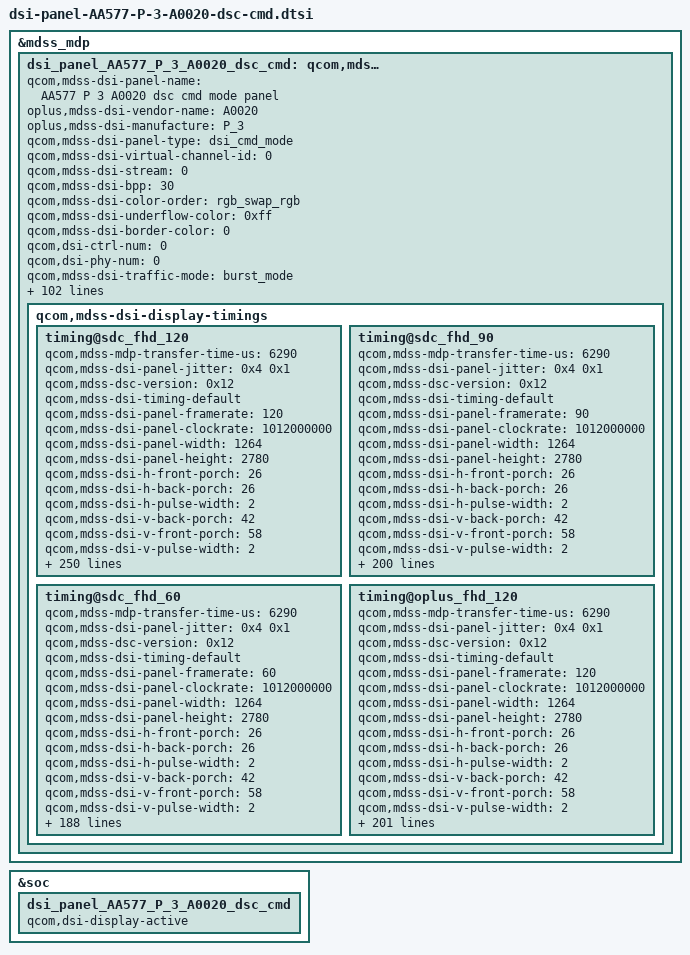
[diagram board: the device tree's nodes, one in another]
&mdss_mdp {
	dsi_panel_AA577_P_3_A0020_dsc_cmd: qcom,mdss_dsi_panel_AA577_P_3_A0020_dsc_cmd {
		qcom,mdss-dsi-panel-name = "AA577 P 3 A0020 dsc cmd mode panel";
		oplus,mdss-dsi-vendor-name = "A0020";
		oplus,mdss-dsi-manufacture = "P_3";
		qcom,mdss-dsi-panel-type = "dsi_cmd_mode";
		qcom,mdss-dsi-virtual-channel-id = <0>;
		qcom,mdss-dsi-stream = <0>;
		qcom,mdss-dsi-bpp = <30>;
		qcom,mdss-dsi-color-order = "rgb_swap_rgb";
		qcom,mdss-dsi-underflow-color = <0xff>;
		qcom,mdss-dsi-border-color = <0>;
		qcom,dsi-ctrl-num = <0>;
		qcom,dsi-phy-num = <0>;
		qcom,mdss-dsi-traffic-mode = "burst_mode";
		qcom,mdss-dsi-lane-map = "lane_map_0123";
		qcom,mdss-dsi-bllp-eof-power-mode;
		qcom,mdss-dsi-bllp-power-mode;
		qcom,mdss-dsi-lane-0-state;
		qcom,mdss-dsi-lane-1-state;
		qcom,mdss-dsi-lane-2-state;
		qcom,mdss-dsi-lane-3-state;
		qcom,mdss-dsi-dma-trigger = "trigger_sw";
		qcom,mdss-dsi-dma-schedule-line = <1>;
		qcom,mdss-dsi-dma-schedule-window = <10>;
		qcom,mdss-dsi-mdp-trigger = "none";
		qcom,mdss-dsi-reset-sequence = <1 2>, <0 5>, <1 25>;
		qcom,mdss-dsi-te-pin-select = <1>;
		qcom,mdss-dsi-te-dcs-command = <1>;
		qcom,mdss-pan-physical-width-dimension = <71>;
		qcom,mdss-pan-physical-height-dimension = <157>;
		qcom,mdss-dsi-init-delay-us = <1000>;
		qcom,mdss-dsi-te-check-enable;
		qcom,mdss-dsi-te-using-te-pin;
		//qcom,mdss-dsi-lp11-init;
		qcom,mdss-dsi-wr-mem-start = <0x2c>;
		qcom,mdss-dsi-wr-mem-continue = <0x3c>;
		qcom,mdss-dsi-panel-jitter = <0x4 0x1>;
		qcom,mdss-bl-high2bit;
		/* HDR Setting */
		qcom,mdss-dsi-panel-hdr-enabled;
		qcom,mdss-dsi-panel-hdr-color-primaries = <15635 16450 34000 16000 13250 34500 7500 3000>;
		qcom,mdss-dsi-panel-peak-brightness = <5400000>;
		qcom,mdss-dsi-panel-average-brightness = <2000000>;
		qcom,mdss-dsi-panel-blackness-level = <4000>;

		qcom,esd-check-enabled;
		oplus,esd-check-flag-enabled;
		qcom,mdss-dsi-panel-status-check-mode = "reg_read";
		qcom,mdss-dsi-panel-status-command = [
				06 01 00 01 05 00 02 0A 00
			];
		qcom,mdss-dsi-panel-status-command-state = "dsi_lp_mode";
		qcom,mdss-dsi-panel-status-value = <
				0x9C
		>;
		qcom,mdss-dsi-panel-status-read-length = <1>;
		oplus,mdss-dsi-panel-status-match-modes = <0x00000000>;
		qcom,dynamic-mode-switch-enabled;
		qcom,dynamic-mode-switch-type = "dynamic-resolution-switch-immediate";
		qcom,mdss-dsi-display-timings {
			timing@sdc_fhd_120 {
				#include "dsi-panel-AA577-P-3-A0020-common-effect.dtsi"
				#include "dsi-panel-AA577-P-3-A0020-common.dtsi"
				qcom,mdss-mdp-transfer-time-us = <6290>;
				qcom,mdss-dsi-panel-jitter = <0x4 0x1>;
				qcom,mdss-dsc-version = <0x12>;
				qcom,mdss-dsi-timing-default;
				qcom,mdss-dsi-panel-framerate = <120>;
				qcom,mdss-dsi-panel-clockrate = <1012000000>;
				qcom,mdss-dsi-panel-width = <1264>;
				qcom,mdss-dsi-panel-height = <2780>;

				qcom,mdss-dsi-h-front-porch = <26>;
				qcom,mdss-dsi-h-back-porch = <26>;
				qcom,mdss-dsi-h-pulse-width = <2>;
				qcom,mdss-dsi-v-back-porch = <42>;
				qcom,mdss-dsi-v-front-porch = <58>;
				qcom,mdss-dsi-v-pulse-width = <2>;
				qcom,mdss-dsi-h-sync-pulse = <0>;

				oplus,ofp-need-to-sync-data-in-aod-unlocking;
				oplus,ofp-aod-off-insert-black-frame = <1>;
				oplus,ofp-aod-off-black-frame-total-time = <42>;
				oplus,ofp-need-to-separate-backlight;
				oplus,ofp-backlight-on-period = <1>;

				qcom,mdss-dsi-timing-switch-command = [
						39 00 00 40 00 00 04 FF 5A A5 00
						15 00 00 40 00 00 02 60 00
						/* recover to narrow TE */
						39 00 00 40 00 00 04 FF 5A A5 02
						39 00 00 40 00 00 09 B0 00 80 00 10 00 00 00 00
						39 00 00 40 00 00 04 FF 5A A5 2D
						39 00 00 40 00 00 03 83 00 00
						15 00 00 40 00 00 02 F2 00
						39 00 00 00 00 00 04 FF 5A A5 00
				];
				qcom,mdss-dsi-on-command = [
						39 00 00 40 00 00 04 FF 5A A5 08
						15 00 00 40 00 00 02 C8 62
						39 00 00 40 00 00 04 FF 5A A5 07
						15 00 00 40 00 00 02 8A 01
						39 00 00 40 00 00 03 8B 21 E0
						39 00 00 40 00 00 64 81 00 00 00 00 00 12 00 00 AB 30 80 0A DC 04 F0 00 14 02 78 02 78 02 00 02 57 00 20 01 F8 00 08 00 0D 05 7A 04 4F 18 00 10 E0 07 10 20 00 06 0F 0F 33 0E 1C 2A 38 46 54 62 69 70 77 79 7B 7D 7E 02 02 22 00 2A 40 2A BE 3A FC 3A FA 3A F8 3B 38 3B 78 3B B6 4B B6 4B F4 4B F4 6C 34 84 74 00 00 00 00 00 00
						// CTB optimize
						39 00 00 40 00 00 04 FF 5A A5 31
						15 00 00 40 00 00 02 D0 81
						15 00 00 40 01 00 02 A0 A3
						39 00 00 40 00 00 13 84 F0 98 62 24 02 FE DC 9E 68 F0 25 21 28 02 FE DF CA 65
						39 00 00 40 01 00 13 85 F0 6F 47 1B 02 FE E5 B9 91 F0 27 22 2A 02 FE DE EB AC
						15 00 00 40 00 00 02 D0 80
						39 00 00 40 00 00 04 FF 5A A5 21
						15 00 00 40 00 00 02 A4 18
						39 00 00 40 00 00 04 FF 5A A5 2D
						15 00 00 40 00 00 02 F2 00
						39 00 00 40 00 00 03 83 00 00
						39 00 00 40 00 00 03 84 00 00
						39 00 00 40 00 00 03 85 00 00
						39 00 00 40 00 00 03 86 00 00
						39 00 00 40 00 00 04 FF 5A A5 00
						15 00 00 40 00 00 02 5A 01
						15 00 00 40 00 00 02 5B 80
						39 00 00 40 00 00 04 FF 5A A5 02
						15 00 00 40 00 00 02 C0 03
						39 00 00 40 00 00 04 FF 5A A5 2D //Page 2D
						15 00 00 40 00 00 02 CE D4
						39 00 00 40 00 00 04 EC 01 AF 00
						39 00 00 40 00 00 03 93 A0 00
						39 00 00 40 00 00 03 94 C4 00
						39 00 00 40 00 00 03 95 00 00
						39 00 00 40 00 00 03 96 00 00
						39 00 00 40 00 00 03 ED D5 00
						39 00 00 40 00 00 04 EE 00 00 00
						15 00 00 40 00 00 02 97 02
						15 00 00 40 00 00 02 B1 03
						39 00 00 40 00 00 03 98 05 00
						39 00 00 40 00 00 03 99 0B 00
						39 00 00 40 00 00 03 9A 17 00
						39 00 00 40 00 00 03 9B 77 00
						39 00 00 40 00 00 05 A0 01 01 00 00
						39 00 00 40 00 00 05 A1 02 00 00 00
						15 00 00 40 00 00 02 B2 02
						15 00 00 40 00 00 02 B3 05
						15 00 00 40 00 00 02 B4 08
						15 00 00 40 00 00 02 B5 11
						39 00 00 40 00 00 03 BA 00 00
						39 00 00 40 00 00 03 BB 01 02
						39 00 00 40 00 00 04 FF 5A A5 02
						39 00 00 40 00 00 09 B0 00 80 00 10 00 00 00 00
						39 00 00 40 00 00 04 FF 5A A5 00
						15 00 00 40 00 00 02 5E 01
						15 00 00 40 00 00 02 60 00
						15 00 00 40 00 00 02 61 07
						15 00 00 40 00 00 02 35 00
						15 00 00 40 00 00 02 53 20
						//ODC 2024/8/3
						39 00 00 40 00 00 04 FF 5A A5 49
						15 00 00 40 00 00 02 D9 02
						15 00 00 40 00 00 02 DA F7
						15 00 00 40 00 00 02 DB 9C
						15 00 00 40 00 00 02 DF 06
						39 00 00 40 00 00 04 FF 5A A5 5A
						39 00 00 40 00 00 04 81 FD 00 00
						39 00 00 40 00 00 04 83 03 15 05
						39 00 00 40 00 00 04 84 02 FD 01
						39 00 00 40 00 00 04 85 02 FD 01
						39 00 00 40 00 00 04 86 12 2B 1A
						39 00 00 40 00 00 04 87 0A FD 05
						39 00 00 40 00 00 04 88 08 FD 04
						39 00 00 40 00 00 04 89 03 FD 06
						39 00 00 40 00 00 04 8A 16 31 27
						39 00 00 40 00 00 04 8D 06 05 15
						39 00 00 40 00 00 04 8E 01 05 05
						39 00 00 40 00 00 04 93 FA 06 06
						39 00 00 40 00 00 04 94 FA 05 00
						39 00 00 40 00 00 04 95 32 50 3C
						39 00 00 40 00 00 04 A4 03 01 02
						39 00 00 40 00 00 04 A5 08 0D 0A
						39 00 00 40 00 00 04 A6 00 00 00
						39 00 00 40 00 00 04 A7 06 0D 0A
						39 00 00 40 00 00 04 A9 01 00 00
						39 00 00 40 00 00 04 B5 07 06 05
						39 00 00 40 00 00 04 B6 02 01 01
						39 00 00 40 00 00 04 B7 F9 F3 08
						39 00 00 40 00 00 04 B8 F7 F4 08
						39 00 00 40 00 00 04 C9 03 08 05
						39 00 00 40 00 00 04 CB 04 09 05
						39 00 00 40 00 00 04 D9 08 08 06
						39 00 00 40 00 00 04 DA 02 02 01
						39 00 00 40 00 00 04 DB F7 F6 01
						39 00 00 40 00 00 04 DC F7 F6 01
						39 00 00 40 00 00 04 FF 5A A5 5B
						39 00 00 40 00 00 04 80 01 0D 07
						39 00 00 40 00 00 04 81 04 08 05
						39 00 00 40 00 00 04 83 06 09 06
						39 00 00 40 00 00 04 93 06 06 06
						39 00 00 40 00 00 04 94 FC FC FC
						39 00 00 40 00 00 04 9A 06 07 05
						39 00 00 40 00 00 04 9B 04 04 03
						39 00 00 40 00 00 04 A5 03 0C 08
						39 00 00 40 00 00 04 A7 04 0D 07
						39 00 00 40 00 00 04 B5 FE FD FC
						39 00 00 40 00 00 04 B6 FB FA FA
						39 00 00 40 00 00 04 B7 F6 F6 F6
						39 00 00 40 00 00 04 C9 03 07 05
						39 00 00 40 00 00 04 CA 00 02 00
						39 00 00 40 00 00 04 CB 04 09 05
						39 00 00 40 00 00 04 DB 01 06 06
						39 00 00 40 00 00 04 DC 01 05 06
						39 00 00 40 00 00 04 E2 05 05 05
						39 00 00 40 00 00 04 E3 03 04 03
						39 00 00 40 00 00 04 FF 5A A5 5C
						39 00 00 40 00 00 04 80 04 04 05
						39 00 00 40 00 00 04 81 02 05 01
						39 00 00 40 00 00 04 83 04 04 06
						39 00 00 40 00 00 04 94 01 01 06
						39 00 00 40 00 00 04 9A 06 0C 0B
						39 00 00 40 00 00 04 9B 06 0C 0C
						39 00 00 40 00 00 04 A5 03 05 04
						39 00 00 40 00 00 04 B7 FA 02 04
						39 00 00 40 00 00 04 B8 FA 02 00
						39 00 00 40 00 00 04 BE 03 06 03
						39 00 00 40 00 00 04 BF 03 06 02
						39 00 00 00 00 00 04 FF 5A A5 00
						//CTB 2024/8/3
						39 00 00 40 00 00 04 FF 5A A5 31
						15 00 00 40 01 00 02 D0 81
						39 00 00 40 00 00 13 80 F0 99 62 25 02 FE DB 9E 67 E0 1A 17 16 00 00 DF C8 C4
						39 00 00 40 00 00 13 81 F0 9C 65 25 02 FE DB 9B 64 E0 09 08 05 00 00 FD F4 EC
						39 00 00 40 00 00 13 82 F0 81 53 1F 02 FE E1 AD 7F E0 07 06 05 00 00 FD FC FB
						39 00 00 40 00 00 13 83 F0 70 48 1B 02 FE E5 B8 90 E0 07 06 05 00 00 FD FC FB
						39 00 00 40 00 00 13 84 F0 94 60 23 02 FE DD A0 6C E0 06 05 04 00 00 FB FA F9
						39 00 00 40 00 00 13 85 F0 7C 50 1E 02 FE E2 B0 84 E0 06 05 04 00 00 FB FA F9
						39 00 00 40 00 00 13 86 F0 99 62 25 02 FE DB 9E 67 E0 1A 17 16 00 00 CD C8 C4
						39 00 00 40 00 00 13 87 F0 9C 65 25 02 FE DB 9B 64 E0 09 08 05 00 00 FD F4 EC
						39 00 00 40 00 00 13 88 F0 81 53 1F 02 FE E1 AD 7F E0 07 06 05 00 00 FD FC FB
						39 00 00 40 00 00 13 89 F0 70 48 1B 02 FE E5 B8 90 E0 07 06 05 00 00 FD FC FB
						39 00 00 40 00 00 13 8A F0 94 60 23 02 FE DD A0 6C E0 06 05 04 00 00 FB FA F9
						39 00 00 40 00 00 13 8B F0 7C 50 1E 02 FE E2 B0 84 E0 06 05 04 00 00 FB FA F9
						15 00 00 40 01 00 02 D0 80
						39 00 00 40 00 00 07 91 04 44 55 01 01 03
						39 00 00 40 00 00 07 92 04 44 55 01 01 03
						39 00 00 40 00 00 07 93 04 44 55 01 01 03
						15 00 00 40 00 00 02 A6 00
						15 00 00 40 00 00 02 A7 10
						15 00 00 40 00 00 02 A8 00
						15 00 00 40 00 00 02 A9 10
						15 00 00 40 00 00 02 AA 00
						15 00 00 40 00 00 02 AB 10
						39 00 00 40 00 00 04 FF 5A A5 00
						//CCTC 2024/8/3
						39 00 00 40 00 00 04 FF 5A A5 2B
						39 00 00 40 00 00 05 AA 30 F7 00 00
						39 00 00 40 00 00 05 AD 30 F9 00 00
						39 00 00 40 00 00 05 B0 30 FA 00 00
						39 00 00 40 00 00 05 C4 0F 04 FB F1
						39 00 00 40 00 00 05 C5 3F DE E4 E4
						39 00 00 40 00 00 05 C7 3F F8 FD F5
						39 00 00 40 00 00 05 C8 3F E2 E9 E9
						39 00 00 40 00 00 05 CA 0F 02 E5 E8
						39 00 00 40 00 00 05 CB 3F ED EF ED
						39 00 00 40 00 00 05 CD 03 02 00 FB
						39 00 00 40 00 00 05 DF 0F 04 F1 F6
						39 00 00 40 00 00 05 E0 3F D2 EB EE
						39 00 00 40 00 00 05 E2 3F F5 F0 F8
						39 00 00 40 00 00 05 E3 3F E2 EE E2
						39 00 00 40 00 00 05 E6 3F FE F3 F4
						39 00 00 40 00 00 05 E9 3F FD F7 F5
						39 00 00 40 00 00 05 EC 3F FD FA F7
						39 00 00 00 00 00 04 FF 5A A5 00
						//Resolving 60Hz stuttering
						39 00 00 40 00 00 04 FF 5A A5 00
						39 00 00 40 00 00 02 5A 01
						39 00 00 40 00 00 02 5B 80
						39 00 00 40 00 00 04 FF 5A A5 02
						39 00 00 40 00 00 02 C0 03
						39 00 00 40 00 00 04 FF 5A A5 2D
						39 00 00 40 00 00 04 EC 01 AF 00
						39 00 00 40 00 00 03 93 A0 00
						39 00 00 40 00 00 03 94 C4 00
						39 00 00 40 00 00 03 95 00 00
						39 00 00 40 00 00 03 96 00 00
						39 00 00 40 00 00 03 ED D5 00
						39 00 00 40 00 00 04 EE 00 00 00
						39 00 00 40 00 00 02 97 02
						39 00 00 40 00 00 02 B1 03
						39 00 00 40 00 00 03 98 05 00
						39 00 00 40 00 00 03 99 0B 00
						39 00 00 40 00 00 03 9A 17 00
						39 00 00 40 00 00 03 9B 77 00
						39 00 00 40 00 00 05 A0 01 01 00 00
						39 00 00 40 00 00 05 A1 02 00 00 00
						39 00 00 40 00 00 02 B2 02
						39 00 00 40 00 00 02 B3 05
						39 00 00 40 00 00 02 B4 08
						39 00 00 40 00 00 02 B5 11
						39 00 00 40 00 00 03 BA 00 00
						39 00 00 40 00 00 03 BB 01 02
						39 00 00 40 00 00 04 FF 5A A5 02
						39 00 00 40 00 00 09 B0 00 80 00 10 00 00 00 00
						//cornor on
						39 00 00 40 00 00 04 FF 5A A5 17
						15 00 00 40 00 00 02 A0 8C
						// switch 120HZ
						39 00 00 40 00 00 04 FF 5A A5 00
						15 00 00 40 00 00 02 60 00
						39 00 00 40 00 00 04 FF 5A A5 2D
						39 00 00 40 00 00 03 83 00 00
						15 00 00 40 00 00 02 F2 00
						39 00 00 40 00 00 04 FF 5A A5 00
						05 00 00 00 78 00 01 11
						39 00 00 40 00 00 04 FF 5A A5 23
						15 00 00 40 00 00 02 CB 01
						39 00 00 40 00 00 04 FF 5A A5 65
						39 00 00 40 00 00 09 98 00 00 41 05 00 00 41 05
						39 00 00 40 00 00 09 99 00 00 41 05 00 00 41 05
						39 00 00 40 00 00 09 9A 00 00 41 05 00 00 41 05
						39 00 00 40 00 00 09 9B 00 00 01 1E 00 00 64 1E
						39 00 00 40 00 00 09 9C 00 00 76 1E 00 00 D8 1E
						39 00 00 40 00 00 09 9D 00 00 EA 1E 00 01 32 1E
						39 00 00 40 00 00 09 9E 00 01 32 1E 00 01 32 1E
						39 00 00 40 00 00 09 9F 00 01 40 1E 00 01 C0 1E
						39 00 00 40 00 00 09 A0 00 01 D0 1E 00 02 CE 1E
						39 00 00 40 00 00 09 A1 00 02 CE 1E 00 03 98 1E
						39 00 00 40 00 00 09 A2 00 03 98 1E 00 04 2E 1E
						39 00 00 40 00 00 09 A3 00 04 2E 1E 00 04 B0 1E
						39 00 00 40 00 00 09 A4 00 04 B0 1E 00 04 B0 1E
						39 00 00 40 00 00 09 A5 00 04 B0 1E 00 04 B0 1E
						39 00 00 40 00 00 09 A6 00 04 B0 1E 00 04 B0 1E
						39 00 00 40 00 00 09 A7 00 04 B0 1E 00 04 B0 1E
						39 00 00 40 00 00 09 A8 00 04 B0 1E 00 04 B0 1E
						39 00 00 40 00 00 09 A9 00 04 B0 1E 00 04 B0 1E
						39 00 00 40 00 00 09 AA 00 04 B0 1E 00 04 B0 1E
						39 00 00 40 00 00 09 AB 00 04 B0 1E 00 04 B0 1E
						39 00 00 40 00 00 09 AC 00 04 B0 1E 00 04 B0 1E
						39 00 00 40 00 00 09 AD 00 04 B0 1E 00 04 B0 1E
						39 00 00 40 00 00 09 AE 00 04 B0 1E 00 04 B0 1E
						39 00 00 40 00 00 09 AF 00 04 B0 1E 00 04 B0 1E
						39 00 00 40 00 00 04 FF 5A A5 75
						39 00 00 40 00 00 09 98 00 00 00 00 00 00 0F 00
						39 00 00 40 00 00 09 99 00 00 00 00 00 00 0F 00
						39 00 00 40 00 00 09 9A 00 00 00 00 00 00 0F 00
						39 00 00 40 00 00 09 9B 00 00 00 00 00 00 10 00
						39 00 00 40 00 00 09 9C 00 00 00 00 00 00 10 00
						39 00 00 40 00 00 09 9D 00 00 00 00 00 00 10 00
						39 00 00 40 00 00 09 9E 00 00 00 00 00 00 10 00
						39 00 00 40 00 00 09 9F 00 00 00 00 00 00 10 00
						39 00 00 40 00 00 09 A0 00 00 00 00 00 00 10 00
						39 00 00 40 00 00 09 A1 00 00 00 00 00 00 10 00
						39 00 00 40 00 00 09 A2 00 00 00 00 00 00 10 00
						39 00 00 40 00 00 09 A3 00 00 00 00 00 00 10 00
						39 00 00 40 00 00 09 A4 00 00 00 00 00 00 10 00
						39 00 00 40 00 00 09 A5 00 00 00 00 00 00 10 00
						39 00 00 40 00 00 09 A6 00 00 00 00 00 00 10 00
						39 00 00 40 00 00 09 A7 00 00 00 00 00 00 10 00
						39 00 00 40 00 00 09 A8 00 00 00 00 00 00 10 00
						39 00 00 40 00 00 09 A9 00 00 00 00 00 00 10 00
						39 00 00 40 00 00 09 AA 00 00 00 00 00 00 10 00
						39 00 00 40 00 00 09 AB 00 00 00 00 00 00 10 00
						39 00 00 40 00 00 09 AC 00 00 00 00 00 00 10 00
						39 00 00 40 00 00 09 AD 00 00 00 00 00 00 10 00
						39 00 00 40 00 00 09 AE 00 00 00 00 00 00 10 00
						39 00 00 40 00 00 09 AF 00 00 00 00 00 00 10 00
						39 00 00 40 00 00 04 FF 5A A5 23
						15 00 00 00 00 00 02 CB 00
						05 00 00 00 14 00 01 29
				];

				qcom,mdss-dsi-post-on-backlight = [
				];
				qcom,mdss-dsi-off-command=[
					05 00 00 00 14 00 01 28
					05 00 00 00 78 00 01 10
				];
				qcom,mdss-dsi-hbm-off-command = [
					39 00 00 00 00 00 03 51 0D BB
				];
				qcom,mdss-dsi-hbm-on-command = [
					39 00 00 40 00 00 04 FF 5A A5 1E
					39 00 00 40 00 00 02 80 89
					39 00 00 40 00 00 04 FF 5A A5 00
					39 00 00 00 00 00 03 51 0F 4A
				];
				qcom,mdss-dsi-panel-read-register-open-command = [
				];
				qcom,mdss-dsi-panel-read-register-close-command = [
				];
				qcom,mdss-dsi-lhbm-pressed-icon-gamma-command = [
				];
				qcom,mdss-dsi-lhbm-pressed-icon-grayscale-command = [
				];
				qcom,mdss-dsi-lhbm-pressed-icon-on-command = [
					39 00 00 40 00 00 04 FF 5A A5 00
					39 00 00 40 00 00 02 96 09
					39 00 00 40 00 00 02 97 D9
					39 00 00 40 00 00 02 98 02
					39 00 00 40 00 00 02 99 78
					39 00 00 00 00 00 02 6E 03
				];
				qcom,mdss-dsi-lhbm-pressed-icon-off-command = [
					39 00 00 40 00 00 04 FF 5A A5 00
					39 00 00 00 00 00 02 6E 00
				];
				qcom,mdss-dsi-lhbm-dbv-alpha-command = [
				];
				qcom,mdss-dsi-lp1-command = [
					39 00 00 40 00 00 04 FF 5A A5 4F
					15 00 00 40 00 00 02 88 78
					39 00 00 40 00 00 04 FF 5A A5 00
					15 00 00 40 00 00 02 60 00
					39 00 00 40 00 00 04 FF 5A A5 53
					39 00 00 40 00 00 03 85 CC E1
					39 00 00 40 00 00 04 FF 5A A5 01
					39 00 00 40 00 00 06 83 00 00 40 04 00
					15 00 00 40 00 00 02 FE 0B
					39 00 00 40 00 00 04 FF 5A A5 0B
					15 00 00 40 00 00 02 88 00
					15 00 00 40 00 00 02 A7 00
					39 00 00 40 00 00 04 FF 5A A5 51
					39 00 00 40 00 00 06 C2 46 46 46 46 00
					15 00 00 40 00 00 02 FE 00
					15 00 00 40 00 00 02 00 00
					39 00 00 40 00 00 04 FF 5A A5 00
					15 00 00 40 00 00 02 39 00
					39 00 00 40 00 00 04 FF 5A A5 4F
					15 00 00 40 00 00 02 8B 78
					/* AOD lv switch */
					39 00 00 40 00 00 04 FF 5A A5 00
					39 00 00 00 00 00 05 51 0D BB 0D BB
				];
				qcom,mdss-dsi-nolp-command = [
					39 00 00 40 00 00 04 FF 5A A5 00
					15 00 00 40 00 00 02 38 00
					39 00 00 00 00 00 05 51 00 00 00 00
				];
				qcom,mdss-dsi-nolp-onepulse-command = [
					39 00 00 40 00 00 04 FF 5A A5 4F
					15 00 00 40 00 00 02 88 78
					39 00 00 40 00 00 04 FF 5A A5 01
					39 00 00 40 00 00 03 80 0C 0C
					39 00 00 40 00 00 04 FF 5A A5 4F
					15 00 00 40 00 00 02 8A 78
					39 00 00 40 00 00 04 FF 5A A5 00
					15 00 00 40 00 00 02 60 01
					39 00 00 40 00 00 04 FF 5A A5 53
					39 00 00 40 00 00 03 85 CC E3
					39 00 00 40 00 00 04 FF 5A A5 01
					39 00 00 40 00 00 06 83 00 00 40 04 00
					15 00 00 40 00 00 02 FE 07
					39 00 00 40 00 00 04 FF 5A A5 0B
					15 00 00 40 00 00 02 88 46
					15 00 00 40 00 00 02 A7 3A
					39 00 00 40 00 00 04 FF 5A A5 51
					39 00 00 40 00 00 06 C2 46 28 28 28 00
					15 00 00 40 00 00 02 FE 00
					15 00 00 40 00 00 02 00 00
					39 00 00 40 00 00 04 FF 5A A5 01
					39 00 00 40 00 00 03 80 0C 00
					39 00 00 40 00 00 04 FF 5A A5 00
					15 00 00 40 00 00 02 38 00
					39 00 00 40 00 00 04 FF 5A A5 4F
					15 00 00 40 00 00 02 8B 78
					39 00 00 40 00 00 04 FF 5A A5 00
					39 00 00 00 00 00 05 51 00 00 00 00
				];
				qcom,mdss-dsi-aod-high-mode-command = [
					39 00 00 40 00 00 04 FF 5A A5 00
					39 00 00 00 00 00 05 51 0D BB 0D BB
				];
				qcom,mdss-dsi-aod-low-mode-command = [
					39 00 00 40 00 00 04 FF 5A A5 00
					39 00 00 00 00 00 05 51 0B 1A 0A 81
				];
				qcom,mdss-dsi-ultra-low-power-aod-on-command = [
					39 00 00 40 00 00 04 FF 5A A5 2D
					39 00 00 40 00 00 03 8A 1D 00
					39 00 00 00 00 00 04 FF 5A A5 00
				];
				qcom,mdss-dsi-ultra-low-power-aod-off-command = [
					39 00 00 40 00 00 04 FF 5A A5 2D
					39 00 00 40 00 00 03 8A 00 00
					39 00 00 00 00 00 04 FF 5A A5 00
				];
				qcom,mdss-dsi-temperature-compensation-command = [
				];
				qcom,mdss-dsi-read-compensation-reg1-command = [
				];
				qcom,mdss-dsi-pwm-switch-high-command = [
					39 00 00 40 00 00 04 FF 5A A5 4F
					15 00 00 40 00 00 02 80 01
					15 00 00 40 00 00 02 81 04
					15 00 00 40 00 00 02 88 78
					39 00 00 40 00 00 04 FF 5A A5 00
					39 00 00 40 00 00 03 51 04 8B
					39 00 00 40 00 00 04 FF 5A A5 24
					39 00 00 40 00 00 06 C9 00 00 00 10 00
					39 00 00 40 00 00 04 FE 30 00 50
					39 00 00 40 00 00 06 CA 00 80 00 B0 00
					39 00 00 40 00 00 04 FE D0 01 10
					39 00 00 40 00 00 06 CB 01 50 01 78 01
					39 00 00 40 00 00 04 FE D0 02 98
					39 00 00 40 00 00 06 CC 03 20 04 40 05
					39 00 00 40 00 00 04 FE 20 05 E8
					39 00 00 40 00 00 06 CD 06 F0 07 C8 09
					39 00 00 40 00 00 04 FE 30 0A A8
					39 00 00 40 00 00 06 CE 0B 70 0C D8 0E
					39 00 00 40 00 00 04 FE F0 0F F0
					39 00 00 40 00 00 04 FF 5A A5 4F
					15 00 00 40 00 00 02 8A 78
					39 00 00 40 00 00 04 FF 5A A5 24
					39 00 00 40 00 00 06 C9 00 00 00 10 00
					39 00 00 40 00 00 04 FE 30 00 50
					39 00 00 40 00 00 06 CA 00 80 00 B0 00
					39 00 00 40 00 00 04 FE D0 01 10
					39 00 00 40 00 00 06 CB 01 50 01 B0 02
					39 00 00 40 00 00 04 FE 10 02 B0
					39 00 00 40 00 00 06 CC 03 70 04 70 05
					39 00 00 40 00 00 04 FE 70 06 30
					39 00 00 40 00 00 06 CD 07 10 08 10 09
					39 00 00 40 00 00 04 FE 80 0A F0
					39 00 00 40 00 00 06 CE 0B A0 0D 10 0E
					39 00 00 40 00 00 04 FE F0 0F F0
					39 00 00 40 00 00 04 FF 5A A5 4F
					15 00 00 00 00 00 02 8B 78
				];
				qcom,mdss-dsi-pwm-switch-low-command = [
					39 00 00 40 00 00 04 FF 5A A5 4F
					15 00 00 40 00 00 02 80 01
					15 00 00 40 00 00 02 81 04
					15 00 00 40 00 00 02 88 78
					39 00 00 40 00 00 04 FF 5A A5 00
					39 00 00 40 00 00 03 51 04 8A
					39 00 00 40 00 00 04 FF 5A A5 24
					39 00 00 40 00 00 06 C9 00 00 00 10 00
					39 00 00 40 00 00 04 FE 30 00 50
					39 00 00 40 00 00 06 CA 00 80 00 B0 00
					39 00 00 40 00 00 04 FE D0 01 20
					39 00 00 40 00 00 06 CB 01 68 01 A0 02
					39 00 00 40 00 00 04 FE 28 02 D0
					39 00 00 40 00 00 06 CC 03 60 04 A0 05
					39 00 00 40 00 00 04 FE B0 06 78
					39 00 00 40 00 00 06 CD 07 30 08 50 09
					39 00 00 40 00 00 04 FE E0 0B 44
					39 00 00 40 00 00 06 CE 0B D8 0D 10 0E
					39 00 00 40 00 00 04 FE F0 0F F0
					39 00 00 40 00 00 04 FF 5A A5 4F
					15 00 00 40 00 00 02 8A 78
					39 00 00 40 00 00 04 FF 5A A5 24
					39 00 00 40 00 00 06 C9 00 00 00 10 00
					39 00 00 40 00 00 04 FE 30 00 50
					39 00 00 40 00 00 06 CA 00 80 00 B0 00
					39 00 00 40 00 00 04 FE D0 01 10
					39 00 00 40 00 00 06 CB 01 50 01 B0 02
					39 00 00 40 00 00 04 FE 10 02 B0
					39 00 00 40 00 00 06 CC 03 70 04 70 05
					39 00 00 40 00 00 04 FE 70 06 30
					39 00 00 40 00 00 06 CD 07 10 08 10 09
					39 00 00 40 00 00 04 FE 80 0A F0
					39 00 00 40 00 00 06 CE 0B A0 0D 10 0E
					39 00 00 40 00 00 04 FE F0 0F F0
					39 00 00 40 00 00 04 FF 5A A5 4F
					15 00 00 00 00 00 02 8B 78
				];
				qcom,mdss-dsi-pwm-switch-onepulse-command = [
				];
				qcom,mdss-dsi-pwm-switch-onepulse-low-command = [
				];
				qcom,mdss-dsi-pwm-switch-1to3-command = [
					39 00 00 40 00 00 04 FF 5A A5 4F
					15 00 00 40 00 00 02 88 78
					39 00 00 40 00 00 04 FF 5A A5 01
					39 00 00 40 00 00 06 83 00 00 40 04 00
					15 00 00 40 00 00 02 FE 0B
					39 00 00 40 00 00 04 FF 5A A5 0B
					15 00 00 40 00 00 02 88 00
					15 00 00 40 00 00 02 A7 00
					39 00 00 40 00 00 04 FF 5A A5 51
					39 00 00 40 00 00 06 C2 46 46 46 46 00
					15 00 00 40 00 00 02 FE 00
					15 00 00 40 00 00 02 00 00
					39 00 00 40 00 00 06 A0 98 98 A4 A8 22
					15 00 00 40 00 00 02 FE 22
					15 00 00 40 00 00 02 00 00
					39 00 00 40 00 00 06 A1 CC D0 D0 A2 22
					15 00 00 40 00 00 02 FE 22
					15 00 00 40 00 00 02 00 00
					39 00 00 40 00 00 06 A2 A4 A6 99 9A 22
					15 00 00 40 00 00 02 FE 22
					15 00 00 40 00 00 02 00 00
					39 00 00 40 00 00 04 FF 5A A5 52
					39 00 00 40 00 00 06 80 DA BC 58 B1 11
					15 00 00 40 00 00 02 FE 01
					15 00 00 40 00 00 02 00 00
					39 00 00 40 00 00 06 81 4D 4D 4D 4E 00
					15 00 00 40 00 00 02 FE 00
					15 00 00 40 00 00 02 00 00
					39 00 00 40 00 00 06 82 4D 4E 4D 4D 00
					15 00 00 40 00 00 02 FE 00
					15 00 00 40 00 00 02 00 00
					39 00 00 40 00 00 04 FF 5A A5 00
					15 00 00 40 00 00 02 60 00
					39 00 00 40 00 00 04 FF 5A A5 4F
					15 00 00 40 00 00 02 8B 78
					39 00 00 40 00 00 04 FF 5A A5 53
					15 00 00 40 00 00 02 F0 01
					39 00 00 40 00 00 04 FF 5A A5 63
					39 00 00 40 00 00 11 F1 00 00 00 00 00 00 00 00 00 00 00 00 00 00 00 00
					39 00 00 40 00 00 11 F2 10 10 10 10 10 00 00 00 00 00 00 00 00 00 00 00
					39 00 00 40 00 00 11 F3 00 00 00 00 00 20 20 20 20 20 00 00 00 00 00 00
					39 00 00 40 00 00 11 F4 00 00 00 00 00 FF FF FF FF FF 00 00 00 00 00 00
					39 00 00 40 00 00 04 FF 5A A5 53
					15 00 00 40 00 00 02 F0 00
					39 00 00 00 00 00 04 FF 5A A5 00
				];
				qcom,mdss-dsi-pwm-switch-3to1-command = [
					39 00 00 40 00 00 04 FF 5A A5 4F
					15 00 00 40 00 00 02 88 78
					39 00 00 40 00 00 04 FF 5A A5 01
					39 00 00 40 00 00 03 80 0C 0C
					39 00 00 40 00 00 04 FF 5A A5 4F
					15 00 00 40 00 00 02 8A 78
					39 00 00 40 00 00 04 FF 5A A5 01
					39 00 00 40 00 00 06 83 00 00 40 04 00
					15 00 00 40 00 00 02 FE 07
					39 00 00 40 00 00 04 FF 5A A5 0B
					15 00 00 40 00 00 02 88 46
					15 00 00 40 00 00 02 A7 3A
					39 00 00 40 00 00 04 FF 5A A5 51
					39 00 00 40 00 00 06 C2 46 28 28 28 00
					15 00 00 40 00 00 02 FE 00
					15 00 00 40 00 00 02 00 00
					39 00 00 40 00 00 06 A0 98 98 6C 69 22
					15 00 00 40 00 00 02 FE 22
					15 00 00 40 00 00 02 00 00
					39 00 00 40 00 00 06 A1 8C 91 91 74 22
					15 00 00 40 00 00 02 FE 22
					15 00 00 40 00 00 02 00 00
					39 00 00 40 00 00 06 A2 68 72 72 72 22
					15 00 00 40 00 00 02 FE 22
					15 00 00 40 00 00 02 00 00
					39 00 00 40 00 00 04 FF 5A A5 52
					// VRR
					39 00 00 40 00 00 06 80 DA BC 49 A5 11
					15 00 00 40 00 00 02 FE 01
					15 00 00 40 00 00 02 00 00
					39 00 00 40 00 00 06 81 3D 3E 3E 3F 00
					15 00 00 40 00 00 02 FE 00
					15 00 00 40 00 00 02 00 00
					39 00 00 40 00 00 06 82 41 23 23 23 00
					15 00 00 40 00 00 02 FE 00
					15 00 00 40 00 00 02 00 00
					39 00 00 40 00 00 04 FF 5A A5 00
					15 00 00 40 00 00 02 60 01
					39 00 00 40 00 00 04 FF 5A A5 01
					39 00 00 40 00 00 03 80 0C 00
					39 00 00 40 00 00 04 FF 5A A5 4F
					15 00 00 40 00 00 02 8B 78
					39 00 00 40 00 00 04 FF 5A A5 53
					15 00 00 40 00 00 02 F0 01
					39 00 00 40 00 00 04 FF 5A A5 63
					39 00 00 40 00 00 11 F1 20 20 20 20 20 20 20 20 20 20 00 00 00 00 00 00
					39 00 00 40 00 00 11 F2 00 00 00 00 00 00 00 00 00 00 00 00 00 00 00 00
					39 00 00 40 00 00 11 F3 00 00 00 00 00 00 00 00 00 00 00 00 00 00 00 00
					39 00 00 40 00 00 11 F4 FF FF FF FF FF FF FF FF FF FF 00 00 00 00 00 00
					39 00 00 40 00 00 04 FF 5A A5 53
					15 00 00 40 00 00 02 F0 00
					39 00 00 00 00 00 04 FF 5A A5 00
				];
				qcom,mdss-dsi-timming-pwm-switch-onepulse-command = [
					39 00 00 40 00 00 04 FF 5A A5 00
					15 00 00 40 00 00 02 60 01
					39 00 00 40 00 00 04 FF 5A A5 2D
					39 00 00 40 00 00 03 84 00 00
					15 00 00 40 00 00 02 CE D4
					15 00 00 40 00 00 02 F2 00
					39 00 00 00 00 00 04 FF 5A A5 00
				];
				qcom,mdss-dsi-power-on-pwm-switch-onepulse-command = [
					39 00 00 40 00 00 04 FF 5A A5 4F
					15 00 00 40 00 00 02 88 78
					39 00 00 40 00 00 04 FF 5A A5 01
					39 00 00 40 00 00 03 80 0C 0C
					39 00 00 40 00 00 04 FF 5A A5 4F
					15 00 00 40 00 00 02 8A 78
					39 00 00 40 00 00 04 FF 5A A5 01
					39 00 00 40 00 00 06 83 00 00 40 04 00
					15 00 00 40 00 00 02 FE 07
					39 00 00 40 00 00 04 FF 5A A5 0B
					15 00 00 40 00 00 02 88 46
					15 00 00 40 00 00 02 A7 3A
					39 00 00 40 00 00 04 FF 5A A5 51
					39 00 00 40 00 00 06 C2 46 28 28 28 00
					15 00 00 40 00 00 02 FE 00
					15 00 00 40 00 00 02 00 00
					39 00 00 40 00 00 06 A0 98 98 6C 69 22
					15 00 00 40 00 00 02 FE 22
					15 00 00 40 00 00 02 00 00
					39 00 00 40 00 00 06 A1 8C 91 91 74 22
					15 00 00 40 00 00 02 FE 22
					15 00 00 40 00 00 02 00 00
					39 00 00 40 00 00 06 A2 68 72 72 72 22
					15 00 00 40 00 00 02 FE 22
					15 00 00 40 00 00 02 00 00
					39 00 00 40 00 00 04 FF 5A A5 52
					// VRR
					39 00 00 40 00 00 06 80 DA BC 49 A5 11
					15 00 00 40 00 00 02 FE 01
					15 00 00 40 00 00 02 00 00
					39 00 00 40 00 00 06 81 3D 3E 3E 3F 00
					15 00 00 40 00 00 02 FE 00
					15 00 00 40 00 00 02 00 00
					39 00 00 40 00 00 06 82 41 23 23 23 00
					15 00 00 40 00 00 02 FE 00
					15 00 00 40 00 00 02 00 00
					39 00 00 40 00 00 04 FF 5A A5 00
					15 00 00 40 00 00 02 60 01
					39 00 00 40 00 00 04 FF 5A A5 01
					39 00 00 40 00 00 03 80 0C 00
					39 00 00 40 00 00 04 FF 5A A5 4F
					15 00 00 40 00 00 02 8B 78
					39 00 00 40 00 00 04 FF 5A A5 53
					15 00 00 40 00 00 02 F0 01
					39 00 00 40 00 00 04 FF 5A A5 63
					39 00 00 40 00 00 11 F1 20 20 20 20 20 20 20 20 20 20 00 00 00 00 00 00
					39 00 00 40 00 00 11 F2 00 00 00 00 00 00 00 00 00 00 00 00 00 00 00 00
					39 00 00 40 00 00 11 F3 00 00 00 00 00 00 00 00 00 00 00 00 00 00 00 00
					39 00 00 40 00 00 11 F4 FF FF FF FF FF FF FF FF FF FF 00 00 00 00 00 00
					39 00 00 40 00 00 04 FF 5A A5 53
					15 00 00 40 00 00 02 F0 00
					39 00 00 00 10 00 04 FF 5A A5 00
				];
				qcom,mdss-dsi-osc-track-on-command = [
				];
				qcom,mdss-dsi-osc-track-off-command = [
				];
				qcom,mdss-dsi-hbm-max-command = [
					39 00 00 00 00 00 03 51 10 ED
				];

				qcom,mdss-dsi-hbm-exit-max-command = [
					39 00 00 00 00 00 03 51 0F FE
				];
				qcom,mdss-dsi-lp1-command-state = "dsi_lp_pack_mode";
				qcom,mdss-dsi-nolp-command-state = "dsi_lp_pack_mode";
				qcom,mdss-dsi-nolp-onepulse-command-state = "dsi_lp_pack_mode";
				qcom,mdss-dsi-nolp-hpwm-command-state = "dsi_lp_pack_mode";
				qcom,mdss-dsi-hbm-on-command-state = "dsi_lp_pack_mode";
				qcom,mdss-dsi-hbm-off-command-state = "dsi_lp_pack_mode";
				qcom,mdss-dsi-panel-read-register-open-state = "dsi_lp_mode";
				qcom,mdss-dsi-panel-read-register-close-state = "dsi_lp_mode";
				qcom,mdss-dsi-lhbm-pressed-icon-gamma-command-state = "dsi_lp_mode";
				qcom,mdss-dsi-lhbm-pressed-icon-grayscale-command-state = "dsi_lp_mode";
				qcom,mdss-dsi-lhbm-pressed-icon-on-command-state = "dsi_lp_mode";
				qcom,mdss-dsi-lhbm-pressed-icon-off-command-state = "dsi_lp_mode";
				qcom,mdss-dsi-lhbm-dbv-alpha-command-state = "dsi_hs_mode";

				qcom,mdss-dsi-reset-scanline-command-state = "dsi_hs_mode";
				qcom,mdss-dsi-recovery-scanline-command-state = "dsi_hs_mode";

				qcom,mdss-dsi-osc-track-on-command-state = "dsi_hs_mode";
				qcom,mdss-dsi-osc-track-off-command-state = "dsi_hs_mode";
				qcom,mdss-dsi-hbm-max-command-state = "dsi_hs_mode";
				qcom,mdss-dsi-hbm-exit-max-command-state = "dsi_hs_mode";

				qcom,lm-split = <632 632>;
				qcom,compression-mode = "dsc";
				qcom,mdss-dsc-encoders = <2>;
				qcom,mdss-dsc-slice-height = <20>;
				qcom,mdss-dsc-slice-width = <632>;
				qcom,mdss-dsc-slice-per-pkt = <2>;
				qcom,mdss-dsc-bit-per-component = <10>;
				qcom,mdss-dsc-bit-per-pixel = <8>;
				qcom,mdss-dsc-block-prediction-enable;
			};
			timing@sdc_fhd_90 {
				#include "dsi-panel-AA577-P-3-A0020-common-effect.dtsi"
				#include "dsi-panel-AA577-P-3-A0020-common.dtsi"
				qcom,mdss-mdp-transfer-time-us = <6290>;
				qcom,mdss-dsi-panel-jitter = <0x4 0x1>;
				qcom,mdss-dsc-version = <0x12>;
				qcom,mdss-dsi-timing-default;
				qcom,mdss-dsi-panel-framerate = <90>;
				qcom,mdss-dsi-panel-clockrate = <1012000000>;
				qcom,mdss-dsi-panel-width = <1264>;
				qcom,mdss-dsi-panel-height = <2780>;

				qcom,mdss-dsi-h-front-porch = <26>;
				qcom,mdss-dsi-h-back-porch = <26>;
				qcom,mdss-dsi-h-pulse-width = <2>;
				qcom,mdss-dsi-v-back-porch = <42>;
				qcom,mdss-dsi-v-front-porch = <58>;
				qcom,mdss-dsi-v-pulse-width = <2>;
				qcom,mdss-dsi-h-sync-pulse = <0>;

				oplus,ofp-need-to-sync-data-in-aod-unlocking;
				oplus,ofp-aod-off-insert-black-frame = <1>;
				oplus,ofp-aod-off-black-frame-total-time = <45>;
				oplus,ofp-need-to-separate-backlight;
				oplus,ofp-backlight-on-period = <1>;
				oplus,apollo-panel-async-bl-delay = <8000>;

				qcom,mdss-dsi-timing-switch-command = [
						39 00 00 40 00 00 04 FF 5A A5 00
						15 00 00 40 00 00 02 60 02
						/* recover to narrow TE */
						39 00 00 40 00 00 04 FF 5A A5 02
						39 00 00 40 00 00 09 B0 00 80 00 10 00 00 00 00
						39 00 00 40 00 00 04 FF 5A A5 2D
						39 00 00 40 00 00 03 85 00 00
						15 00 00 40 00 00 02 F2 00
						39 00 00 00 00 00 04 FF 5A A5 00
				];
				qcom,mdss-dsi-on-command = [
						39 00 00 40 00 00 04 FF 5A A5 08
						15 00 00 40 00 00 02 C8 62
						39 00 00 40 00 00 04 FF 5A A5 07
						15 00 00 40 00 00 02 8A 01
						39 00 00 40 00 00 03 8B 21 E0
						39 00 00 40 00 00 64 81 00 00 00 00 00 12 00 00 AB 30 80 0A DC 04 F0 00 14 02 78 02 78 02 00 02 57 00 20 01 F8 00 08 00 0D 05 7A 04 4F 18 00 10 E0 07 10 20 00 06 0F 0F 33 0E 1C 2A 38 46 54 62 69 70 77 79 7B 7D 7E 02 02 22 00 2A 40 2A BE 3A FC 3A FA 3A F8 3B 38 3B 78 3B B6 4B B6 4B F4 4B F4 6C 34 84 74 00 00 00 00 00 00
						// CTB optimize
						39 00 00 40 00 00 04 FF 5A A5 31
						15 00 00 40 00 00 02 D0 81
						15 00 00 40 01 00 02 A0 A3
						39 00 00 40 00 00 13 84 F0 98 62 24 02 FE DC 9E 68 F0 25 21 28 02 FE DF CA 65
						39 00 00 40 01 00 13 85 F0 6F 47 1B 02 FE E5 B9 91 F0 27 22 2A 02 FE DE EB AC
						15 00 00 40 00 00 02 D0 80
						39 00 00 40 00 00 04 FF 5A A5 21
						15 00 00 40 00 00 02 A4 18
						39 00 00 40 00 00 04 FF 5A A5 2D
						15 00 00 40 00 00 02 F2 00
						39 00 00 40 00 00 03 83 00 00
						39 00 00 40 00 00 03 84 00 00
						39 00 00 40 00 00 03 85 00 00
						39 00 00 40 00 00 03 86 00 00
						39 00 00 40 00 00 04 FF 5A A5 00
						15 00 00 40 00 00 02 5A 01
						15 00 00 40 00 00 02 5B 80
						39 00 00 40 00 00 04 FF 5A A5 02
						15 00 00 40 00 00 02 C0 03
						39 00 00 40 00 00 04 FF 5A A5 2D //Page 2D
						15 00 00 40 00 00 02 CE D4
						39 00 00 40 00 00 04 EC 01 AF 00
						39 00 00 40 00 00 03 93 A0 00
						39 00 00 40 00 00 03 94 C4 00
						39 00 00 40 00 00 03 95 00 00
						39 00 00 40 00 00 03 96 00 00
						39 00 00 40 00 00 03 ED D5 00
						39 00 00 40 00 00 04 EE 00 00 00
						15 00 00 40 00 00 02 97 02
						15 00 00 40 00 00 02 B1 03
						39 00 00 40 00 00 03 98 05 00
						39 00 00 40 00 00 03 99 0B 00
						39 00 00 40 00 00 03 9A 17 00
						39 00 00 40 00 00 03 9B 77 00
						39 00 00 40 00 00 05 A0 01 01 00 00
						39 00 00 40 00 00 05 A1 02 00 00 00
						15 00 00 40 00 00 02 B2 02
						15 00 00 40 00 00 02 B3 05
						15 00 00 40 00 00 02 B4 08
						15 00 00 40 00 00 02 B5 11
						39 00 00 40 00 00 03 BA 00 00
						39 00 00 40 00 00 03 BB 01 02
						39 00 00 40 00 00 04 FF 5A A5 02
						39 00 00 40 00 00 09 B0 00 80 00 10 00 00 00 00
						39 00 00 40 00 00 04 FF 5A A5 00
						15 00 00 40 00 00 02 5E 01
						15 00 00 40 00 00 02 60 00
						15 00 00 40 00 00 02 61 07
						15 00 00 40 00 00 02 35 00
						15 00 00 40 00 00 02 53 20
						//ODC 2024/8/3
						39 00 00 40 00 00 04 FF 5A A5 49
						15 00 00 40 00 00 02 D9 02
						15 00 00 40 00 00 02 DA F7
						15 00 00 40 00 00 02 DB 9C
						15 00 00 40 00 00 02 DF 06
						39 00 00 40 00 00 04 FF 5A A5 5A
						39 00 00 40 00 00 04 81 FD 00 00
						39 00 00 40 00 00 04 83 03 15 05
						39 00 00 40 00 00 04 84 02 FD 01
						39 00 00 40 00 00 04 85 02 FD 01
						39 00 00 40 00 00 04 86 12 2B 1A
						39 00 00 40 00 00 04 87 0A FD 05
						39 00 00 40 00 00 04 88 08 FD 04
						39 00 00 40 00 00 04 89 03 FD 06
						39 00 00 40 00 00 04 8A 16 31 27
						39 00 00 40 00 00 04 8D 06 05 15
						39 00 00 40 00 00 04 8E 01 05 05
						39 00 00 40 00 00 04 93 FA 06 06
						39 00 00 40 00 00 04 94 FA 05 00
						39 00 00 40 00 00 04 95 32 50 3C
						39 00 00 40 00 00 04 A4 03 01 02
						39 00 00 40 00 00 04 A5 08 0D 0A
						39 00 00 40 00 00 04 A6 00 00 00
						39 00 00 40 00 00 04 A7 06 0D 0A
						39 00 00 40 00 00 04 A9 01 00 00
						39 00 00 40 00 00 04 B5 07 06 05
						39 00 00 40 00 00 04 B6 02 01 01
						39 00 00 40 00 00 04 B7 F9 F3 08
						39 00 00 40 00 00 04 B8 F7 F4 08
						39 00 00 40 00 00 04 C9 03 08 05
						39 00 00 40 00 00 04 CB 04 09 05
						39 00 00 40 00 00 04 D9 08 08 06
						39 00 00 40 00 00 04 DA 02 02 01
						39 00 00 40 00 00 04 DB F7 F6 01
						39 00 00 40 00 00 04 DC F7 F6 01
						39 00 00 40 00 00 04 FF 5A A5 5B
						39 00 00 40 00 00 04 80 01 0D 07
						39 00 00 40 00 00 04 81 04 08 05
						39 00 00 40 00 00 04 83 06 09 06
						39 00 00 40 00 00 04 93 06 06 06
						39 00 00 40 00 00 04 94 FC FC FC
						39 00 00 40 00 00 04 9A 06 07 05
						39 00 00 40 00 00 04 9B 04 04 03
						39 00 00 40 00 00 04 A5 03 0C 08
						39 00 00 40 00 00 04 A7 04 0D 07
						39 00 00 40 00 00 04 B5 FE FD FC
						39 00 00 40 00 00 04 B6 FB FA FA
						39 00 00 40 00 00 04 B7 F6 F6 F6
						39 00 00 40 00 00 04 C9 03 07 05
						39 00 00 40 00 00 04 CA 00 02 00
						39 00 00 40 00 00 04 CB 04 09 05
						39 00 00 40 00 00 04 DB 01 06 06
						39 00 00 40 00 00 04 DC 01 05 06
						39 00 00 40 00 00 04 E2 05 05 05
						39 00 00 40 00 00 04 E3 03 04 03
						39 00 00 40 00 00 04 FF 5A A5 5C
						39 00 00 40 00 00 04 80 04 04 05
						39 00 00 40 00 00 04 81 02 05 01
						39 00 00 40 00 00 04 83 04 04 06
						39 00 00 40 00 00 04 94 01 01 06
						39 00 00 40 00 00 04 9A 06 0C 0B
						39 00 00 40 00 00 04 9B 06 0C 0C
						39 00 00 40 00 00 04 A5 03 05 04
						39 00 00 40 00 00 04 B7 FA 02 04
						39 00 00 40 00 00 04 B8 FA 02 00
						39 00 00 40 00 00 04 BE 03 06 03
						39 00 00 40 00 00 04 BF 03 06 02
						39 00 00 00 00 00 04 FF 5A A5 00
						//CTB 2024/8/3
						39 00 00 40 00 00 04 FF 5A A5 31
						15 00 00 40 01 00 02 D0 81
						39 00 00 40 00 00 13 80 F0 99 62 25 02 FE DB 9E 67 E0 1A 17 16 00 00 DF C8 C4
						39 00 00 40 00 00 13 81 F0 9C 65 25 02 FE DB 9B 64 E0 09 08 05 00 00 FD F4 EC
						39 00 00 40 00 00 13 82 F0 81 53 1F 02 FE E1 AD 7F E0 07 06 05 00 00 FD FC FB
						39 00 00 40 00 00 13 83 F0 70 48 1B 02 FE E5 B8 90 E0 07 06 05 00 00 FD FC FB
						39 00 00 40 00 00 13 84 F0 94 60 23 02 FE DD A0 6C E0 06 05 04 00 00 FB FA F9
						39 00 00 40 00 00 13 85 F0 7C 50 1E 02 FE E2 B0 84 E0 06 05 04 00 00 FB FA F9
						39 00 00 40 00 00 13 86 F0 99 62 25 02 FE DB 9E 67 E0 1A 17 16 00 00 CD C8 C4
						39 00 00 40 00 00 13 87 F0 9C 65 25 02 FE DB 9B 64 E0 09 08 05 00 00 FD F4 EC
						39 00 00 40 00 00 13 88 F0 81 53 1F 02 FE E1 AD 7F E0 07 06 05 00 00 FD FC FB
						39 00 00 40 00 00 13 89 F0 70 48 1B 02 FE E5 B8 90 E0 07 06 05 00 00 FD FC FB
						39 00 00 40 00 00 13 8A F0 94 60 23 02 FE DD A0 6C E0 06 05 04 00 00 FB FA F9
						39 00 00 40 00 00 13 8B F0 7C 50 1E 02 FE E2 B0 84 E0 06 05 04 00 00 FB FA F9
						15 00 00 40 01 00 02 D0 80
						39 00 00 40 00 00 07 91 04 44 55 01 01 03
						39 00 00 40 00 00 07 92 04 44 55 01 01 03
						39 00 00 40 00 00 07 93 04 44 55 01 01 03
						15 00 00 40 00 00 02 A6 00
						15 00 00 40 00 00 02 A7 10
						15 00 00 40 00 00 02 A8 00
						15 00 00 40 00 00 02 A9 10
						15 00 00 40 00 00 02 AA 00
						15 00 00 40 00 00 02 AB 10
						39 00 00 40 00 00 04 FF 5A A5 00
						//CCTC 2024/8/3
						39 00 00 40 00 00 04 FF 5A A5 2B
						39 00 00 40 00 00 05 AA 30 F7 00 00
						39 00 00 40 00 00 05 AD 30 F9 00 00
						39 00 00 40 00 00 05 B0 30 FA 00 00
						39 00 00 40 00 00 05 C4 0F 04 FB F1
						39 00 00 40 00 00 05 C5 3F DE E4 E4
						39 00 00 40 00 00 05 C7 3F F8 FD F5
						39 00 00 40 00 00 05 C8 3F E2 E9 E9
						39 00 00 40 00 00 05 CA 0F 02 E5 E8
						39 00 00 40 00 00 05 CB 3F ED EF ED
						39 00 00 40 00 00 05 CD 03 02 00 FB
						39 00 00 40 00 00 05 DF 0F 04 F1 F6
						39 00 00 40 00 00 05 E0 3F D2 EB EE
						39 00 00 40 00 00 05 E2 3F F5 F0 F8
						39 00 00 40 00 00 05 E3 3F E2 EE E2
						39 00 00 40 00 00 05 E6 3F FE F3 F4
						39 00 00 40 00 00 05 E9 3F FD F7 F5
						39 00 00 40 00 00 05 EC 3F FD FA F7
						39 00 00 00 00 00 04 FF 5A A5 00
						//Resolving 60Hz stuttering
						39 00 00 40 00 00 04 FF 5A A5 00
						39 00 00 40 00 00 02 5A 01
						39 00 00 40 00 00 02 5B 80
						39 00 00 40 00 00 04 FF 5A A5 02
						39 00 00 40 00 00 02 C0 03
						39 00 00 40 00 00 04 FF 5A A5 2D
						39 00 00 40 00 00 04 EC 01 AF 00
						39 00 00 40 00 00 03 93 A0 00
						39 00 00 40 00 00 03 94 C4 00
						39 00 00 40 00 00 03 95 00 00
						39 00 00 40 00 00 03 96 00 00
						39 00 00 40 00 00 03 ED D5 00
						39 00 00 40 00 00 04 EE 00 00 00
						39 00 00 40 00 00 02 97 02
						39 00 00 40 00 00 02 B1 03
						39 00 00 40 00 00 03 98 05 00
						39 00 00 40 00 00 03 99 0B 00
						39 00 00 40 00 00 03 9A 17 00
						39 00 00 40 00 00 03 9B 77 00
						39 00 00 40 00 00 05 A0 01 01 00 00
						39 00 00 40 00 00 05 A1 02 00 00 00
						39 00 00 40 00 00 02 B2 02
						39 00 00 40 00 00 02 B3 05
						39 00 00 40 00 00 02 B4 08
						39 00 00 40 00 00 02 B5 11
						39 00 00 40 00 00 03 BA 00 00
						39 00 00 40 00 00 03 BB 01 02
						39 00 00 40 00 00 04 FF 5A A5 02
						39 00 00 40 00 00 09 B0 00 80 00 10 00 00 00 00
						//cornor on
						39 00 00 40 00 00 04 FF 5A A5 17
						15 00 00 40 00 00 02 A0 8C
						// switch 90HZ
						39 00 00 40 00 00 04 FF 5A A5 00
						15 00 00 40 00 00 02 60 02
						39 00 00 40 00 00 04 FF 5A A5 2D
						39 00 00 40 00 00 03 85 00 00
						15 00 00 40 00 00 02 F2 00
						39 00 00 40 00 00 04 FF 5A A5 00
						05 00 00 00 78 00 01 11
						39 00 00 40 00 00 04 FF 5A A5 23
						15 00 00 40 00 00 02 CB 01
						39 00 00 40 00 00 04 FF 5A A5 65
						39 00 00 40 00 00 09 98 00 00 41 05 00 00 41 05
						39 00 00 40 00 00 09 99 00 00 41 05 00 00 41 05
						39 00 00 40 00 00 09 9A 00 00 41 05 00 00 41 05
						39 00 00 40 00 00 09 9B 00 00 01 1E 00 00 64 1E
						39 00 00 40 00 00 09 9C 00 00 76 1E 00 00 D8 1E
						39 00 00 40 00 00 09 9D 00 00 EA 1E 00 01 32 1E
						39 00 00 40 00 00 09 9E 00 01 32 1E 00 01 32 1E
						39 00 00 40 00 00 09 9F 00 01 40 1E 00 01 C0 1E
						39 00 00 40 00 00 09 A0 00 01 D0 1E 00 02 CE 1E
						39 00 00 40 00 00 09 A1 00 02 CE 1E 00 03 98 1E
						39 00 00 40 00 00 09 A2 00 03 98 1E 00 04 2E 1E
						39 00 00 40 00 00 09 A3 00 04 2E 1E 00 04 B0 1E
						39 00 00 40 00 00 09 A4 00 04 B0 1E 00 04 B0 1E
						39 00 00 40 00 00 09 A5 00 04 B0 1E 00 04 B0 1E
						39 00 00 40 00 00 09 A6 00 04 B0 1E 00 04 B0 1E
						39 00 00 40 00 00 09 A7 00 04 B0 1E 00 04 B0 1E
						39 00 00 40 00 00 09 A8 00 04 B0 1E 00 04 B0 1E
						39 00 00 40 00 00 09 A9 00 04 B0 1E 00 04 B0 1E
						39 00 00 40 00 00 09 AA 00 04 B0 1E 00 04 B0 1E
						39 00 00 40 00 00 09 AB 00 04 B0 1E 00 04 B0 1E
						39 00 00 40 00 00 09 AC 00 04 B0 1E 00 04 B0 1E
						39 00 00 40 00 00 09 AD 00 04 B0 1E 00 04 B0 1E
						39 00 00 40 00 00 09 AE 00 04 B0 1E 00 04 B0 1E
						39 00 00 40 00 00 09 AF 00 04 B0 1E 00 04 B0 1E
						39 00 00 40 00 00 04 FF 5A A5 75
						39 00 00 40 00 00 09 98 00 00 00 00 00 00 0F 00
						39 00 00 40 00 00 09 99 00 00 00 00 00 00 0F 00
						39 00 00 40 00 00 09 9A 00 00 00 00 00 00 0F 00
						39 00 00 40 00 00 09 9B 00 00 00 00 00 00 10 00
						39 00 00 40 00 00 09 9C 00 00 00 00 00 00 10 00
						39 00 00 40 00 00 09 9D 00 00 00 00 00 00 10 00
						39 00 00 40 00 00 09 9E 00 00 00 00 00 00 10 00
						39 00 00 40 00 00 09 9F 00 00 00 00 00 00 10 00
						39 00 00 40 00 00 09 A0 00 00 00 00 00 00 10 00
						39 00 00 40 00 00 09 A1 00 00 00 00 00 00 10 00
						39 00 00 40 00 00 09 A2 00 00 00 00 00 00 10 00
						39 00 00 40 00 00 09 A3 00 00 00 00 00 00 10 00
						39 00 00 40 00 00 09 A4 00 00 00 00 00 00 10 00
						39 00 00 40 00 00 09 A5 00 00 00 00 00 00 10 00
						39 00 00 40 00 00 09 A6 00 00 00 00 00 00 10 00
						39 00 00 40 00 00 09 A7 00 00 00 00 00 00 10 00
						39 00 00 40 00 00 09 A8 00 00 00 00 00 00 10 00
						39 00 00 40 00 00 09 A9 00 00 00 00 00 00 10 00
						39 00 00 40 00 00 09 AA 00 00 00 00 00 00 10 00
						39 00 00 40 00 00 09 AB 00 00 00 00 00 00 10 00
						39 00 00 40 00 00 09 AC 00 00 00 00 00 00 10 00
						39 00 00 40 00 00 09 AD 00 00 00 00 00 00 10 00
						39 00 00 40 00 00 09 AE 00 00 00 00 00 00 10 00
						39 00 00 40 00 00 09 AF 00 00 00 00 00 00 10 00
						39 00 00 40 00 00 04 FF 5A A5 23
						15 00 00 00 00 00 02 CB 00
						05 00 00 00 14 00 01 29
				];
				qcom,mdss-dsi-post-on-backlight = [

				];
				qcom,mdss-dsi-off-command=[
					05 00 00 00 14 00 01 28
					05 00 00 00 78 00 01 10
				];
				qcom,mdss-dsi-hbm-off-command = [
					39 00 00 00 00 00 03 51 0D BB
				];
				qcom,mdss-dsi-hbm-on-command = [
					39 00 00 40 00 00 04 FF 5A A5 1E
                                        39 00 00 40 00 00 02 80 89
                                        39 00 00 40 00 00 04 FF 5A A5 00
                                        39 00 00 00 00 00 03 51 0F 4A
				];
				qcom,mdss-dsi-panel-read-register-open-command = [
				];
				qcom,mdss-dsi-panel-read-register-close-command = [
				];
				qcom,mdss-dsi-lhbm-pressed-icon-gamma-command = [
				];
				qcom,mdss-dsi-lhbm-pressed-icon-grayscale-command = [
				];
				qcom,mdss-dsi-lhbm-pressed-icon-on-command = [
					39 00 00 40 00 00 04 FF 5A A5 00
					39 00 00 40 00 00 02 96 09
					39 00 00 40 00 00 02 97 D9
					39 00 00 40 00 00 02 98 02
					39 00 00 40 00 00 02 99 78
					39 00 00 00 00 00 02 6E 03
				];
				qcom,mdss-dsi-lhbm-pressed-icon-off-command = [
					39 00 00 40 00 00 04 FF 5A A5 00
					39 00 00 00 00 00 02 6E 00
				];
				qcom,mdss-dsi-lhbm-dbv-alpha-command = [
				];
				qcom,mdss-dsi-lp1-command = [
					39 00 00 40 00 00 04 FF 5A A5 4F
					15 00 00 40 00 00 02 88 78
					39 00 00 40 00 00 04 FF 5A A5 00
					15 00 00 40 00 00 02 60 00
					39 00 00 40 00 00 04 FF 5A A5 53
					39 00 00 40 00 00 03 85 CC E1
					39 00 00 40 00 00 04 FF 5A A5 01
					39 00 00 40 00 00 06 83 00 00 40 04 00
					15 00 00 40 00 00 02 FE 0B
					39 00 00 40 00 00 04 FF 5A A5 0B
					15 00 00 40 00 00 02 88 00
					15 00 00 40 00 00 02 A7 00
					39 00 00 40 00 00 04 FF 5A A5 51
					39 00 00 40 00 00 06 C2 46 46 46 46 00
					15 00 00 40 00 00 02 FE 00
					15 00 00 40 00 00 02 00 00
					39 00 00 40 00 00 04 FF 5A A5 00
					15 00 00 40 00 00 02 39 00
					39 00 00 40 00 00 04 FF 5A A5 4F
					15 00 00 40 00 00 02 8B 78
					/* AOD lv switch */
					39 00 00 40 00 00 04 FF 5A A5 00
					39 00 00 00 00 00 05 51 0D BB 0D BB
				];
				qcom,mdss-dsi-nolp-command = [
					39 00 00 40 00 00 04 FF 5A A5 00
					15 00 00 40 00 00 02 38 00
					39 00 00 00 00 00 05 51 00 00 00 00
				];
				qcom,mdss-dsi-nolp-onepulse-command = [
					39 00 00 40 00 00 04 FF 5A A5 4F
					15 00 00 40 00 00 02 88 78
					39 00 00 40 00 00 04 FF 5A A5 01
					39 00 00 40 00 00 03 80 0C 0C
					39 00 00 40 00 00 04 FF 5A A5 4F
					15 00 00 40 00 00 02 8A 78
					39 00 00 40 00 00 04 FF 5A A5 00
					15 00 00 40 00 00 02 60 01
					39 00 00 40 00 00 04 FF 5A A5 53
					39 00 00 40 00 00 03 85 CC E3
					39 00 00 40 00 00 04 FF 5A A5 01
					39 00 00 40 00 00 06 83 00 00 40 04 00
					15 00 00 40 00 00 02 FE 07
					39 00 00 40 00 00 04 FF 5A A5 0B
					15 00 00 40 00 00 02 88 46
					15 00 00 40 00 00 02 A7 3A
					39 00 00 40 00 00 04 FF 5A A5 51
					39 00 00 40 00 00 06 C2 46 28 28 28 00
					15 00 00 40 00 00 02 FE 00
					15 00 00 40 00 00 02 00 00
					39 00 00 40 00 00 04 FF 5A A5 01
					39 00 00 40 00 00 03 80 0C 00
					39 00 00 40 00 00 04 FF 5A A5 00
					15 00 00 40 00 00 02 38 00
					39 00 00 40 00 00 04 FF 5A A5 4F
					15 00 00 40 00 00 02 8B 78
					39 00 00 40 00 00 04 FF 5A A5 00
					39 00 00 00 00 00 05 51 00 00 00 00
				];
				qcom,mdss-dsi-aod-high-mode-command = [
					39 00 00 40 00 00 04 FF 5A A5 00
					39 00 00 00 00 00 05 51 0D BB 0D BB
				];
				qcom,mdss-dsi-aod-low-mode-command = [
					39 00 00 40 00 00 04 FF 5A A5 00
					39 00 00 00 00 00 05 51 0B 1A 0A 81
				];
				qcom,mdss-dsi-ultra-low-power-aod-on-command = [
					39 00 00 40 00 00 04 FF 5A A5 2D
					39 00 00 40 00 00 03 8A 1D 00
					39 00 00 00 00 00 04 FF 5A A5 00
				];
				qcom,mdss-dsi-ultra-low-power-aod-off-command = [
					39 00 00 40 00 00 04 FF 5A A5 2D
					39 00 00 40 00 00 03 8A 00 00
					39 00 00 00 00 00 04 FF 5A A5 00
				];
				qcom,mdss-dsi-temperature-compensation-command = [

				];
				qcom,mdss-dsi-read-compensation-reg1-command = [

				];
				qcom,mdss-dsi-pwm-switch-high-command = [
					39 00 00 40 00 00 04 FF 5A A5 4F
					15 00 00 40 00 00 02 80 01
					15 00 00 40 00 00 02 81 04
					15 00 00 40 00 00 02 88 78
					39 00 00 40 00 00 04 FF 5A A5 00
					39 00 00 40 00 00 03 51 04 8B
					39 00 00 40 00 00 04 FF 5A A5 24
					39 00 00 40 00 00 06 C9 00 00 00 10 00
					39 00 00 40 00 00 04 FE 30 00 50
					39 00 00 40 00 00 06 CA 00 80 00 B0 00
					39 00 00 40 00 00 04 FE D0 01 10
					39 00 00 40 00 00 06 CB 01 50 01 78 01
					39 00 00 40 00 00 04 FE D0 02 98
					39 00 00 40 00 00 06 CC 03 20 04 40 05
					39 00 00 40 00 00 04 FE 20 05 E8
					39 00 00 40 00 00 06 CD 06 E8 07 C8 09
					39 00 00 40 00 00 04 FE 30 0A A8
					39 00 00 40 00 00 06 CE 0B 70 0C D8 0E
					39 00 00 40 00 00 04 FE F0 0F F0
					39 00 00 40 00 00 04 FF 5A A5 4F
					15 00 00 40 00 00 02 8A 78
					39 00 00 40 00 00 04 FF 5A A5 24
					39 00 00 40 00 00 06 C9 00 00 00 10 00
					39 00 00 40 00 00 04 FE 30 00 50
					39 00 00 40 00 00 06 CA 00 80 00 B0 00
					39 00 00 40 00 00 04 FE D0 01 10
					39 00 00 40 00 00 06 CB 01 50 01 B0 02
					39 00 00 40 00 00 04 FE 10 02 B0
					39 00 00 40 00 00 06 CC 03 70 04 70 05
					39 00 00 40 00 00 04 FE 70 06 30
					39 00 00 40 00 00 06 CD 07 10 08 10 09
					39 00 00 40 00 00 04 FE 80 0A F0
					39 00 00 40 00 00 06 CE 0B A0 0D 10 0E
					39 00 00 40 00 00 04 FE F0 0F F0
					39 00 00 40 00 00 04 FF 5A A5 4F
					15 00 00 00 00 00 02 8B 78
				];
				qcom,mdss-dsi-pwm-switch-low-command = [
					39 00 00 40 00 00 04 FF 5A A5 4F
					15 00 00 40 00 00 02 80 01
					15 00 00 40 00 00 02 81 04
					15 00 00 40 00 00 02 88 78
					39 00 00 40 00 00 04 FF 5A A5 00
					39 00 00 40 00 00 03 51 04 8A
					39 00 00 40 00 00 04 FF 5A A5 24
					39 00 00 40 00 00 06 C9 00 00 00 10 00
					39 00 00 40 00 00 04 FE 30 00 50
					39 00 00 40 00 00 06 CA 00 80 00 B0 00
					39 00 00 40 00 00 04 FE D0 01 20
					39 00 00 40 00 00 06 CB 01 68 01 A0 02
					39 00 00 40 00 00 04 FE 28 02 D8
					39 00 00 40 00 00 06 CC 03 68 04 E0 05
					39 00 00 40 00 00 04 FE B0 06 78
					39 00 00 40 00 00 06 CD 07 38 08 50 09
					39 00 00 40 00 00 04 FE E0 0B 44
					39 00 00 40 00 00 06 CE 0B D8 0D 10 0E
					39 00 00 40 00 00 04 FE F0 0F F0
					39 00 00 40 00 00 04 FF 5A A5 4F
					15 00 00 40 00 00 02 8A 78
					39 00 00 40 00 00 04 FF 5A A5 24
					39 00 00 40 00 00 06 C9 00 00 00 10 00
					39 00 00 40 00 00 04 FE 30 00 50
					39 00 00 40 00 00 06 CA 00 80 00 B0 00
					39 00 00 40 00 00 04 FE D0 01 10
					39 00 00 40 00 00 06 CB 01 50 01 B0 02
					39 00 00 40 00 00 04 FE 10 02 B0
					39 00 00 40 00 00 06 CC 03 70 04 70 05
					39 00 00 40 00 00 04 FE 70 06 30
					39 00 00 40 00 00 06 CD 07 10 08 10 09
					39 00 00 40 00 00 04 FE 80 0A F0
					39 00 00 40 00 00 06 CE 0B A0 0D 10 0E
					39 00 00 40 00 00 04 FE F0 0F F0
					39 00 00 40 00 00 04 FF 5A A5 4F
					15 00 00 00 00 00 02 8B 78
				];
				qcom,mdss-dsi-pwm-switch-onepulse-command = [
				];
				qcom,mdss-dsi-pwm-switch-onepulse-low-command = [
				];
				qcom,mdss-dsi-pwm-switch-1to3-command = [
					39 00 00 40 00 00 04 FF 5A A5 4F
					15 00 00 40 00 00 02 88 78
					39 00 00 40 00 00 04 FF 5A A5 01
					39 00 00 40 00 00 06 83 00 00 40 04 00
					15 00 00 40 00 00 02 FE 0B
					39 00 00 40 00 00 04 FF 5A A5 0B
					15 00 00 40 00 00 02 88 00
					15 00 00 40 00 00 02 A7 00
					39 00 00 40 00 00 04 FF 5A A5 51
					39 00 00 40 00 00 06 C2 46 46 46 46 00
					15 00 00 40 00 00 02 FE 00
					15 00 00 40 00 00 02 00 00
					39 00 00 40 00 00 06 A0 98 98 A4 A8 22
					15 00 00 40 00 00 02 FE 22
					15 00 00 40 00 00 02 00 00
					39 00 00 40 00 00 06 A1 CC D0 D0 A2 22
					15 00 00 40 00 00 02 FE 22
					15 00 00 40 00 00 02 00 00
					39 00 00 40 00 00 06 A2 A4 A6 99 9A 22
					15 00 00 40 00 00 02 FE 22
					15 00 00 40 00 00 02 00 00
					// Page 52
					39 00 00 40 00 00 04 FF 5A A5 52
					39 00 00 40 00 00 06 80 DA BC 58 B1 11
					15 00 00 40 00 00 02 FE 01
					15 00 00 40 00 00 02 00 00
					39 00 00 40 00 00 06 81 4D 4D 4D 4E 00
					15 00 00 40 00 00 02 FE 00
					15 00 00 40 00 00 02 00 00
					39 00 00 40 00 00 06 82 4D 4E 4D 4D 00
					15 00 00 40 00 00 02 FE 00
					15 00 00 40 00 00 02 00 00
					39 00 00 40 00 00 04 FF 5A A5 00
					15 00 00 40 00 00 02 60 02
					39 00 00 40 00 00 04 FF 5A A5 4F
					// CMD Q
					15 00 00 40 00 00 02 8B 78
					39 00 00 40 00 00 04 FF 5A A5 53
					15 00 00 40 00 00 02 F0 01
					39 00 00 40 00 00 04 FF 5A A5 63
					39 00 00 40 00 00 11 F1 00 00 00 00 00 00 00 00 00 00 00 00 00 00 00 00
					39 00 00 40 00 00 11 F2 10 10 10 10 10 00 00 00 00 00 00 00 00 00 00 00
					39 00 00 40 00 00 11 F3 00 00 00 00 00 20 20 20 20 20 00 00 00 00 00 00
					39 00 00 40 00 00 11 F4 00 00 00 00 00 FF FF FF FF FF 00 00 00 00 00 00
					39 00 00 40 00 00 04 FF 5A A5 53
					15 00 00 40 00 00 02 F0 00
					39 00 00 00 00 00 04 FF 5A A5 00
				];
				qcom,mdss-dsi-pwm-switch-3to1-command = [
					39 00 00 40 00 00 04 FF 5A A5 4F
					15 00 00 40 00 00 02 88 78
					39 00 00 40 00 00 04 FF 5A A5 01
					39 00 00 40 00 00 03 80 0C 0C
					39 00 00 40 00 00 04 FF 5A A5 4F
					15 00 00 40 00 00 02 8A 78
					39 00 00 40 00 00 04 FF 5A A5 01
					39 00 00 40 00 00 06 83 00 00 40 04 00
					15 00 00 40 00 00 02 FE 07
					39 00 00 40 00 00 04 FF 5A A5 0B
					15 00 00 40 00 00 02 88 46
					15 00 00 40 00 00 02 A7 3A
					39 00 00 40 00 00 04 FF 5A A5 51
					39 00 00 40 00 00 06 C2 46 28 28 28 00
					15 00 00 40 00 00 02 FE 00
					15 00 00 40 00 00 02 00 00
					39 00 00 40 00 00 06 A0 98 98 6C 69 22
					15 00 00 40 00 00 02 FE 22
					15 00 00 40 00 00 02 00 00
					39 00 00 40 00 00 06 A1 8C 91 91 74 22
					15 00 00 40 00 00 02 FE 22
					15 00 00 40 00 00 02 00 00
					39 00 00 40 00 00 06 A2 68 72 72 72 22
					15 00 00 40 00 00 02 FE 22
					15 00 00 40 00 00 02 00 00
					// Page 52
					39 00 00 40 00 00 04 FF 5A A5 52
					// VRR
					39 00 00 40 00 00 06 80 DA BC 49 A5 11
					15 00 00 40 00 00 02 FE 01
					15 00 00 40 00 00 02 00 00
					39 00 00 40 00 00 06 81 3D 3E 3E 3F 00
					15 00 00 40 00 00 02 FE 00
					15 00 00 40 00 00 02 00 00
					39 00 00 40 00 00 06 82 41 23 23 23 00
					15 00 00 40 00 00 02 FE 00
					15 00 00 40 00 00 02 00 00
					39 00 00 40 00 00 04 FF 5A A5 00
					// 90Hz 1 pulse
					15 00 00 40 00 00 02 60 03
					39 00 00 40 00 00 04 FF 5A A5 01
					39 00 00 40 00 00 03 80 0C 00
					39 00 00 40 00 00 04 FF 5A A5 4F
					15 00 00 40 00 00 02 8B 78
					39 00 00 40 00 00 04 FF 5A A5 53
					15 00 00 40 00 00 02 F0 01
					39 00 00 40 00 00 04 FF 5A A5 63
					39 00 00 40 00 00 11 F1 20 20 20 20 20 20 20 20 20 20 00 00 00 00 00 00
					39 00 00 40 00 00 11 F2 00 00 00 00 00 00 00 00 00 00 00 00 00 00 00 00
					39 00 00 40 00 00 11 F3 00 00 00 00 00 00 00 00 00 00 00 00 00 00 00 00
					39 00 00 40 00 00 11 F4 FF FF FF FF FF FF FF FF FF FF 00 00 00 00 00 00
					39 00 00 40 00 00 04 FF 5A A5 53
					15 00 00 40 00 00 02 F0 00
					39 00 00 00 00 00 04 FF 5A A5 00
				];
				qcom,mdss-dsi-timming-pwm-switch-onepulse-command = [
					39 00 00 40 00 00 04 FF 5A A5 00
					15 00 00 40 00 00 02 60 03
					39 00 00 40 00 00 04 FF 5A A5 2D
					39 00 00 40 00 00 03 86 00 00
					15 00 00 40 00 00 02 CE D4
					15 00 00 40 00 00 02 F2 00
					39 00 00 00 00 00 04 FF 5A A5 00
				];
				qcom,mdss-dsi-power-on-pwm-switch-onepulse-command = [
					39 00 00 40 00 00 04 FF 5A A5 4F
					15 00 00 40 00 00 02 88 78
					39 00 00 40 00 00 04 FF 5A A5 01
					39 00 00 40 00 00 03 80 0C 0C
					39 00 00 40 00 00 04 FF 5A A5 4F
					15 00 00 40 00 00 02 8A 78
					39 00 00 40 00 00 04 FF 5A A5 01
					39 00 00 40 00 00 06 83 00 00 40 04 00
					15 00 00 40 00 00 02 FE 07
					39 00 00 40 00 00 04 FF 5A A5 0B
					15 00 00 40 00 00 02 88 46
					15 00 00 40 00 00 02 A7 3A
					39 00 00 40 00 00 04 FF 5A A5 51
					39 00 00 40 00 00 06 C2 46 28 28 28 00
					15 00 00 40 00 00 02 FE 00
					15 00 00 40 00 00 02 00 00
					39 00 00 40 00 00 06 A0 98 98 6C 69 22
					15 00 00 40 00 00 02 FE 22
					15 00 00 40 00 00 02 00 00
					39 00 00 40 00 00 06 A1 8C 91 91 74 22
					15 00 00 40 00 00 02 FE 22
					15 00 00 40 00 00 02 00 00
					39 00 00 40 00 00 06 A2 68 72 72 72 22
					15 00 00 40 00 00 02 FE 22
					15 00 00 40 00 00 02 00 00
					// Page 52
					39 00 00 40 00 00 04 FF 5A A5 52
					// VRR
					39 00 00 40 00 00 06 80 DA BC 49 A5 11
					15 00 00 40 00 00 02 FE 01
					15 00 00 40 00 00 02 00 00
					39 00 00 40 00 00 06 81 3D 3E 3E 3F 00
					15 00 00 40 00 00 02 FE 00
					15 00 00 40 00 00 02 00 00
					39 00 00 40 00 00 06 82 41 23 23 23 00
					15 00 00 40 00 00 02 FE 00
					15 00 00 40 00 00 02 00 00
					39 00 00 40 00 00 04 FF 5A A5 00
					// 90Hz 1 pulse
					15 00 00 40 00 00 02 60 03
					39 00 00 40 00 00 04 FF 5A A5 01
					39 00 00 40 00 00 03 80 0C 00
					39 00 00 40 00 00 04 FF 5A A5 4F
					15 00 00 40 00 00 02 8B 78
					39 00 00 40 00 00 04 FF 5A A5 53
					15 00 00 40 00 00 02 F0 01
					39 00 00 40 00 00 04 FF 5A A5 63
					39 00 00 40 00 00 11 F1 20 20 20 20 20 20 20 20 20 20 00 00 00 00 00 00
					39 00 00 40 00 00 11 F2 00 00 00 00 00 00 00 00 00 00 00 00 00 00 00 00
					39 00 00 40 00 00 11 F3 00 00 00 00 00 00 00 00 00 00 00 00 00 00 00 00
					39 00 00 40 00 00 11 F4 FF FF FF FF FF FF FF FF FF FF 00 00 00 00 00 00
					39 00 00 40 00 00 04 FF 5A A5 53
					15 00 00 40 00 00 02 F0 00
					39 00 00 00 18 00 04 FF 5A A5 00
				];
				qcom,mdss-dsi-osc-track-on-command = [
				];
				qcom,mdss-dsi-osc-track-off-command = [
				];
				qcom,mdss-dsi-hbm-max-command = [
					39 00 00 00 00 00 03 51 10 ED
				];

				qcom,mdss-dsi-hbm-exit-max-command = [
					39 00 00 00 00 00 03 51 0F FE
				];
				qcom,mdss-dsi-lp1-command-state = "dsi_lp_pack_mode";
				qcom,mdss-dsi-nolp-command-state = "dsi_lp_pack_mode";
				qcom,mdss-dsi-nolp-onepulse-command-state = "dsi_lp_pack_mode";
				qcom,mdss-dsi-nolp-hpwm-command-state = "dsi_lp_pack_mode";
				qcom,mdss-dsi-hbm-on-command-state = "dsi_lp_pack_mode";
				qcom,mdss-dsi-hbm-off-command-state = "dsi_lp_pack_mode";
				qcom,mdss-dsi-panel-read-register-open-state = "dsi_lp_mode";
				qcom,mdss-dsi-panel-read-register-close-state = "dsi_lp_mode";
				qcom,mdss-dsi-lhbm-pressed-icon-gamma-command-state = "dsi_lp_mode";
				qcom,mdss-dsi-lhbm-pressed-icon-grayscale-command-state = "dsi_lp_mode";
				qcom,mdss-dsi-lhbm-pressed-icon-on-command-state = "dsi_lp_mode";
				qcom,mdss-dsi-lhbm-pressed-icon-off-command-state = "dsi_lp_mode";
				qcom,mdss-dsi-lhbm-dbv-alpha-command-state = "dsi_hs_mode";
				qcom,mdss-dsi-reset-scanline-command-state = "dsi_hs_mode";
				qcom,mdss-dsi-recovery-scanline-command-state = "dsi_hs_mode";
				qcom,mdss-dsi-osc-track-on-command-state = "dsi_hs_mode";
				qcom,mdss-dsi-osc-track-off-command-state = "dsi_hs_mode";
				qcom,mdss-dsi-hbm-max-command-state = "dsi_hs_mode";
				qcom,mdss-dsi-hbm-exit-max-command-state = "dsi_hs_mode";

				qcom,lm-split = <632 632>;
				qcom,compression-mode = "dsc";
				qcom,mdss-dsc-encoders = <2>;
				qcom,mdss-dsc-slice-height = <20>;
				qcom,mdss-dsc-slice-width = <632>;
				qcom,mdss-dsc-slice-per-pkt = <2>;
				qcom,mdss-dsc-bit-per-component = <10>;
				qcom,mdss-dsc-bit-per-pixel = <8>;
				qcom,mdss-dsc-block-prediction-enable;
			};
			timing@sdc_fhd_60 {
				#include "dsi-panel-AA577-P-3-A0020-common-effect.dtsi"
				#include "dsi-panel-AA577-P-3-A0020-common.dtsi"
				qcom,mdss-mdp-transfer-time-us = <6290>;
				qcom,mdss-dsi-panel-jitter = <0x4 0x1>;
				qcom,mdss-dsc-version = <0x12>;
				qcom,mdss-dsi-timing-default;
				qcom,mdss-dsi-panel-framerate = <60>;
				qcom,mdss-dsi-panel-clockrate = <1012000000>;
				qcom,mdss-dsi-panel-width = <1264>;
				qcom,mdss-dsi-panel-height = <2780>;

				qcom,mdss-dsi-h-front-porch = <26>;
				qcom,mdss-dsi-h-back-porch = <26>;
				qcom,mdss-dsi-h-pulse-width = <2>;
				qcom,mdss-dsi-v-back-porch = <42>;
				qcom,mdss-dsi-v-front-porch = <58>;
				qcom,mdss-dsi-v-pulse-width = <2>;
				qcom,mdss-dsi-h-sync-pulse = <0>;

				oplus,ofp-need-to-sync-data-in-aod-unlocking;
				oplus,ofp-aod-off-insert-black-frame = <2>;
				oplus,ofp-aod-off-black-frame-total-time = <59>;
				oplus,ofp-need-to-separate-backlight;
				oplus,ofp-backlight-on-period = <1>;
				oplus,apollo-panel-async-bl-delay = <9000>;

				qcom,mdss-dsi-timing-switch-command = [
					39 00 00 40 00 00 04 FF 5A A5 00
					15 00 00 40 00 00 02 60 00
					/* recover to narrow TE */
					39 00 00 40 00 00 04 FF 5A A5 02
					39 00 00 40 00 00 09 B0 00 80 00 10 00 00 00 00
					39 00 00 40 00 00 04 FF 5A A5 2D
					39 00 00 40 00 00 03 83 01 00
					15 00 00 40 00 00 02 F2 01
					39 00 00 00 00 00 04 FF 5A A5 00
				];
				qcom,mdss-dsi-on-command = [
					39 00 00 40 00 00 04 FF 5A A5 08
					15 00 00 40 00 00 02 C8 62
					39 00 00 40 00 00 04 FF 5A A5 07
					15 00 00 40 00 00 02 8A 01
					39 00 00 40 00 00 03 8B 21 E0
					39 00 00 40 00 00 64 81 00 00 00 00 00 12 00 00 AB 30 80 0A DC 04 F0 00 14 02 78 02 78 02 00 02 57 00 20 01 F8 00 08 00 0D 05 7A 04 4F 18 00 10 E0 07 10 20 00 06 0F 0F 33 0E 1C 2A 38 46 54 62 69 70 77 79 7B 7D 7E 02 02 22 00 2A 40 2A BE 3A FC 3A FA 3A F8 3B 38 3B 78 3B B6 4B B6 4B F4 4B F4 6C 34 84 74 00 00 00 00 00 00
					// CTB optimize
					39 00 00 40 00 00 04 FF 5A A5 31
					15 00 00 40 00 00 02 D0 81
					15 00 00 40 01 00 02 A0 A3
					39 00 00 40 00 00 13 84 F0 98 62 24 02 FE DC 9E 68 F0 25 21 28 02 FE DF CA 65
					39 00 00 40 01 00 13 85 F0 6F 47 1B 02 FE E5 B9 91 F0 27 22 2A 02 FE DE EB AC
					15 00 00 40 00 00 02 D0 80
					39 00 00 40 00 00 04 FF 5A A5 21
					15 00 00 40 00 00 02 A4 18
					39 00 00 40 00 00 04 FF 5A A5 2D
					15 00 00 40 00 00 02 F2 00
					39 00 00 40 00 00 03 83 00 00
					39 00 00 40 00 00 03 84 00 00
					39 00 00 40 00 00 03 85 00 00
					39 00 00 40 00 00 03 86 00 00
					39 00 00 40 00 00 04 FF 5A A5 00
					15 00 00 40 00 00 02 5A 01
					15 00 00 40 00 00 02 5B 80
					39 00 00 40 00 00 04 FF 5A A5 02
					15 00 00 40 00 00 02 C0 03
					39 00 00 40 00 00 04 FF 5A A5 2D //Page 2D
					15 00 00 40 00 00 02 CE D4
					39 00 00 40 00 00 04 EC 01 AF 00
					39 00 00 40 00 00 03 93 A0 00
					39 00 00 40 00 00 03 94 C4 00
					39 00 00 40 00 00 03 95 00 00
					39 00 00 40 00 00 03 96 00 00
					39 00 00 40 00 00 03 ED D5 00
					39 00 00 40 00 00 04 EE 00 00 00
					15 00 00 40 00 00 02 97 02
					15 00 00 40 00 00 02 B1 03
					39 00 00 40 00 00 03 98 05 00
					39 00 00 40 00 00 03 99 0B 00
					39 00 00 40 00 00 03 9A 17 00
					39 00 00 40 00 00 03 9B 77 00
					39 00 00 40 00 00 05 A0 01 01 00 00
					39 00 00 40 00 00 05 A1 02 00 00 00
					15 00 00 40 00 00 02 B2 02
					15 00 00 40 00 00 02 B3 05
					15 00 00 40 00 00 02 B4 08
					15 00 00 40 00 00 02 B5 11
					39 00 00 40 00 00 03 BA 00 00
					39 00 00 40 00 00 03 BB 01 02
					39 00 00 40 00 00 04 FF 5A A5 02
					39 00 00 40 00 00 09 B0 00 80 00 10 00 00 00 00
					39 00 00 40 00 00 04 FF 5A A5 00
					15 00 00 40 00 00 02 5E 01
					15 00 00 40 00 00 02 60 00
					15 00 00 40 00 00 02 61 07
					15 00 00 40 00 00 02 35 00
					15 00 00 40 00 00 02 53 20
					//ODC 2024/8/3
					39 00 00 40 00 00 04 FF 5A A5 49
					15 00 00 40 00 00 02 D9 02
					15 00 00 40 00 00 02 DA F7
					15 00 00 40 00 00 02 DB 9C
					15 00 00 40 00 00 02 DF 06
					39 00 00 40 00 00 04 FF 5A A5 5A
					39 00 00 40 00 00 04 81 FD 00 00
					39 00 00 40 00 00 04 83 03 15 05
					39 00 00 40 00 00 04 84 02 FD 01
					39 00 00 40 00 00 04 85 02 FD 01
					39 00 00 40 00 00 04 86 12 2B 1A
					39 00 00 40 00 00 04 87 0A FD 05
					39 00 00 40 00 00 04 88 08 FD 04
					39 00 00 40 00 00 04 89 03 FD 06
					39 00 00 40 00 00 04 8A 16 31 27
					39 00 00 40 00 00 04 8D 06 05 15
					39 00 00 40 00 00 04 8E 01 05 05
					39 00 00 40 00 00 04 93 FA 06 06
					39 00 00 40 00 00 04 94 FA 05 00
					39 00 00 40 00 00 04 95 32 50 3C
					39 00 00 40 00 00 04 A4 03 01 02
					39 00 00 40 00 00 04 A5 08 0D 0A
					39 00 00 40 00 00 04 A6 00 00 00
					39 00 00 40 00 00 04 A7 06 0D 0A
					39 00 00 40 00 00 04 A9 01 00 00
					39 00 00 40 00 00 04 B5 07 06 05
					39 00 00 40 00 00 04 B6 02 01 01
					39 00 00 40 00 00 04 B7 F9 F3 08
					39 00 00 40 00 00 04 B8 F7 F4 08
					39 00 00 40 00 00 04 C9 03 08 05
					39 00 00 40 00 00 04 CB 04 09 05
					39 00 00 40 00 00 04 D9 08 08 06
					39 00 00 40 00 00 04 DA 02 02 01
					39 00 00 40 00 00 04 DB F7 F6 01
					39 00 00 40 00 00 04 DC F7 F6 01
					39 00 00 40 00 00 04 FF 5A A5 5B
					39 00 00 40 00 00 04 80 01 0D 07
					39 00 00 40 00 00 04 81 04 08 05
					39 00 00 40 00 00 04 83 06 09 06
					39 00 00 40 00 00 04 93 06 06 06
					39 00 00 40 00 00 04 94 FC FC FC
					39 00 00 40 00 00 04 9A 06 07 05
					39 00 00 40 00 00 04 9B 04 04 03
					39 00 00 40 00 00 04 A5 03 0C 08
					39 00 00 40 00 00 04 A7 04 0D 07
					39 00 00 40 00 00 04 B5 FE FD FC
					39 00 00 40 00 00 04 B6 FB FA FA
					39 00 00 40 00 00 04 B7 F6 F6 F6
					39 00 00 40 00 00 04 C9 03 07 05
					39 00 00 40 00 00 04 CA 00 02 00
					39 00 00 40 00 00 04 CB 04 09 05
					39 00 00 40 00 00 04 DB 01 06 06
					39 00 00 40 00 00 04 DC 01 05 06
					39 00 00 40 00 00 04 E2 05 05 05
					39 00 00 40 00 00 04 E3 03 04 03
					39 00 00 40 00 00 04 FF 5A A5 5C
					39 00 00 40 00 00 04 80 04 04 05
					39 00 00 40 00 00 04 81 02 05 01
					39 00 00 40 00 00 04 83 04 04 06
					39 00 00 40 00 00 04 94 01 01 06
					39 00 00 40 00 00 04 9A 06 0C 0B
					39 00 00 40 00 00 04 9B 06 0C 0C
					39 00 00 40 00 00 04 A5 03 05 04
					39 00 00 40 00 00 04 B7 FA 02 04
					39 00 00 40 00 00 04 B8 FA 02 00
					39 00 00 40 00 00 04 BE 03 06 03
					39 00 00 40 00 00 04 BF 03 06 02
					39 00 00 00 00 00 04 FF 5A A5 00
					//CTB 2024/8/3
					39 00 00 40 00 00 04 FF 5A A5 31
					15 00 00 40 01 00 02 D0 81
					39 00 00 40 00 00 13 80 F0 99 62 25 02 FE DB 9E 67 E0 1A 17 16 00 00 DF C8 C4
					39 00 00 40 00 00 13 81 F0 9C 65 25 02 FE DB 9B 64 E0 09 08 05 00 00 FD F4 EC
					39 00 00 40 00 00 13 82 F0 81 53 1F 02 FE E1 AD 7F E0 07 06 05 00 00 FD FC FB
					39 00 00 40 00 00 13 83 F0 70 48 1B 02 FE E5 B8 90 E0 07 06 05 00 00 FD FC FB
					39 00 00 40 00 00 13 84 F0 94 60 23 02 FE DD A0 6C E0 06 05 04 00 00 FB FA F9
					39 00 00 40 00 00 13 85 F0 7C 50 1E 02 FE E2 B0 84 E0 06 05 04 00 00 FB FA F9
					39 00 00 40 00 00 13 86 F0 99 62 25 02 FE DB 9E 67 E0 1A 17 16 00 00 CD C8 C4
					39 00 00 40 00 00 13 87 F0 9C 65 25 02 FE DB 9B 64 E0 09 08 05 00 00 FD F4 EC
					39 00 00 40 00 00 13 88 F0 81 53 1F 02 FE E1 AD 7F E0 07 06 05 00 00 FD FC FB
					39 00 00 40 00 00 13 89 F0 70 48 1B 02 FE E5 B8 90 E0 07 06 05 00 00 FD FC FB
					39 00 00 40 00 00 13 8A F0 94 60 23 02 FE DD A0 6C E0 06 05 04 00 00 FB FA F9
					39 00 00 40 00 00 13 8B F0 7C 50 1E 02 FE E2 B0 84 E0 06 05 04 00 00 FB FA F9
					15 00 00 40 01 00 02 D0 80
					39 00 00 40 00 00 07 91 04 44 55 01 01 03
					39 00 00 40 00 00 07 92 04 44 55 01 01 03
					39 00 00 40 00 00 07 93 04 44 55 01 01 03
					15 00 00 40 00 00 02 A6 00
					15 00 00 40 00 00 02 A7 10
					15 00 00 40 00 00 02 A8 00
					15 00 00 40 00 00 02 A9 10
					15 00 00 40 00 00 02 AA 00
					15 00 00 40 00 00 02 AB 10
					39 00 00 40 00 00 04 FF 5A A5 00
					//CCTC 2024/8/3
					39 00 00 40 00 00 04 FF 5A A5 2B
					39 00 00 40 00 00 05 AA 30 F7 00 00
					39 00 00 40 00 00 05 AD 30 F9 00 00
					39 00 00 40 00 00 05 B0 30 FA 00 00
					39 00 00 40 00 00 05 C4 0F 04 FB F1
					39 00 00 40 00 00 05 C5 3F DE E4 E4
					39 00 00 40 00 00 05 C7 3F F8 FD F5
					39 00 00 40 00 00 05 C8 3F E2 E9 E9
					39 00 00 40 00 00 05 CA 0F 02 E5 E8
					39 00 00 40 00 00 05 CB 3F ED EF ED
					39 00 00 40 00 00 05 CD 03 02 00 FB
					39 00 00 40 00 00 05 DF 0F 04 F1 F6
					39 00 00 40 00 00 05 E0 3F D2 EB EE
					39 00 00 40 00 00 05 E2 3F F5 F0 F8
					39 00 00 40 00 00 05 E3 3F E2 EE E2
					39 00 00 40 00 00 05 E6 3F FE F3 F4
					39 00 00 40 00 00 05 E9 3F FD F7 F5
					39 00 00 40 00 00 05 EC 3F FD FA F7
					39 00 00 00 00 00 04 FF 5A A5 00
					// Resolving 60Hz stuttering
					39 00 00 40 00 00 04 FF 5A A5 00
					39 00 00 40 00 00 02 5A 01
					39 00 00 40 00 00 02 5B 80
					39 00 00 40 00 00 04 FF 5A A5 02
					39 00 00 40 00 00 02 C0 03
					39 00 00 40 00 00 04 FF 5A A5 2D
					39 00 00 40 00 00 04 EC 01 AF 00
					39 00 00 40 00 00 03 93 A0 00
					39 00 00 40 00 00 03 94 C4 00
					39 00 00 40 00 00 03 95 00 00
					39 00 00 40 00 00 03 96 00 00
					39 00 00 40 00 00 03 ED D5 00
					39 00 00 40 00 00 04 EE 00 00 00
					39 00 00 40 00 00 02 97 02
					39 00 00 40 00 00 02 B1 03
					39 00 00 40 00 00 03 98 05 00
					39 00 00 40 00 00 03 99 0B 00
					39 00 00 40 00 00 03 9A 17 00
					39 00 00 40 00 00 03 9B 77 00
					39 00 00 40 00 00 05 A0 01 01 00 00
					39 00 00 40 00 00 05 A1 02 00 00 00
					39 00 00 40 00 00 02 B2 02
					39 00 00 40 00 00 02 B3 05
					39 00 00 40 00 00 02 B4 08
					39 00 00 40 00 00 02 B5 11
					39 00 00 40 00 00 03 BA 00 00
					39 00 00 40 00 00 03 BB 01 02
					39 00 00 40 00 00 04 FF 5A A5 02
					39 00 00 40 00 00 09 B0 00 80 00 10 00 00 00 00
					//cornor on
					39 00 00 40 00 00 04 FF 5A A5 17
					15 00 00 40 00 00 02 A0 8C
					// switch 60HZ
					39 00 00 40 00 00 04 FF 5A A5 00
					15 00 00 40 00 00 02 60 00
					39 00 00 40 00 00 04 FF 5A A5 2D
					39 00 00 40 00 00 03 83 01 00
					15 00 00 40 00 00 02 F2 01
					39 00 00 40 00 00 04 FF 5A A5 00
					05 00 00 00 78 00 01 11
					39 00 00 40 00 00 04 FF 5A A5 23
					15 00 00 40 00 00 02 CB 01
					39 00 00 40 00 00 04 FF 5A A5 65
					39 00 00 40 00 00 09 98 00 00 41 05 00 00 41 05
					39 00 00 40 00 00 09 99 00 00 41 05 00 00 41 05
					39 00 00 40 00 00 09 9A 00 00 41 05 00 00 41 05
					39 00 00 40 00 00 09 9B 00 00 01 1E 00 00 64 1E
					39 00 00 40 00 00 09 9C 00 00 76 1E 00 00 D8 1E
					39 00 00 40 00 00 09 9D 00 00 EA 1E 00 01 32 1E
					39 00 00 40 00 00 09 9E 00 01 32 1E 00 01 32 1E
					39 00 00 40 00 00 09 9F 00 01 40 1E 00 01 C0 1E
					39 00 00 40 00 00 09 A0 00 01 D0 1E 00 02 CE 1E
					39 00 00 40 00 00 09 A1 00 02 CE 1E 00 03 98 1E
					39 00 00 40 00 00 09 A2 00 03 98 1E 00 04 2E 1E
					39 00 00 40 00 00 09 A3 00 04 2E 1E 00 04 B0 1E
					39 00 00 40 00 00 09 A4 00 04 B0 1E 00 04 B0 1E
					39 00 00 40 00 00 09 A5 00 04 B0 1E 00 04 B0 1E
					39 00 00 40 00 00 09 A6 00 04 B0 1E 00 04 B0 1E
					39 00 00 40 00 00 09 A7 00 04 B0 1E 00 04 B0 1E
					39 00 00 40 00 00 09 A8 00 04 B0 1E 00 04 B0 1E
					39 00 00 40 00 00 09 A9 00 04 B0 1E 00 04 B0 1E
					39 00 00 40 00 00 09 AA 00 04 B0 1E 00 04 B0 1E
					39 00 00 40 00 00 09 AB 00 04 B0 1E 00 04 B0 1E
					39 00 00 40 00 00 09 AC 00 04 B0 1E 00 04 B0 1E
					39 00 00 40 00 00 09 AD 00 04 B0 1E 00 04 B0 1E
					39 00 00 40 00 00 09 AE 00 04 B0 1E 00 04 B0 1E
					39 00 00 40 00 00 09 AF 00 04 B0 1E 00 04 B0 1E
					39 00 00 40 00 00 04 FF 5A A5 75
					39 00 00 40 00 00 09 98 00 00 00 00 00 00 0F 00
					39 00 00 40 00 00 09 99 00 00 00 00 00 00 0F 00
					39 00 00 40 00 00 09 9A 00 00 00 00 00 00 0F 00
					39 00 00 40 00 00 09 9B 00 00 00 00 00 00 10 00
					39 00 00 40 00 00 09 9C 00 00 00 00 00 00 10 00
					39 00 00 40 00 00 09 9D 00 00 00 00 00 00 10 00
					39 00 00 40 00 00 09 9E 00 00 00 00 00 00 10 00
					39 00 00 40 00 00 09 9F 00 00 00 00 00 00 10 00
					39 00 00 40 00 00 09 A0 00 00 00 00 00 00 10 00
					39 00 00 40 00 00 09 A1 00 00 00 00 00 00 10 00
					39 00 00 40 00 00 09 A2 00 00 00 00 00 00 10 00
					39 00 00 40 00 00 09 A3 00 00 00 00 00 00 10 00
					39 00 00 40 00 00 09 A4 00 00 00 00 00 00 10 00
					39 00 00 40 00 00 09 A5 00 00 00 00 00 00 10 00
					39 00 00 40 00 00 09 A6 00 00 00 00 00 00 10 00
					39 00 00 40 00 00 09 A7 00 00 00 00 00 00 10 00
					39 00 00 40 00 00 09 A8 00 00 00 00 00 00 10 00
					39 00 00 40 00 00 09 A9 00 00 00 00 00 00 10 00
					39 00 00 40 00 00 09 AA 00 00 00 00 00 00 10 00
					39 00 00 40 00 00 09 AB 00 00 00 00 00 00 10 00
					39 00 00 40 00 00 09 AC 00 00 00 00 00 00 10 00
					39 00 00 40 00 00 09 AD 00 00 00 00 00 00 10 00
					39 00 00 40 00 00 09 AE 00 00 00 00 00 00 10 00
					39 00 00 40 00 00 09 AF 00 00 00 00 00 00 10 00
					39 00 00 40 00 00 04 FF 5A A5 23
					15 00 00 00 00 00 02 CB 00
					05 00 00 00 14 00 01 29
				];
				qcom,mdss-dsi-post-on-backlight = [

				];
				qcom,mdss-dsi-off-command=[
					05 00 00 00 14 00 01 28
					05 00 00 00 78 00 01 10
				];
				qcom,mdss-dsi-hbm-off-command = [
					39 00 00 00 00 00 03 51 0D BB
				];
				qcom,mdss-dsi-hbm-on-command = [
					39 00 00 40 00 00 04 FF 5A A5 1E
                                        39 00 00 40 00 00 02 80 89
                                        39 00 00 40 00 00 04 FF 5A A5 00
                                        39 00 00 00 00 00 03 51 0F 4A
				];
				qcom,mdss-dsi-panel-read-register-open-command = [
				];
				qcom,mdss-dsi-panel-read-register-close-command = [
				];
				qcom,mdss-dsi-lhbm-pressed-icon-gamma-command = [
				];
				qcom,mdss-dsi-lhbm-pressed-icon-grayscale-command = [
				];
				qcom,mdss-dsi-lhbm-pressed-icon-on-command = [
					39 00 00 40 00 00 04 FF 5A A5 00
					39 00 00 40 00 00 02 96 09
					39 00 00 40 00 00 02 97 D9
					39 00 00 40 00 00 02 98 02
					39 00 00 40 00 00 02 99 78
					39 00 00 00 00 00 02 6E 03
				];
				qcom,mdss-dsi-lhbm-pressed-icon-off-command = [
					39 00 00 40 00 00 04 FF 5A A5 00
					39 00 00 00 00 00 02 6E 00
				];
				qcom,mdss-dsi-lhbm-dbv-alpha-command = [
				];
				qcom,mdss-dsi-lp1-command = [
					39 00 00 40 00 00 04 FF 5A A5 4F
					15 00 00 40 00 00 02 88 78
					39 00 00 40 00 00 04 FF 5A A5 00
					15 00 00 40 00 00 02 60 00
					39 00 00 40 00 00 04 FF 5A A5 53
					39 00 00 40 00 00 03 85 CC E1
					39 00 00 40 00 00 04 FF 5A A5 01
					39 00 00 40 00 00 06 83 00 00 40 04 00
					15 00 00 40 00 00 02 FE 0B
					39 00 00 40 00 00 04 FF 5A A5 0B
					15 00 00 40 00 00 02 88 00
					15 00 00 40 00 00 02 A7 00
					39 00 00 40 00 00 04 FF 5A A5 51
					39 00 00 40 00 00 06 C2 46 46 46 46 00
					15 00 00 40 00 00 02 FE 00
					15 00 00 40 00 00 02 00 00
					39 00 00 40 00 00 04 FF 5A A5 00
					15 00 00 40 00 00 02 39 00
					39 00 00 40 00 00 04 FF 5A A5 4F
					15 00 00 40 00 00 02 8B 78
					/* AOD lv switch */
					39 00 00 40 00 00 04 FF 5A A5 00
					39 00 00 00 00 00 05 51 0D BB 0D BB
				];
				qcom,mdss-dsi-nolp-command = [
					39 00 00 40 00 00 04 FF 5A A5 00
					15 00 00 40 00 00 02 38 00
					39 00 00 00 00 00 05 51 00 00 00 00
				];
				qcom,mdss-dsi-nolp-onepulse-command = [
					39 00 00 40 00 00 04 FF 5A A5 4F
					15 00 00 40 00 00 02 88 78
					39 00 00 40 00 00 04 FF 5A A5 01
					39 00 00 40 00 00 03 80 0C 0C
					39 00 00 40 00 00 04 FF 5A A5 4F
					15 00 00 40 00 00 02 8A 78
					39 00 00 40 00 00 04 FF 5A A5 00
					15 00 00 40 00 00 02 60 01
					39 00 00 40 00 00 04 FF 5A A5 53
					39 00 00 40 00 00 03 85 CC E3
					39 00 00 40 00 00 04 FF 5A A5 01
					39 00 00 40 00 00 06 83 00 00 40 04 00
					15 00 00 40 00 00 02 FE 07
					39 00 00 40 00 00 04 FF 5A A5 0B
					15 00 00 40 00 00 02 88 46
					15 00 00 40 00 00 02 A7 3A
					39 00 00 40 00 00 04 FF 5A A5 51
					39 00 00 40 00 00 06 C2 46 28 28 28 00
					15 00 00 40 00 00 02 FE 00
					15 00 00 40 00 00 02 00 00
					39 00 00 40 00 00 04 FF 5A A5 01
					39 00 00 40 00 00 03 80 0C 00
					39 00 00 40 00 00 04 FF 5A A5 00
					15 00 00 40 00 00 02 38 00
					39 00 00 40 00 00 04 FF 5A A5 4F
					15 00 00 40 00 00 02 8B 78
					39 00 00 40 00 00 04 FF 5A A5 00
					39 00 00 00 00 00 05 51 00 00 00 00
				];
				qcom,mdss-dsi-aod-high-mode-command = [
					39 00 00 40 00 00 04 FF 5A A5 00
					39 00 00 00 00 00 05 51 0D BB 0D BB
				];
				qcom,mdss-dsi-aod-low-mode-command = [
					39 00 00 40 00 00 04 FF 5A A5 00
					39 00 00 00 00 00 05 51 0B 1A 0A 81
				];
				qcom,mdss-dsi-ultra-low-power-aod-on-command = [
					39 00 00 40 00 00 04 FF 5A A5 2D
					39 00 00 40 00 00 03 8A 1D 00
					39 00 00 00 00 00 04 FF 5A A5 00
				];
				qcom,mdss-dsi-ultra-low-power-aod-off-command = [
					39 00 00 40 00 00 04 FF 5A A5 2D
					39 00 00 40 00 00 03 8A 00 00
					39 00 00 00 00 00 04 FF 5A A5 00
				];
				qcom,mdss-dsi-temperature-compensation-command = [
				];
				qcom,mdss-dsi-read-compensation-reg1-command = [
				];
				qcom,mdss-dsi-pwm-switch-high-command = [
					39 00 00 40 00 00 04 FF 5A A5 4F
					15 00 00 40 00 00 02 80 01
					15 00 00 40 00 00 02 81 06
					15 00 00 40 00 00 02 88 78
					39 00 00 40 00 00 04 FF 5A A5 00
					39 00 00 40 00 00 03 51 04 8B
					39 00 00 40 00 00 04 FF 5A A5 24
					39 00 00 40 00 00 06 C9 00 00 00 10 00
					39 00 00 40 00 00 04 FE 30 00 50
					39 00 00 40 00 00 06 CA 00 80 00 B0 00
					39 00 00 40 00 00 04 FE D0 00 F0
					39 00 00 40 00 00 06 CB 01 38 01 78 01
					39 00 00 40 00 00 04 FE C0 02 90
					39 00 00 40 00 00 06 CC 03 20 04 30 05
					39 00 00 40 00 00 04 FE 30 05 E8
					39 00 00 40 00 00 06 CD 06 E0 07 B8 09
					39 00 00 40 00 00 04 FE 30 0A A8
					39 00 00 40 00 00 06 CE 0B 60 0C D0 0E
					39 00 00 40 00 00 04 FE F0 0F F0
					39 00 00 40 00 00 04 FF 5A A5 4F
					15 00 00 40 00 00 02 8A 78
					39 00 00 40 00 00 04 FF 5A A5 24
					39 00 00 40 00 00 06 C9 00 00 00 10 00
					39 00 00 40 00 00 04 FE 30 00 50
					39 00 00 40 00 00 06 CA 00 80 00 B0 00
					39 00 00 40 00 00 04 FE D0 01 10
					39 00 00 40 00 00 06 CB 01 50 01 B0 02
					39 00 00 40 00 00 04 FE 10 02 B0
					39 00 00 40 00 00 06 CC 03 70 04 70 05
					39 00 00 40 00 00 04 FE 70 06 30
					39 00 00 40 00 00 06 CD 07 10 08 10 09
					39 00 00 40 00 00 04 FE 80 0A F0
					39 00 00 40 00 00 06 CE 0B A0 0D 10 0E
					39 00 00 40 00 00 04 FE F0 0F F0
					39 00 00 40 00 00 04 FF 5A A5 4F
					15 00 00 00 00 00 02 8B 78
				];
				qcom,mdss-dsi-pwm-switch-low-command = [
					39 00 00 40 00 00 04 FF 5A A5 4F
					15 00 00 40 00 00 02 80 01
					15 00 00 40 00 00 02 81 06
					15 00 00 40 00 00 02 88 78
					39 00 00 40 00 00 04 FF 5A A5 00
					39 00 00 40 00 00 03 51 04 8A
					39 00 00 40 00 00 04 FF 5A A5 24
					39 00 00 40 00 00 06 C9 00 00 00 10 00
					39 00 00 40 00 00 04 FE 30 00 50
					39 00 00 40 00 00 06 CA 00 80 00 B0 00
					39 00 00 40 00 00 04 FE D0 01 20
					39 00 00 40 00 00 06 CB 01 78 01 C0 02
					39 00 00 40 00 00 04 FE 38 02 E8
					39 00 00 40 00 00 06 CC 03 78 04 D8 05
					39 00 00 40 00 00 04 FE B8 06 78
					39 00 00 40 00 00 06 CD 07 50 08 60 09
					39 00 00 40 00 00 04 FE E0 0B 44
					39 00 00 40 00 00 06 CE 0B D8 0D 10 0E
					39 00 00 40 00 00 04 FE F0 0F F0
					39 00 00 40 00 00 04 FF 5A A5 4F
					15 00 00 40 00 00 02 8A 78
					39 00 00 40 00 00 04 FF 5A A5 24
					39 00 00 40 00 00 06 C9 00 00 00 10 00
					39 00 00 40 00 00 04 FE 30 00 50
					39 00 00 40 00 00 06 CA 00 80 00 B0 00
					39 00 00 40 00 00 04 FE D0 01 10
					39 00 00 40 00 00 06 CB 01 50 01 B0 02
					39 00 00 40 00 00 04 FE 10 02 B0
					39 00 00 40 00 00 06 CC 03 70 04 70 05
					39 00 00 40 00 00 04 FE 70 06 30
					39 00 00 40 00 00 06 CD 07 10 08 10 09
					39 00 00 40 00 00 04 FE 80 0A F0
					39 00 00 40 00 00 06 CE 0B A0 0D 10 0E
					39 00 00 40 00 00 04 FE F0 0F F0
					39 00 00 40 00 00 04 FF 5A A5 4F
					15 00 00 00 00 00 02 8B 78
				];
				qcom,mdss-dsi-pwm-switch-onepulse-command = [
				];
				qcom,mdss-dsi-pwm-switch-onepulse-low-command = [
				];
				qcom,mdss-dsi-pwm-switch-1to3-command = [
					39 00 00 40 00 00 04 FF 5A A5 4F
					15 00 00 40 00 00 02 88 78
					39 00 00 40 00 00 04 FF 5A A5 01
					39 00 00 40 00 00 06 83 00 00 40 04 00
					15 00 00 40 00 00 02 FE 0B
					39 00 00 40 00 00 04 FF 5A A5 0B
					15 00 00 40 00 00 02 88 00
					15 00 00 40 00 00 02 A7 00
					39 00 00 40 00 00 04 FF 5A A5 51
					39 00 00 40 00 00 06 C2 46 46 46 46 00
					15 00 00 40 00 00 02 FE 00
					15 00 00 40 00 00 02 00 00
					39 00 00 40 00 00 06 A0 98 98 A4 A8 22
					15 00 00 40 00 00 02 FE 22
					15 00 00 40 00 00 02 00 00
					39 00 00 40 00 00 06 A1 CC D0 D0 A2 22
					15 00 00 40 00 00 02 FE 22
					15 00 00 40 00 00 02 00 00
					39 00 00 40 00 00 06 A2 A4 A6 99 9A 22
					15 00 00 40 00 00 02 FE 22
					15 00 00 40 00 00 02 00 00
					// Page 52
					39 00 00 40 00 00 04 FF 5A A5 52
					39 00 00 40 00 00 06 80 DA BC 58 B1 11
					15 00 00 40 00 00 02 FE 01
					15 00 00 40 00 00 02 00 00
					39 00 00 40 00 00 06 81 4D 4D 4D 4E 00
					15 00 00 40 00 00 02 FE 00
					15 00 00 40 00 00 02 00 00
					39 00 00 40 00 00 06 82 4D 4E 4D 4D 00
					15 00 00 40 00 00 02 FE 00
					15 00 00 40 00 00 02 00 00
					39 00 00 40 00 00 04 FF 5A A5 00
					//120hz 3pulse
					15 00 00 40 00 00 02 60 00
					39 00 00 40 00 00 04 FF 5A A5 4F
					// CMD Q
					15 00 00 40 00 00 02 8B 78
					39 00 00 40 00 00 04 FF 5A A5 53
					15 00 00 40 00 00 02 F0 01
					39 00 00 40 00 00 04 FF 5A A5 63
					39 00 00 40 00 00 11 F1 00 00 00 00 00 00 00 00 00 00 00 00 00 00 00 00
					39 00 00 40 00 00 11 F2 10 10 10 10 10 00 00 00 00 00 00 00 00 00 00 00
					39 00 00 40 00 00 11 F3 00 00 00 00 00 20 20 20 20 20 00 00 00 00 00 00
					39 00 00 40 00 00 11 F4 00 00 00 00 00 FF FF FF FF FF 00 00 00 00 00 00
					39 00 00 40 00 00 04 FF 5A A5 53
					15 00 00 40 00 00 02 F0 00
					39 00 00 00 00 00 04 FF 5A A5 00
				];
				qcom,mdss-dsi-pwm-switch-3to1-command = [
					39 00 00 40 00 00 04 FF 5A A5 4F
					15 00 00 40 00 00 02 88 78
					39 00 00 40 00 00 04 FF 5A A5 01
					39 00 00 40 00 00 03 80 0C 0C
					39 00 00 40 00 00 04 FF 5A A5 4F
					15 00 00 40 00 00 02 8A 78
					39 00 00 40 00 00 04 FF 5A A5 01
					39 00 00 40 00 00 06 83 00 00 40 04 00
					15 00 00 40 00 00 02 FE 07
					39 00 00 40 00 00 04 FF 5A A5 0B
					15 00 00 40 00 00 02 88 46
					15 00 00 40 00 00 02 A7 3A
					39 00 00 40 00 00 04 FF 5A A5 51
					39 00 00 40 00 00 06 C2 46 28 28 28 00
					15 00 00 40 00 00 02 FE 00
					15 00 00 40 00 00 02 00 00
					39 00 00 40 00 00 06 A0 98 98 6C 69 22
					15 00 00 40 00 00 02 FE 22
					15 00 00 40 00 00 02 00 00
					39 00 00 40 00 00 06 A1 8C 91 91 74 22
					15 00 00 40 00 00 02 FE 22
					15 00 00 40 00 00 02 00 00
					39 00 00 40 00 00 06 A2 68 72 72 72 22
					15 00 00 40 00 00 02 FE 22
					15 00 00 40 00 00 02 00 00
					// Page 52
					39 00 00 40 00 00 04 FF 5A A5 52
					// VRR
					39 00 00 40 00 00 06 80 DA BC 49 A5 11
					15 00 00 40 00 00 02 FE 01
					15 00 00 40 00 00 02 00 00
					39 00 00 40 00 00 06 81 3D 3E 3E 3F 00
					15 00 00 40 00 00 02 FE 00
					15 00 00 40 00 00 02 00 00
					39 00 00 40 00 00 06 82 41 23 23 23 00
					15 00 00 40 00 00 02 FE 00
					15 00 00 40 00 00 02 00 00
					39 00 00 40 00 00 04 FF 5A A5 00
					// 120Hz 1 pulse
					15 00 00 40 00 00 02 60 01
					39 00 00 40 00 00 04 FF 5A A5 01
					39 00 00 40 00 00 03 80 0C 00
					39 00 00 40 00 00 04 FF 5A A5 4F
					15 00 00 40 00 00 02 8B 78
					39 00 00 40 00 00 04 FF 5A A5 53
					15 00 00 40 00 00 02 F0 01
					39 00 00 40 00 00 04 FF 5A A5 63
					39 00 00 40 00 00 11 F1 20 20 20 20 20 20 20 20 20 20 00 00 00 00 00 00
					39 00 00 40 00 00 11 F2 00 00 00 00 00 00 00 00 00 00 00 00 00 00 00 00
					39 00 00 40 00 00 11 F3 00 00 00 00 00 00 00 00 00 00 00 00 00 00 00 00
					39 00 00 40 00 00 11 F4 FF FF FF FF FF FF FF FF FF FF 00 00 00 00 00 00
					39 00 00 40 00 00 04 FF 5A A5 53
					15 00 00 40 00 00 02 F0 00
					39 00 00 00 00 00 04 FF 5A A5 00
				];
				qcom,mdss-dsi-timming-pwm-switch-onepulse-command = [
					39 00 00 40 00 00 04 FF 5A A5 00
					15 00 00 40 00 00 02 60 01
					39 00 00 40 00 00 04 FF 5A A5 2D
					39 00 00 40 00 00 03 84 01 00
					15 00 00 40 00 00 02 CE D4
					15 00 00 40 00 00 02 F2 01
					39 00 00 00 00 00 04 FF 5A A5 00
				];
				qcom,mdss-dsi-power-on-pwm-switch-onepulse-command = [
					39 00 00 40 00 00 04 FF 5A A5 4F
					15 00 00 40 00 00 02 88 78
					39 00 00 40 00 00 04 FF 5A A5 01
					39 00 00 40 00 00 03 80 0C 0C
					39 00 00 40 00 00 04 FF 5A A5 4F
					15 00 00 40 00 00 02 8A 78
					39 00 00 40 00 00 04 FF 5A A5 01
					39 00 00 40 00 00 06 83 00 00 40 04 00
					15 00 00 40 00 00 02 FE 07
					39 00 00 40 00 00 04 FF 5A A5 0B
					15 00 00 40 00 00 02 88 46
					15 00 00 40 00 00 02 A7 3A
					39 00 00 40 00 00 04 FF 5A A5 51
					39 00 00 40 00 00 06 C2 46 28 28 28 00
					15 00 00 40 00 00 02 FE 00
					15 00 00 40 00 00 02 00 00
					39 00 00 40 00 00 06 A0 98 98 6C 69 22
					15 00 00 40 00 00 02 FE 22
					15 00 00 40 00 00 02 00 00
					39 00 00 40 00 00 06 A1 8C 91 91 74 22
					15 00 00 40 00 00 02 FE 22
					15 00 00 40 00 00 02 00 00
					39 00 00 40 00 00 06 A2 68 72 72 72 22
					15 00 00 40 00 00 02 FE 22
					15 00 00 40 00 00 02 00 00
					// Page 52
					39 00 00 40 00 00 04 FF 5A A5 52
					// VRR
					39 00 00 40 00 00 06 80 DA BC 49 A5 11
					15 00 00 40 00 00 02 FE 01
					15 00 00 40 00 00 02 00 00
					39 00 00 40 00 00 06 81 3D 3E 3E 3F 00
					15 00 00 40 00 00 02 FE 00
					15 00 00 40 00 00 02 00 00
					39 00 00 40 00 00 06 82 41 23 23 23 00
					15 00 00 40 00 00 02 FE 00
					15 00 00 40 00 00 02 00 00
					39 00 00 40 00 00 04 FF 5A A5 00
					// 90Hz 1 pulse
					15 00 00 40 00 00 02 60 01
					39 00 00 40 00 00 04 FF 5A A5 01
					39 00 00 40 00 00 03 80 0C 00
					39 00 00 40 00 00 04 FF 5A A5 4F
					15 00 00 40 00 00 02 8B 78
					39 00 00 40 00 00 04 FF 5A A5 53
					15 00 00 40 00 00 02 F0 01
					39 00 00 40 00 00 04 FF 5A A5 63
					39 00 00 40 00 00 11 F1 20 20 20 20 20 20 20 20 20 20 00 00 00 00 00 00
					39 00 00 40 00 00 11 F2 00 00 00 00 00 00 00 00 00 00 00 00 00 00 00 00
					39 00 00 40 00 00 11 F3 00 00 00 00 00 00 00 00 00 00 00 00 00 00 00 00
					39 00 00 40 00 00 11 F4 FF FF FF FF FF FF FF FF FF FF 00 00 00 00 00 00
					39 00 00 40 00 00 04 FF 5A A5 53
					15 00 00 40 00 00 02 F0 00
					39 00 00 00 20 00 04 FF 5A A5 00
				];
				qcom,mdss-dsi-osc-track-on-command = [
				];
				qcom,mdss-dsi-osc-track-off-command = [
				];
				qcom,mdss-dsi-hbm-max-command = [
					39 00 00 00 00 00 03 51 10 ED
				];

				qcom,mdss-dsi-hbm-exit-max-command = [
					39 00 00 00 00 00 03 51 0F FE
				];
				qcom,mdss-dsi-lp1-command-state = "dsi_lp_pack_mode";
				qcom,mdss-dsi-nolp-command-state = "dsi_lp_pack_mode";
				qcom,mdss-dsi-nolp-onepulse-command-state = "dsi_lp_pack_mode";
				qcom,mdss-dsi-nolp-hpwm-command-state = "dsi_lp_pack_mode";
				qcom,mdss-dsi-hbm-on-command-state = "dsi_lp_pack_mode";
				qcom,mdss-dsi-hbm-off-command-state = "dsi_lp_pack_mode";
				qcom,mdss-dsi-panel-read-register-open-state = "dsi_lp_mode";
				qcom,mdss-dsi-panel-read-register-close-state = "dsi_lp_mode";
				qcom,mdss-dsi-lhbm-pressed-icon-gamma-command-state = "dsi_lp_mode";
				qcom,mdss-dsi-lhbm-pressed-icon-grayscale-command-state = "dsi_lp_mode";
				qcom,mdss-dsi-lhbm-pressed-icon-on-command-state = "dsi_lp_mode";
				qcom,mdss-dsi-lhbm-pressed-icon-off-command-state = "dsi_lp_mode";
				qcom,mdss-dsi-lhbm-dbv-alpha-command-state = "dsi_hs_mode";
				qcom,mdss-dsi-reset-scanline-command-state = "dsi_hs_mode";
				qcom,mdss-dsi-recovery-scanline-command-state = "dsi_hs_mode";

				qcom,mdss-dsi-osc-track-on-command-state = "dsi_hs_mode";
				qcom,mdss-dsi-osc-track-off-command-state = "dsi_hs_mode";
				qcom,mdss-dsi-hbm-max-command-state = "dsi_hs_mode";
				qcom,mdss-dsi-hbm-exit-max-command-state = "dsi_hs_mode";

				qcom,lm-split = <632 632>;
				qcom,compression-mode = "dsc";
				qcom,mdss-dsc-encoders = <2>;
				qcom,mdss-dsc-slice-height = <20>;
				qcom,mdss-dsc-slice-width = <632>;
				qcom,mdss-dsc-slice-per-pkt = <2>;
				qcom,mdss-dsc-bit-per-component = <10>;
				qcom,mdss-dsc-bit-per-pixel = <8>;
				qcom,mdss-dsc-block-prediction-enable;
			};
			timing@oplus_fhd_120 {
				#include "dsi-panel-AA577-P-3-A0020-common-effect.dtsi"
				#include "dsi-panel-AA577-P-3-A0020-common.dtsi"
				qcom,mdss-mdp-transfer-time-us = <6290>;
				qcom,mdss-dsi-panel-jitter = <0x4 0x1>;
				qcom,mdss-dsc-version = <0x12>;
				qcom,mdss-dsi-timing-default;
				qcom,mdss-dsi-panel-framerate = <120>;
				qcom,mdss-dsi-panel-clockrate = <1012000000>;
				qcom,mdss-dsi-panel-width = <1264>;
				qcom,mdss-dsi-panel-height = <2780>;

				qcom,mdss-dsi-h-front-porch = <26>;
				qcom,mdss-dsi-h-back-porch = <26>;
				qcom,mdss-dsi-h-pulse-width = <2>;
				qcom,mdss-dsi-v-back-porch = <42>;
				qcom,mdss-dsi-v-front-porch = <58>;
				qcom,mdss-dsi-v-pulse-width = <2>;
				qcom,mdss-dsi-h-sync-pulse = <0>;

				oplus,ofp-need-to-sync-data-in-aod-unlocking;
				oplus,ofp-aod-off-insert-black-frame = <1>;
				oplus,ofp-aod-off-black-frame-total-time = <42>;
				oplus,ofp-need-to-separate-backlight;
				oplus,ofp-backlight-on-period = <1>;

				qcom,mdss-dsi-timing-switch-command = [
					39 00 00 40 00 00 04 FF 5A A5 00
					15 00 00 40 00 00 02 60 00
					/* recover to narrow TE */
					39 00 00 40 00 00 04 FF 5A A5 02
					39 00 00 40 00 00 09 B0 00 80 00 10 00 00 00 00
					39 00 00 40 00 00 04 FF 5A A5 2D
					39 00 00 40 00 00 03 83 00 00
					15 00 00 40 00 00 02 F2 00
					39 00 00 00 00 00 04 FF 5A A5 00
				];
				qcom,mdss-dsi-on-command = [
					39 00 00 40 00 00 04 FF 5A A5 08
					15 00 00 40 00 00 02 C8 62
					39 00 00 40 00 00 04 FF 5A A5 07
					15 00 00 40 00 00 02 8A 01
					39 00 00 40 00 00 03 8B 21 E0
					39 00 00 40 00 00 64 81 00 00 00 00 00 12 00 00 AB 30 80 0A DC 04 F0 00 14 02 78 02 78 02 00 02 57 00 20 01 F8 00 08 00 0D 05 7A 04 4F 18 00 10 E0 07 10 20 00 06 0F 0F 33 0E 1C 2A 38 46 54 62 69 70 77 79 7B 7D 7E 02 02 22 00 2A 40 2A BE 3A FC 3A FA 3A F8 3B 38 3B 78 3B B6 4B B6 4B F4 4B F4 6C 34 84 74 00 00 00 00 00 00
					// CTB optimize
					39 00 00 40 00 00 04 FF 5A A5 31
					15 00 00 40 00 00 02 D0 81
					15 00 00 40 01 00 02 A0 A3
					39 00 00 40 00 00 13 84 F0 98 62 24 02 FE DC 9E 68 F0 25 21 28 02 FE DF CA 65
					39 00 00 40 01 00 13 85 F0 6F 47 1B 02 FE E5 B9 91 F0 27 22 2A 02 FE DE EB AC
					15 00 00 40 00 00 02 D0 80
					39 00 00 40 00 00 04 FF 5A A5 21
					15 00 00 40 00 00 02 A4 18
					39 00 00 40 00 00 04 FF 5A A5 2D
					15 00 00 40 00 00 02 F2 00
					39 00 00 40 00 00 03 83 00 00
					39 00 00 40 00 00 03 84 00 00
					39 00 00 40 00 00 03 85 00 00
					39 00 00 40 00 00 03 86 00 00
					39 00 00 40 00 00 04 FF 5A A5 00
					15 00 00 40 00 00 02 5A 01
					15 00 00 40 00 00 02 5B 80
					39 00 00 40 00 00 04 FF 5A A5 02
					15 00 00 40 00 00 02 C0 03
					39 00 00 40 00 00 04 FF 5A A5 2D //Page 2D
					15 00 00 40 00 00 02 CE D4
					39 00 00 40 00 00 04 EC 01 AF 00
					39 00 00 40 00 00 03 93 A0 00
					39 00 00 40 00 00 03 94 C4 00
					39 00 00 40 00 00 03 95 00 00
					39 00 00 40 00 00 03 96 00 00
					39 00 00 40 00 00 03 ED D5 00
					39 00 00 40 00 00 04 EE 00 00 00
					15 00 00 40 00 00 02 97 02
					15 00 00 40 00 00 02 B1 03
					39 00 00 40 00 00 03 98 05 00
					39 00 00 40 00 00 03 99 0B 00
					39 00 00 40 00 00 03 9A 17 00
					39 00 00 40 00 00 03 9B 77 00
					39 00 00 40 00 00 05 A0 01 01 00 00
					39 00 00 40 00 00 05 A1 02 00 00 00
					15 00 00 40 00 00 02 B2 02
					15 00 00 40 00 00 02 B3 05
					15 00 00 40 00 00 02 B4 08
					15 00 00 40 00 00 02 B5 11
					39 00 00 40 00 00 03 BA 00 00
					39 00 00 40 00 00 03 BB 01 02
					39 00 00 40 00 00 04 FF 5A A5 02
					39 00 00 40 00 00 09 B0 00 80 00 10 00 00 00 00
					39 00 00 40 00 00 04 FF 5A A5 00
					15 00 00 40 00 00 02 5E 01
					15 00 00 40 00 00 02 60 00
					15 00 00 40 00 00 02 61 07
					15 00 00 40 00 00 02 35 00
					15 00 00 40 00 00 02 53 20
					//ODC 2024/8/3
					39 00 00 40 00 00 04 FF 5A A5 49
					15 00 00 40 00 00 02 D9 02
					15 00 00 40 00 00 02 DA F7
					15 00 00 40 00 00 02 DB 9C
					15 00 00 40 00 00 02 DF 06
					39 00 00 40 00 00 04 FF 5A A5 5A
					39 00 00 40 00 00 04 81 FD 00 00
					39 00 00 40 00 00 04 83 03 15 05
					39 00 00 40 00 00 04 84 02 FD 01
					39 00 00 40 00 00 04 85 02 FD 01
					39 00 00 40 00 00 04 86 12 2B 1A
					39 00 00 40 00 00 04 87 0A FD 05
					39 00 00 40 00 00 04 88 08 FD 04
					39 00 00 40 00 00 04 89 03 FD 06
					39 00 00 40 00 00 04 8A 16 31 27
					39 00 00 40 00 00 04 8D 06 05 15
					39 00 00 40 00 00 04 8E 01 05 05
					39 00 00 40 00 00 04 93 FA 06 06
					39 00 00 40 00 00 04 94 FA 05 00
					39 00 00 40 00 00 04 95 32 50 3C
					39 00 00 40 00 00 04 A4 03 01 02
					39 00 00 40 00 00 04 A5 08 0D 0A
					39 00 00 40 00 00 04 A6 00 00 00
					39 00 00 40 00 00 04 A7 06 0D 0A
					39 00 00 40 00 00 04 A9 01 00 00
					39 00 00 40 00 00 04 B5 07 06 05
					39 00 00 40 00 00 04 B6 02 01 01
					39 00 00 40 00 00 04 B7 F9 F3 08
					39 00 00 40 00 00 04 B8 F7 F4 08
					39 00 00 40 00 00 04 C9 03 08 05
					39 00 00 40 00 00 04 CB 04 09 05
					39 00 00 40 00 00 04 D9 08 08 06
					39 00 00 40 00 00 04 DA 02 02 01
					39 00 00 40 00 00 04 DB F7 F6 01
					39 00 00 40 00 00 04 DC F7 F6 01
					39 00 00 40 00 00 04 FF 5A A5 5B
					39 00 00 40 00 00 04 80 01 0D 07
					39 00 00 40 00 00 04 81 04 08 05
					39 00 00 40 00 00 04 83 06 09 06
					39 00 00 40 00 00 04 93 06 06 06
					39 00 00 40 00 00 04 94 FC FC FC
					39 00 00 40 00 00 04 9A 06 07 05
					39 00 00 40 00 00 04 9B 04 04 03
					39 00 00 40 00 00 04 A5 03 0C 08
					39 00 00 40 00 00 04 A7 04 0D 07
					39 00 00 40 00 00 04 B5 FE FD FC
					39 00 00 40 00 00 04 B6 FB FA FA
					39 00 00 40 00 00 04 B7 F6 F6 F6
					39 00 00 40 00 00 04 C9 03 07 05
					39 00 00 40 00 00 04 CA 00 02 00
					39 00 00 40 00 00 04 CB 04 09 05
					39 00 00 40 00 00 04 DB 01 06 06
					39 00 00 40 00 00 04 DC 01 05 06
					39 00 00 40 00 00 04 E2 05 05 05
					39 00 00 40 00 00 04 E3 03 04 03
					39 00 00 40 00 00 04 FF 5A A5 5C
					39 00 00 40 00 00 04 80 04 04 05
					39 00 00 40 00 00 04 81 02 05 01
					39 00 00 40 00 00 04 83 04 04 06
					39 00 00 40 00 00 04 94 01 01 06
					39 00 00 40 00 00 04 9A 06 0C 0B
					39 00 00 40 00 00 04 9B 06 0C 0C
					39 00 00 40 00 00 04 A5 03 05 04
					39 00 00 40 00 00 04 B7 FA 02 04
					39 00 00 40 00 00 04 B8 FA 02 00
					39 00 00 40 00 00 04 BE 03 06 03
					39 00 00 40 00 00 04 BF 03 06 02
					39 00 00 00 00 00 04 FF 5A A5 00
					//CTB 2024/8/3
					39 00 00 40 00 00 04 FF 5A A5 31
					15 00 00 40 01 00 02 D0 81
					39 00 00 40 00 00 13 80 F0 99 62 25 02 FE DB 9E 67 E0 1A 17 16 00 00 DF C8 C4
					39 00 00 40 00 00 13 81 F0 9C 65 25 02 FE DB 9B 64 E0 09 08 05 00 00 FD F4 EC
					39 00 00 40 00 00 13 82 F0 81 53 1F 02 FE E1 AD 7F E0 07 06 05 00 00 FD FC FB
					39 00 00 40 00 00 13 83 F0 70 48 1B 02 FE E5 B8 90 E0 07 06 05 00 00 FD FC FB
					39 00 00 40 00 00 13 84 F0 94 60 23 02 FE DD A0 6C E0 06 05 04 00 00 FB FA F9
					39 00 00 40 00 00 13 85 F0 7C 50 1E 02 FE E2 B0 84 E0 06 05 04 00 00 FB FA F9
					39 00 00 40 00 00 13 86 F0 99 62 25 02 FE DB 9E 67 E0 1A 17 16 00 00 CD C8 C4
					39 00 00 40 00 00 13 87 F0 9C 65 25 02 FE DB 9B 64 E0 09 08 05 00 00 FD F4 EC
					39 00 00 40 00 00 13 88 F0 81 53 1F 02 FE E1 AD 7F E0 07 06 05 00 00 FD FC FB
					39 00 00 40 00 00 13 89 F0 70 48 1B 02 FE E5 B8 90 E0 07 06 05 00 00 FD FC FB
					39 00 00 40 00 00 13 8A F0 94 60 23 02 FE DD A0 6C E0 06 05 04 00 00 FB FA F9
					39 00 00 40 00 00 13 8B F0 7C 50 1E 02 FE E2 B0 84 E0 06 05 04 00 00 FB FA F9
					15 00 00 40 01 00 02 D0 80
					39 00 00 40 00 00 07 91 04 44 55 01 01 03
					39 00 00 40 00 00 07 92 04 44 55 01 01 03
					39 00 00 40 00 00 07 93 04 44 55 01 01 03
					15 00 00 40 00 00 02 A6 00
					15 00 00 40 00 00 02 A7 10
					15 00 00 40 00 00 02 A8 00
					15 00 00 40 00 00 02 A9 10
					15 00 00 40 00 00 02 AA 00
					15 00 00 40 00 00 02 AB 10
					39 00 00 40 00 00 04 FF 5A A5 00
					//CCTC 2024/8/3
					39 00 00 40 00 00 04 FF 5A A5 2B
					39 00 00 40 00 00 05 AA 30 F7 00 00
					39 00 00 40 00 00 05 AD 30 F9 00 00
					39 00 00 40 00 00 05 B0 30 FA 00 00
					39 00 00 40 00 00 05 C4 0F 04 FB F1
					39 00 00 40 00 00 05 C5 3F DE E4 E4
					39 00 00 40 00 00 05 C7 3F F8 FD F5
					39 00 00 40 00 00 05 C8 3F E2 E9 E9
					39 00 00 40 00 00 05 CA 0F 02 E5 E8
					39 00 00 40 00 00 05 CB 3F ED EF ED
					39 00 00 40 00 00 05 CD 03 02 00 FB
					39 00 00 40 00 00 05 DF 0F 04 F1 F6
					39 00 00 40 00 00 05 E0 3F D2 EB EE
					39 00 00 40 00 00 05 E2 3F F5 F0 F8
					39 00 00 40 00 00 05 E3 3F E2 EE E2
					39 00 00 40 00 00 05 E6 3F FE F3 F4
					39 00 00 40 00 00 05 E9 3F FD F7 F5
					39 00 00 40 00 00 05 EC 3F FD FA F7
					39 00 00 00 00 00 04 FF 5A A5 00
					//Resolving 60Hz stuttering
					39 00 00 40 00 00 04 FF 5A A5 00
					39 00 00 40 00 00 02 5A 01
					39 00 00 40 00 00 02 5B 80
					39 00 00 40 00 00 04 FF 5A A5 02
					39 00 00 40 00 00 02 C0 03
					39 00 00 40 00 00 04 FF 5A A5 2D
					39 00 00 40 00 00 04 EC 01 AF 00
					39 00 00 40 00 00 03 93 A0 00
					39 00 00 40 00 00 03 94 C4 00
					39 00 00 40 00 00 03 95 00 00
					39 00 00 40 00 00 03 96 00 00
					39 00 00 40 00 00 03 ED D5 00
					39 00 00 40 00 00 04 EE 00 00 00
					39 00 00 40 00 00 02 97 02
					39 00 00 40 00 00 02 B1 03
					39 00 00 40 00 00 03 98 05 00
					39 00 00 40 00 00 03 99 0B 00
					39 00 00 40 00 00 03 9A 17 00
					39 00 00 40 00 00 03 9B 77 00
					39 00 00 40 00 00 05 A0 01 01 00 00
					39 00 00 40 00 00 05 A1 02 00 00 00
					39 00 00 40 00 00 02 B2 02
					39 00 00 40 00 00 02 B3 05
					39 00 00 40 00 00 02 B4 08
					39 00 00 40 00 00 02 B5 11
					39 00 00 40 00 00 03 BA 00 00
					39 00 00 40 00 00 03 BB 01 02
					39 00 00 40 00 00 04 FF 5A A5 02
					39 00 00 40 00 00 09 B0 00 80 00 10 00 00 00 00
					//cornor on
					39 00 00 40 00 00 04 FF 5A A5 17
					15 00 00 40 00 00 02 A0 8C
					// switch OA 120HZ
					39 00 00 40 00 00 04 FF 5A A5 00
					15 00 00 40 00 00 02 60 00
					39 00 00 40 00 00 04 FF 5A A5 2D
					39 00 00 40 00 00 03 83 00 00
					15 00 00 40 00 00 02 F2 00
					39 00 00 40 00 00 04 FF 5A A5 00
					05 00 00 00 78 00 01 11
					39 00 00 40 00 00 04 FF 5A A5 23
					15 00 00 40 00 00 02 CB 01
					39 00 00 40 00 00 04 FF 5A A5 65
					39 00 00 40 00 00 09 98 00 00 41 05 00 00 41 05
					39 00 00 40 00 00 09 99 00 00 41 05 00 00 41 05
					39 00 00 40 00 00 09 9A 00 00 41 05 00 00 41 05
					39 00 00 40 00 00 09 9B 00 00 01 1E 00 00 64 1E
					39 00 00 40 00 00 09 9C 00 00 76 1E 00 00 D8 1E
					39 00 00 40 00 00 09 9D 00 00 EA 1E 00 01 32 1E
					39 00 00 40 00 00 09 9E 00 01 32 1E 00 01 32 1E
					39 00 00 40 00 00 09 9F 00 01 40 1E 00 01 C0 1E
					39 00 00 40 00 00 09 A0 00 01 D0 1E 00 02 CE 1E
					39 00 00 40 00 00 09 A1 00 02 CE 1E 00 03 98 1E
					39 00 00 40 00 00 09 A2 00 03 98 1E 00 04 2E 1E
					39 00 00 40 00 00 09 A3 00 04 2E 1E 00 04 B0 1E
					39 00 00 40 00 00 09 A4 00 04 B0 1E 00 04 B0 1E
					39 00 00 40 00 00 09 A5 00 04 B0 1E 00 04 B0 1E
					39 00 00 40 00 00 09 A6 00 04 B0 1E 00 04 B0 1E
					39 00 00 40 00 00 09 A7 00 04 B0 1E 00 04 B0 1E
					39 00 00 40 00 00 09 A8 00 04 B0 1E 00 04 B0 1E
					39 00 00 40 00 00 09 A9 00 04 B0 1E 00 04 B0 1E
					39 00 00 40 00 00 09 AA 00 04 B0 1E 00 04 B0 1E
					39 00 00 40 00 00 09 AB 00 04 B0 1E 00 04 B0 1E
					39 00 00 40 00 00 09 AC 00 04 B0 1E 00 04 B0 1E
					39 00 00 40 00 00 09 AD 00 04 B0 1E 00 04 B0 1E
					39 00 00 40 00 00 09 AE 00 04 B0 1E 00 04 B0 1E
					39 00 00 40 00 00 09 AF 00 04 B0 1E 00 04 B0 1E
					39 00 00 40 00 00 04 FF 5A A5 75
					39 00 00 40 00 00 09 98 00 00 00 00 00 00 0F 00
					39 00 00 40 00 00 09 99 00 00 00 00 00 00 0F 00
					39 00 00 40 00 00 09 9A 00 00 00 00 00 00 0F 00
					39 00 00 40 00 00 09 9B 00 00 00 00 00 00 10 00
					39 00 00 40 00 00 09 9C 00 00 00 00 00 00 10 00
					39 00 00 40 00 00 09 9D 00 00 00 00 00 00 10 00
					39 00 00 40 00 00 09 9E 00 00 00 00 00 00 10 00
					39 00 00 40 00 00 09 9F 00 00 00 00 00 00 10 00
					39 00 00 40 00 00 09 A0 00 00 00 00 00 00 10 00
					39 00 00 40 00 00 09 A1 00 00 00 00 00 00 10 00
					39 00 00 40 00 00 09 A2 00 00 00 00 00 00 10 00
					39 00 00 40 00 00 09 A3 00 00 00 00 00 00 10 00
					39 00 00 40 00 00 09 A4 00 00 00 00 00 00 10 00
					39 00 00 40 00 00 09 A5 00 00 00 00 00 00 10 00
					39 00 00 40 00 00 09 A6 00 00 00 00 00 00 10 00
					39 00 00 40 00 00 09 A7 00 00 00 00 00 00 10 00
					39 00 00 40 00 00 09 A8 00 00 00 00 00 00 10 00
					39 00 00 40 00 00 09 A9 00 00 00 00 00 00 10 00
					39 00 00 40 00 00 09 AA 00 00 00 00 00 00 10 00
					39 00 00 40 00 00 09 AB 00 00 00 00 00 00 10 00
					39 00 00 40 00 00 09 AC 00 00 00 00 00 00 10 00
					39 00 00 40 00 00 09 AD 00 00 00 00 00 00 10 00
					39 00 00 40 00 00 09 AE 00 00 00 00 00 00 10 00
					39 00 00 40 00 00 09 AF 00 00 00 00 00 00 10 00
					39 00 00 40 00 00 04 FF 5A A5 23
					15 00 00 00 00 00 02 CB 00
					05 00 00 00 14 00 01 29
				];
				qcom,mdss-dsi-post-on-backlight = [

				];
				qcom,mdss-dsi-off-command=[
					05 00 00 00 14 00 01 28
					05 00 00 00 78 00 01 10
				];
				qcom,mdss-dsi-hbm-off-command = [
					39 00 00 00 00 00 03 51 0D BB
				];
				qcom,mdss-dsi-hbm-on-command = [
					39 00 00 40 00 00 04 FF 5A A5 1E
                                        39 00 00 40 00 00 02 80 89
                                        39 00 00 40 00 00 04 FF 5A A5 00
                                        39 00 00 00 00 00 03 51 0F 4A
				];
				qcom,mdss-dsi-panel-read-register-open-command = [
				];
				qcom,mdss-dsi-panel-read-register-close-command = [
				];
				qcom,mdss-dsi-lhbm-pressed-icon-gamma-command = [
				];
				qcom,mdss-dsi-lhbm-pressed-icon-grayscale-command = [
				];
				qcom,mdss-dsi-lhbm-pressed-icon-on-command = [
					39 00 00 40 00 00 04 FF 5A A5 00
					39 00 00 40 00 00 02 96 09
					39 00 00 40 00 00 02 97 D9
					39 00 00 40 00 00 02 98 02
					39 00 00 40 00 00 02 99 78
					39 00 00 00 00 00 02 6E 03
				];
				qcom,mdss-dsi-lhbm-pressed-icon-off-command = [
					39 00 00 40 00 00 04 FF 5A A5 00
					39 00 00 00 00 00 02 6E 00
				];
				qcom,mdss-dsi-lhbm-dbv-alpha-command = [
				];
				qcom,mdss-dsi-lp1-command = [
					39 00 00 40 00 00 04 FF 5A A5 4F
					15 00 00 40 00 00 02 88 78
					39 00 00 40 00 00 04 FF 5A A5 00
					15 00 00 40 00 00 02 60 00
					39 00 00 40 00 00 04 FF 5A A5 53
					39 00 00 40 00 00 03 85 CC E1
					39 00 00 40 00 00 04 FF 5A A5 01
					39 00 00 40 00 00 06 83 00 00 40 04 00
					15 00 00 40 00 00 02 FE 0B
					39 00 00 40 00 00 04 FF 5A A5 0B
					15 00 00 40 00 00 02 88 00
					15 00 00 40 00 00 02 A7 00
					39 00 00 40 00 00 04 FF 5A A5 51
					39 00 00 40 00 00 06 C2 46 46 46 46 00
					15 00 00 40 00 00 02 FE 00
					15 00 00 40 00 00 02 00 00
					39 00 00 40 00 00 04 FF 5A A5 00
					15 00 00 40 00 00 02 39 00
					39 00 00 40 00 00 04 FF 5A A5 4F
					15 00 00 40 00 00 02 8B 78
					/* AOD lv switch */
					39 00 00 40 00 00 04 FF 5A A5 00
					39 00 00 00 00 00 05 51 0D BB 0D BB
				];
				qcom,mdss-dsi-nolp-command = [
					39 00 00 40 00 00 04 FF 5A A5 00
					15 00 00 40 00 00 02 38 00
					39 00 00 00 00 00 05 51 00 00 00 00
				];
				qcom,mdss-dsi-nolp-onepulse-command = [
					39 00 00 40 00 00 04 FF 5A A5 4F
					15 00 00 40 00 00 02 88 78
					39 00 00 40 00 00 04 FF 5A A5 01
					39 00 00 40 00 00 03 80 0C 0C
					39 00 00 40 00 00 04 FF 5A A5 4F
					15 00 00 40 00 00 02 8A 78
					39 00 00 40 00 00 04 FF 5A A5 00
					15 00 00 40 00 00 02 60 01
					39 00 00 40 00 00 04 FF 5A A5 53
					39 00 00 40 00 00 03 85 CC E3
					39 00 00 40 00 00 04 FF 5A A5 01
					39 00 00 40 00 00 06 83 00 00 40 04 00
					15 00 00 40 00 00 02 FE 07
					39 00 00 40 00 00 04 FF 5A A5 0B
					15 00 00 40 00 00 02 88 46
					15 00 00 40 00 00 02 A7 3A
					39 00 00 40 00 00 04 FF 5A A5 51
					39 00 00 40 00 00 06 C2 46 28 28 28 00
					15 00 00 40 00 00 02 FE 00
					15 00 00 40 00 00 02 00 00
					39 00 00 40 00 00 04 FF 5A A5 01
					39 00 00 40 00 00 03 80 0C 00
					39 00 00 40 00 00 04 FF 5A A5 00
					15 00 00 40 00 00 02 38 00
					39 00 00 40 00 00 04 FF 5A A5 4F
					15 00 00 40 00 00 02 8B 78
					39 00 00 40 00 00 04 FF 5A A5 00
					39 00 00 00 00 00 05 51 00 00 00 00
				];
				qcom,mdss-dsi-aod-high-mode-command = [
					39 00 00 40 00 00 04 FF 5A A5 00
					39 00 00 00 00 00 05 51 0D BB 0D BB
				];
				qcom,mdss-dsi-aod-low-mode-command = [
					39 00 00 40 00 00 04 FF 5A A5 00
					39 00 00 00 00 00 05 51 0B 1A 0A 81
				];
				qcom,mdss-dsi-ultra-low-power-aod-on-command = [
					39 00 00 40 00 00 04 FF 5A A5 2D
					39 00 00 40 00 00 03 8A 1D 00
					39 00 00 00 00 00 04 FF 5A A5 00
				];
				qcom,mdss-dsi-ultra-low-power-aod-off-command = [
					39 00 00 40 00 00 04 FF 5A A5 2D
					39 00 00 40 00 00 03 8A 00 00
					39 00 00 00 00 00 04 FF 5A A5 00
				];
				qcom,mdss-dsi-temperature-compensation-command = [

				];
				qcom,mdss-dsi-read-compensation-reg1-command = [

				];
				qcom,mdss-dsi-pwm-switch-high-command = [
					39 00 00 40 00 00 04 FF 5A A5 4F
					15 00 00 40 00 00 02 80 01
					15 00 00 40 00 00 02 81 04
					15 00 00 40 00 00 02 88 78
					39 00 00 40 00 00 04 FF 5A A5 00
					39 00 00 40 00 00 03 51 04 8B
					39 00 00 40 00 00 04 FF 5A A5 24
					39 00 00 40 00 00 06 C9 00 00 00 10 00
					39 00 00 40 00 00 04 FE 30 00 50
					39 00 00 40 00 00 06 CA 00 80 00 B0 00
					39 00 00 40 00 00 04 FE D0 01 10
					39 00 00 40 00 00 06 CB 01 50 01 78 01
					39 00 00 40 00 00 04 FE D0 02 98
					39 00 00 40 00 00 06 CC 03 20 04 40 05
					39 00 00 40 00 00 04 FE 20 05 E8
					39 00 00 40 00 00 06 CD 06 F0 07 C8 09
					39 00 00 40 00 00 04 FE 30 0A A8
					39 00 00 40 00 00 06 CE 0B 70 0C D8 0E
					39 00 00 40 00 00 04 FE F0 0F F0
					39 00 00 40 00 00 04 FF 5A A5 4F
					15 00 00 40 00 00 02 8A 78
					39 00 00 40 00 00 04 FF 5A A5 24
					39 00 00 40 00 00 06 C9 00 00 00 10 00
					39 00 00 40 00 00 04 FE 30 00 50
					39 00 00 40 00 00 06 CA 00 80 00 B0 00
					39 00 00 40 00 00 04 FE D0 01 10
					39 00 00 40 00 00 06 CB 01 50 01 B0 02
					39 00 00 40 00 00 04 FE 10 02 B0
					39 00 00 40 00 00 06 CC 03 70 04 70 05
					39 00 00 40 00 00 04 FE 70 06 30
					39 00 00 40 00 00 06 CD 07 10 08 10 09
					39 00 00 40 00 00 04 FE 80 0A F0
					39 00 00 40 00 00 06 CE 0B A0 0D 10 0E
					39 00 00 40 00 00 04 FE F0 0F F0
					39 00 00 40 00 00 04 FF 5A A5 4F
					15 00 00 00 00 00 02 8B 78
				];
				qcom,mdss-dsi-pwm-switch-low-command = [
					39 00 00 40 00 00 04 FF 5A A5 4F
					15 00 00 40 00 00 02 80 01
					15 00 00 40 00 00 02 81 04
					15 00 00 40 00 00 02 88 78
					39 00 00 40 00 00 04 FF 5A A5 00
					39 00 00 40 00 00 03 51 04 8A
					39 00 00 40 00 00 04 FF 5A A5 24
					39 00 00 40 00 00 06 C9 00 00 00 10 00
					39 00 00 40 00 00 04 FE 30 00 50
					39 00 00 40 00 00 06 CA 00 80 00 B0 00
					39 00 00 40 00 00 04 FE D0 01 20
					39 00 00 40 00 00 06 CB 01 68 01 A0 02
					39 00 00 40 00 00 04 FE 28 02 D0
					39 00 00 40 00 00 06 CC 03 60 04 A0 05
					39 00 00 40 00 00 04 FE B0 06 78
					39 00 00 40 00 00 06 CD 07 30 08 50 09
					39 00 00 40 00 00 04 FE E0 0B 44
					39 00 00 40 00 00 06 CE 0B D8 0D 10 0E
					39 00 00 40 00 00 04 FE F0 0F F0
					39 00 00 40 00 00 04 FF 5A A5 4F
					15 00 00 40 00 00 02 8A 78
					39 00 00 40 00 00 04 FF 5A A5 24
					39 00 00 40 00 00 06 C9 00 00 00 10 00
					39 00 00 40 00 00 04 FE 30 00 50
					39 00 00 40 00 00 06 CA 00 80 00 B0 00
					39 00 00 40 00 00 04 FE D0 01 10
					39 00 00 40 00 00 06 CB 01 50 01 B0 02
					39 00 00 40 00 00 04 FE 10 02 B0
					39 00 00 40 00 00 06 CC 03 70 04 70 05
					39 00 00 40 00 00 04 FE 70 06 30
					39 00 00 40 00 00 06 CD 07 10 08 10 09
					39 00 00 40 00 00 04 FE 80 0A F0
					39 00 00 40 00 00 06 CE 0B A0 0D 10 0E
					39 00 00 40 00 00 04 FE F0 0F F0
					39 00 00 40 00 00 04 FF 5A A5 4F
					15 00 00 00 00 00 02 8B 78
				];
				qcom,mdss-dsi-pwm-switch-onepulse-command = [
				];
				qcom,mdss-dsi-pwm-switch-onepulse-low-command = [
				];
				qcom,mdss-dsi-pwm-switch-1to3-command = [
					39 00 00 40 00 00 04 FF 5A A5 4F
					15 00 00 40 00 00 02 88 78
					39 00 00 40 00 00 04 FF 5A A5 01
					39 00 00 40 00 00 06 83 00 00 40 04 00
					15 00 00 40 00 00 02 FE 0B
					39 00 00 40 00 00 04 FF 5A A5 0B
					15 00 00 40 00 00 02 88 00
					15 00 00 40 00 00 02 A7 00
					39 00 00 40 00 00 04 FF 5A A5 51
					39 00 00 40 00 00 06 C2 46 46 46 46 00
					15 00 00 40 00 00 02 FE 00
					15 00 00 40 00 00 02 00 00
					39 00 00 40 00 00 06 A0 98 98 A4 A8 22
					15 00 00 40 00 00 02 FE 22
					15 00 00 40 00 00 02 00 00
					39 00 00 40 00 00 06 A1 CC D0 D0 A2 22
					15 00 00 40 00 00 02 FE 22
					15 00 00 40 00 00 02 00 00
					39 00 00 40 00 00 06 A2 A4 A6 99 9A 22
					15 00 00 40 00 00 02 FE 22
					15 00 00 40 00 00 02 00 00
					39 00 00 40 00 00 04 FF 5A A5 52
					39 00 00 40 00 00 06 80 DA BC 58 B1 11
					15 00 00 40 00 00 02 FE 01
					15 00 00 40 00 00 02 00 00
					39 00 00 40 00 00 06 81 4D 4D 4D 4E 00
					15 00 00 40 00 00 02 FE 00
					15 00 00 40 00 00 02 00 00
					39 00 00 40 00 00 06 82 4D 4E 4D 4D 00
					15 00 00 40 00 00 02 FE 00
					15 00 00 40 00 00 02 00 00
					39 00 00 40 00 00 04 FF 5A A5 00
					//120hz 3pulse
					15 00 00 40 00 00 02 60 00
					39 00 00 40 00 00 04 FF 5A A5 4F
					15 00 00 40 00 00 02 8B 78
					39 00 00 40 00 00 04 FF 5A A5 53
					15 00 00 40 00 00 02 F0 01
					39 00 00 40 00 00 04 FF 5A A5 63
					39 00 00 40 00 00 11 F1 00 00 00 00 00 00 00 00 00 00 00 00 00 00 00 00
					39 00 00 40 00 00 11 F2 10 10 10 10 10 00 00 00 00 00 00 00 00 00 00 00
					39 00 00 40 00 00 11 F3 00 00 00 00 00 20 20 20 20 20 00 00 00 00 00 00
					39 00 00 40 00 00 11 F4 00 00 00 00 00 FF FF FF FF FF 00 00 00 00 00 00
					39 00 00 40 00 00 04 FF 5A A5 53
					15 00 00 40 00 00 02 F0 00
					39 00 00 00 00 00 04 FF 5A A5 00
				];
				qcom,mdss-dsi-pwm-switch-3to1-command = [
					39 00 00 40 00 00 04 FF 5A A5 4F
					15 00 00 40 00 00 02 88 78
					39 00 00 40 00 00 04 FF 5A A5 01
					39 00 00 40 00 00 03 80 0C 0C
					39 00 00 40 00 00 04 FF 5A A5 4F
					15 00 00 40 00 00 02 8A 78
					39 00 00 40 00 00 04 FF 5A A5 01
					39 00 00 40 00 00 06 83 00 00 40 04 00
					15 00 00 40 00 00 02 FE 07
					39 00 00 40 00 00 04 FF 5A A5 0B
					15 00 00 40 00 00 02 88 46
					15 00 00 40 00 00 02 A7 3A
					39 00 00 40 00 00 04 FF 5A A5 51
					39 00 00 40 00 00 06 C2 46 28 28 28 00
					15 00 00 40 00 00 02 FE 00
					15 00 00 40 00 00 02 00 00
					39 00 00 40 00 00 06 A0 98 98 6C 69 22
					15 00 00 40 00 00 02 FE 22
					15 00 00 40 00 00 02 00 00
					39 00 00 40 00 00 06 A1 8C 91 91 74 22
					15 00 00 40 00 00 02 FE 22
					15 00 00 40 00 00 02 00 00
					39 00 00 40 00 00 06 A2 68 72 72 72 22
					15 00 00 40 00 00 02 FE 22
					15 00 00 40 00 00 02 00 00
					39 00 00 40 00 00 04 FF 5A A5 52
					// VRR
					39 00 00 40 00 00 06 80 DA BC 49 A5 11
					15 00 00 40 00 00 02 FE 01
					15 00 00 40 00 00 02 00 00
					39 00 00 40 00 00 06 81 3D 3E 3E 3F 00
					15 00 00 40 00 00 02 FE 00
					15 00 00 40 00 00 02 00 00
					39 00 00 40 00 00 06 82 41 23 23 23 00
					15 00 00 40 00 00 02 FE 00
					15 00 00 40 00 00 02 00 00
					39 00 00 40 00 00 04 FF 5A A5 00
					//120hz 1pulse
					15 00 00 40 00 00 02 60 01
					39 00 00 40 00 00 04 FF 5A A5 01
					39 00 00 40 00 00 03 80 0C 00
					39 00 00 40 00 00 04 FF 5A A5 4F
					15 00 00 40 00 00 02 8B 78
					39 00 00 40 00 00 04 FF 5A A5 53
					15 00 00 40 00 00 02 F0 01
					39 00 00 40 00 00 04 FF 5A A5 63
					39 00 00 40 00 00 11 F1 20 20 20 20 20 20 20 20 20 20 00 00 00 00 00 00
					39 00 00 40 00 00 11 F2 00 00 00 00 00 00 00 00 00 00 00 00 00 00 00 00
					39 00 00 40 00 00 11 F3 00 00 00 00 00 00 00 00 00 00 00 00 00 00 00 00
					39 00 00 40 00 00 11 F4 FF FF FF FF FF FF FF FF FF FF 00 00 00 00 00 00
					39 00 00 40 00 00 04 FF 5A A5 53
					15 00 00 40 00 00 02 F0 00
					39 00 00 00 00 00 04 FF 5A A5 00
				];
				qcom,mdss-dsi-timming-pwm-switch-onepulse-command = [
					39 00 00 40 00 00 04 FF 5A A5 00
					15 00 00 40 00 00 02 60 01
					39 00 00 40 00 00 04 FF 5A A5 2D
					39 00 00 40 00 00 03 84 00 00
					15 00 00 40 00 00 02 F2 00
					39 00 00 00 00 00 04 FF 5A A5 00
				];
				qcom,mdss-dsi-power-on-pwm-switch-onepulse-command = [
					39 00 00 40 00 00 04 FF 5A A5 4F
					15 00 00 40 00 00 02 88 78
					39 00 00 40 00 00 04 FF 5A A5 01
					39 00 00 40 00 00 03 80 0C 0C
					39 00 00 40 00 00 04 FF 5A A5 4F
					15 00 00 40 00 00 02 8A 78
					39 00 00 40 00 00 04 FF 5A A5 01
					39 00 00 40 00 00 06 83 00 00 40 04 00
					15 00 00 40 00 00 02 FE 07
					39 00 00 40 00 00 04 FF 5A A5 0B
					15 00 00 40 00 00 02 88 46
					15 00 00 40 00 00 02 A7 3A
					39 00 00 40 00 00 04 FF 5A A5 51
					39 00 00 40 00 00 06 C2 46 28 28 28 00
					15 00 00 40 00 00 02 FE 00
					15 00 00 40 00 00 02 00 00
					39 00 00 40 00 00 06 A0 98 98 6C 69 22
					15 00 00 40 00 00 02 FE 22
					15 00 00 40 00 00 02 00 00
					39 00 00 40 00 00 06 A1 8C 91 91 74 22
					15 00 00 40 00 00 02 FE 22
					15 00 00 40 00 00 02 00 00
					39 00 00 40 00 00 06 A2 68 72 72 72 22
					15 00 00 40 00 00 02 FE 22
					15 00 00 40 00 00 02 00 00
					39 00 00 40 00 00 04 FF 5A A5 52
					// VRR
					39 00 00 40 00 00 06 80 DA BC 49 A5 11
					15 00 00 40 00 00 02 FE 01
					15 00 00 40 00 00 02 00 00
					39 00 00 40 00 00 06 81 3D 3E 3E 3F 00
					15 00 00 40 00 00 02 FE 00
					15 00 00 40 00 00 02 00 00
					39 00 00 40 00 00 06 82 41 23 23 23 00
					15 00 00 40 00 00 02 FE 00
					15 00 00 40 00 00 02 00 00
					39 00 00 40 00 00 04 FF 5A A5 00
					//120hz 1pulse
					15 00 00 40 00 00 02 60 01
					39 00 00 40 00 00 04 FF 5A A5 01
					39 00 00 40 00 00 03 80 0C 00
					39 00 00 40 00 00 04 FF 5A A5 4F
					15 00 00 40 00 00 02 8B 78
					39 00 00 40 00 00 04 FF 5A A5 53
					15 00 00 40 00 00 02 F0 01
					39 00 00 40 00 00 04 FF 5A A5 63
					39 00 00 40 00 00 11 F1 20 20 20 20 20 20 20 20 20 20 00 00 00 00 00 00
					39 00 00 40 00 00 11 F2 00 00 00 00 00 00 00 00 00 00 00 00 00 00 00 00
					39 00 00 40 00 00 11 F3 00 00 00 00 00 00 00 00 00 00 00 00 00 00 00 00
					39 00 00 40 00 00 11 F4 FF FF FF FF FF FF FF FF FF FF 00 00 00 00 00 00
					39 00 00 40 00 00 04 FF 5A A5 53
					15 00 00 40 00 00 02 F0 00
					39 00 00 00 10 00 04 FF 5A A5 00
				];
				qcom,mdss-dsi-power-on-pwm-switch-high-command = [
				];
				qcom,mdss-dsi-power-on-pwm-switch-low-command = [
				];

				qcom,mdss-dsi-osc-track-on-command = [
				];
				qcom,mdss-dsi-osc-track-off-command = [
				];
				qcom,mdss-dsi-hbm-max-command = [
					39 00 00 00 00 00 03 51 10 ED
				];

				qcom,mdss-dsi-hbm-exit-max-command = [
					39 00 00 00 00 00 03 51 0F FE
				];
				qcom,mdss-dsi-lp1-command-state = "dsi_lp_pack_mode";
				qcom,mdss-dsi-nolp-command-state = "dsi_lp_pack_mode";
				qcom,mdss-dsi-nolp-onepulse-command-state = "dsi_lp_pack_mode";
				qcom,mdss-dsi-nolp-hpwm-command-state = "dsi_lp_pack_mode";
				qcom,mdss-dsi-hbm-on-command-state = "dsi_lp_pack_mode";
				qcom,mdss-dsi-hbm-off-command-state = "dsi_lp_pack_mode";
				qcom,mdss-dsi-panel-read-register-open-state = "dsi_lp_mode";
				qcom,mdss-dsi-panel-read-register-close-state = "dsi_lp_mode";
				qcom,mdss-dsi-lhbm-pressed-icon-gamma-command-state = "dsi_lp_mode";
				qcom,mdss-dsi-lhbm-pressed-icon-grayscale-command-state = "dsi_lp_mode";
				qcom,mdss-dsi-lhbm-pressed-icon-on-command-state = "dsi_lp_mode";
				qcom,mdss-dsi-lhbm-pressed-icon-off-command-state = "dsi_lp_mode";
				qcom,mdss-dsi-lhbm-dbv-alpha-command-state = "dsi_hs_mode";
				qcom,mdss-dsi-reset-scanline-command-state = "dsi_hs_mode";
				qcom,mdss-dsi-recovery-scanline-command-state = "dsi_hs_mode";

				qcom,mdss-dsi-osc-track-on-command-state = "dsi_hs_mode";
				qcom,mdss-dsi-osc-track-off-command-state = "dsi_hs_mode";
				qcom,mdss-dsi-hbm-max-command-state = "dsi_hs_mode";
				qcom,mdss-dsi-hbm-exit-max-command-state = "dsi_hs_mode";

				qcom,lm-split = <632 632>;
				qcom,compression-mode = "dsc";
				qcom,mdss-dsc-encoders = <2>;
				qcom,mdss-dsc-slice-height = <20>;
				qcom,mdss-dsc-slice-width = <632>;
				qcom,mdss-dsc-slice-per-pkt = <2>;
				qcom,mdss-dsc-bit-per-component = <10>;
				qcom,mdss-dsc-bit-per-pixel = <8>;
				qcom,mdss-dsc-block-prediction-enable;
			};
		};
	};
};

&soc {
	dsi_panel_AA577_P_3_A0020_dsc_cmd {
		qcom,dsi-display-active;
	};
};

&dsi_panel_AA577_P_3_A0020_dsc_cmd {
	qcom,panel-supply-entries = <&oplus_dsi_panel_custom_pwr_supply>;
	qcom,mdss-dsi-bl-pmic-control-type = "bl_ctrl_dcs";
	qcom,bl-update-flag = "delay_until_first_frame";
	qcom,mdss-dsi-bl-min-level = <1>;
	qcom,mdss-dsi-bl-max-level = <4094>;
	qcom,mdss-brightness-max-level = <4094>;
	oplus,dsi-bl-normal-max-level = <2951>;
	oplus,dsi-brightness-normal-max-level = <2951>;
	oplus,dsi-dc-backlight-threshold = <1960>;
	oplus,dsi-brightness-default-level = <1638>;
	qcom,platform-te-gpio = <&tlmm 86 0>;
	qcom,platform-reset-gpio = <&tlmm 133 0>;
	qcom,platform-panel-vout-gpio = <&tlmm 91 0>;

	qcom,mdss-dsi-bl-inverted-dbv;
	qcom,ulps-enabled;
	qcom,dsi-select-clocks = "pll_byte_clk0", "pll_dsi_clk0";
	oplus,enhance_mipi_strength;
	oplus,vreg_ctrl_flag;

	/* ofp config */
	oplus,ofp-fp-type = <0x90>;
	oplus,ofp-longrui-aod-config = <0x02>;
	oplus,ofp-need-to-wait-data-before-aod-on;
	/* adfr config */
	oplus,adfr-config = <0xe51>;  // 0b0000'0000'0101'0001
	oplus,adfr-test-te-gpio = <&tlmm 85 0>;
	/* just for qsync enable*/
	qcom,qsync-enable;
	qcom,mdss-dsi-qsync-min-refresh-rate = <30>;

	// qcom,dsi-dyn-clk-enable;

	qcom,mdss-dsi-display-timings {
		timing@sdc_fhd_120 { /* FHD+ 120hz 1094.4Mbps */
			qcom,mdss-dsi-panel-phy-timings = [00 23 09 09 1A 24 09 09 09 02 04 00 1D 0E];
			qcom,display-topology = <1 1 1>,<2 2 1>;
			qcom,default-topology-index = <1>;
			qcom,partial-update-enabled = "single_roi";
			qcom,panel-roi-alignment = <1264 60 1264 60 1264 60>;
		};
		timing@sdc_fhd_90 { /* FHD+ 120hz 1094.4Mbps */
			qcom,mdss-dsi-panel-phy-timings = [00 23 09 09 1A 24 09 09 09 02 04 00 1D 0E];
			qcom,display-topology = <1 1 1>,<2 2 1>;
			qcom,default-topology-index = <1>;
			qcom,partial-update-enabled = "single_roi";
			qcom,panel-roi-alignment = <1264 60 1264 60 1264 60>;
		};
		timing@sdc_fhd_60 { /* FHD+ 120hz 1094.4Mbps */
			qcom,mdss-dsi-panel-phy-timings = [00 23 09 09 1A 24 09 09 09 02 04 00 1D 0E];
			qcom,display-topology = <1 1 1>,<2 2 1>;
			qcom,default-topology-index = <1>;
			qcom,partial-update-enabled = "single_roi";
			qcom,panel-roi-alignment = <1264 60 1264 60 1264 60>;
		};
		timing@oplus_fhd_120 { /* FHD+ 120hz 1094.4Mbps */
			qcom,mdss-dsi-panel-phy-timings = [00 23 09 09 1A 24 09 09 09 02 04 00 1D 0E];
			qcom,display-topology = <1 1 1>,<2 2 1>;
			qcom,default-topology-index = <1>;
			qcom,partial-update-enabled = "single_roi";
			qcom,panel-roi-alignment = <1264 60 1264 60 1264 60>;
		};
	};
};

&dsi_panel_AA577_P_3_A0020_dsc_cmd {
	qcom,mdss-dsi-display-timings {
		timing@sdc_fhd_120 { /* FHD+ 120hz 1094.4Mbps */
			/* standard adfr */
			qcom,disable-rsc-solver;
			qcom,mdss-dsi-h-sync-skew = <0>;
			oplus,adfr-min-fps-mapping-table = <120 60 30 20 10 1>;
			oplus,adfr-idle-off-min-fps = <20>;
			oplus,adfr-high-precision-fps-mapping-table = <120 90 72 60>;

			qcom,mdss-dsi-adfr-min-fps-0-command = [
				39 00 00 40 00 00 04 FF 5A A5 2D
				39 00 00 40 00 00 03 83 00 00
				39 00 00 00 00 00 04 FF 5A A5 00
			];
			qcom,mdss-dsi-adfr-min-fps-1-command = [
				39 00 00 40 00 00 04 FF 5A A5 2D
				39 00 00 40 00 00 03 83 01 00
				39 00 00 00 00 00 04 FF 5A A5 00
			];
			qcom,mdss-dsi-adfr-min-fps-2-command = [
				39 00 00 40 00 00 04 FF 5A A5 2D
				39 00 00 40 00 00 03 83 03 00
				39 00 00 00 00 00 04 FF 5A A5 00
			];
			qcom,mdss-dsi-adfr-min-fps-3-command = [
				39 00 00 40 00 00 04 FF 5A A5 2D
				39 00 00 40 00 00 03 83 05 00
				39 00 00 00 00 00 04 FF 5A A5 00
			];
			qcom,mdss-dsi-adfr-min-fps-4-command = [
				39 00 00 40 00 00 04 FF 5A A5 2D
				39 00 00 40 00 00 03 83 0B 00
				39 00 00 00 00 00 04 FF 5A A5 00
			];
			qcom,mdss-dsi-adfr-min-fps-5-command = [
				39 00 00 40 00 00 04 FF 5A A5 2D
				39 00 00 40 00 00 03 83 77 00
				39 00 00 00 00 00 04 FF 5A A5 00
			];
			qcom,mdss-dsi-hpwm-adfr-min-fps-0-command = [
				39 00 00 40 00 00 04 FF 5A A5 2D
				39 00 00 40 00 00 03 83 00 00
				39 00 00 00 00 00 04 FF 5A A5 00
			];
			qcom,mdss-dsi-hpwm-adfr-min-fps-1-command = [
				39 00 00 40 00 00 04 FF 5A A5 2D
				39 00 00 40 00 00 03 83 01 00
				39 00 00 00 00 00 04 FF 5A A5 00
			];
			qcom,mdss-dsi-hpwm-adfr-min-fps-2-command = [
				39 00 00 40 00 00 04 FF 5A A5 2D
				39 00 00 40 00 00 03 83 03 00
				39 00 00 00 00 00 04 FF 5A A5 00
			];
			qcom,mdss-dsi-hpwm-adfr-min-fps-3-command = [
				39 00 00 40 00 00 04 FF 5A A5 2D
				39 00 00 40 00 00 03 83 05 00
				39 00 00 00 00 00 04 FF 5A A5 00
			];
			qcom,mdss-dsi-hpwm-adfr-min-fps-4-command = [
				39 00 00 40 00 00 04 FF 5A A5 2D
				39 00 00 40 00 00 03 83 0B 00
				39 00 00 00 00 00 04 FF 5A A5 00
			];
			qcom,mdss-dsi-hpwm-adfr-min-fps-5-command = [
				39 00 00 40 00 00 04 FF 5A A5 2D
				39 00 00 40 00 00 03 83 77 00
				39 00 00 00 00 00 04 FF 5A A5 00
			];
			qcom,mdss-dsi-bigdc-adfr-min-fps-0-command = [
				39 00 00 40 00 00 04 FF 5A A5 2D
				39 00 00 40 00 00 03 84 00 00
				39 00 00 00 00 00 04 FF 5A A5 00
			];
			qcom,mdss-dsi-bigdc-adfr-min-fps-1-command = [
				39 00 00 40 00 00 04 FF 5A A5 2D
				39 00 00 40 00 00 03 84 01 00
				39 00 00 00 00 00 04 FF 5A A5 00
			];
			qcom,mdss-dsi-bigdc-adfr-min-fps-2-command = [
				39 00 00 40 00 00 04 FF 5A A5 2D
				39 00 00 40 00 00 03 84 03 00
				39 00 00 00 00 00 04 FF 5A A5 00
			];
			qcom,mdss-dsi-bigdc-adfr-min-fps-3-command = [
				39 00 00 40 00 00 04 FF 5A A5 2D
				39 00 00 40 00 00 03 84 05 00
				39 00 00 00 00 00 04 FF 5A A5 00
			];
			qcom,mdss-dsi-bigdc-adfr-min-fps-4-command = [
				39 00 00 40 00 00 04 FF 5A A5 2D
				39 00 00 40 00 00 03 84 0B 00
				39 00 00 00 00 00 04 FF 5A A5 00
			];
			qcom,mdss-dsi-bigdc-adfr-min-fps-5-command = [
				39 00 00 40 00 00 04 FF 5A A5 2D
				39 00 00 40 00 00 03 84 77 00
				39 00 00 00 00 00 04 FF 5A A5 00
			];

			qcom,mdss-dsi-adfr-high-precision-fps-0-command = [
				39 00 00 40 00 00 04 FF 5A A5 2D
				39 00 00 40 00 00 02 F2 00
				39 00 00 40 00 00 04 FF 5A A5 02
				39 00 00 40 00 00 05 C0 03 00 00 02
				39 00 00 00 00 00 09 B0 00 80 00 10 00 00 00 00
				39 00 00 40 00 00 04 FF 5A A5 00
				15 00 00 00 00 00 02 60 00
			];
			qcom,mdss-dsi-adfr-high-precision-fps-1-command = [
				39 00 00 40 00 00 04 FF 5A A5 02
				39 00 00 40 00 00 05 C0 03 00 00 02
				39 00 00 00 00 00 09 B0 00 83 00 10 00 00 00 00
				39 00 00 40 00 00 04 FF 5A A5 00
				15 00 00 00 00 00 02 60 02
			];
			qcom,mdss-dsi-adfr-high-precision-fps-2-command = [
				39 00 00 40 00 00 04 FF 5A A5 02
				39 00 00 40 00 00 05 C0 03 00 00 02
				39 00 00 00 00 00 09 B0 00 83 00 10 00 00 00 00
				39 00 00 40 00 00 04 FF 5A A5 00
				15 00 00 00 00 00 02 60 04
			];
			qcom,mdss-dsi-adfr-high-precision-fps-3-command = [
				39 00 00 40 00 00 04 FF 5A A5 2D
				39 00 00 40 00 00 02 F2 01
				39 00 00 40 00 00 04 FF 5A A5 02
				39 00 00 40 00 00 05 C0 03 00 00 02
				39 00 00 00 00 00 09 B0 00 80 00 10 00 00 00 00
				39 00 00 40 00 00 04 FF 5A A5 00
				15 00 00 00 00 00 02 60 00
			];

			qcom,mdss-dsi-hpwm-adfr-high-precision-fps-0-command = [
				39 00 00 40 00 00 04 FF 5A A5 2D
				39 00 00 40 00 00 02 F2 00
				39 00 00 40 00 00 04 FF 5A A5 02
				39 00 00 40 00 00 05 C0 03 00 00 02
				39 00 00 00 00 00 09 B0 00 80 00 10 00 00 00 00
				39 00 00 40 00 00 04 FF 5A A5 00
				15 00 00 00 00 00 02 60 00
			];
			qcom,mdss-dsi-hpwm-adfr-high-precision-fps-1-command = [
				39 00 00 00 00 00 04 FF 5A A5 00
			];
			qcom,mdss-dsi-hpwm-adfr-high-precision-fps-2-command = [
				39 00 00 00 00 00 04 FF 5A A5 00
			];
			qcom,mdss-dsi-hpwm-adfr-high-precision-fps-3-command = [
				39 00 00 40 00 00 04 FF 5A A5 2D
				39 00 00 40 00 00 02 F2 01
				39 00 00 40 00 00 04 FF 5A A5 02
				39 00 00 40 00 00 05 C0 03 00 00 02
				39 00 00 00 00 00 09 B0 00 80 00 10 00 00 00 00
				39 00 00 40 00 00 04 FF 5A A5 00
				15 00 00 00 00 00 02 60 00
			];

			qcom,mdss-dsi-bigdc-adfr-high-precision-fps-0-command = [
				39 00 00 40 00 00 04 FF 5A A5 2D
				39 00 00 40 00 00 02 F2 00
				39 00 00 40 00 00 04 FF 5A A5 02
				39 00 00 40 00 00 05 C0 03 00 00 02
				39 00 00 00 00 00 09 B0 00 80 00 10 00 00 00 00
				39 00 00 40 00 00 04 FF 5A A5 00
				15 00 00 00 00 00 02 60 01
			];
			qcom,mdss-dsi-bigdc-adfr-high-precision-fps-1-command = [
				39 00 00 00 00 00 04 FF 5A A5 00
			];
			qcom,mdss-dsi-bigdc-adfr-high-precision-fps-2-command = [
				39 00 00 00 00 00 04 FF 5A A5 00
			];
			qcom,mdss-dsi-bigdc-adfr-high-precision-fps-3-command = [
				39 00 00 40 00 00 04 FF 5A A5 2D
				39 00 00 40 00 00 02 F2 01
				39 00 00 40 00 00 04 FF 5A A5 02
				39 00 00 40 00 00 05 C0 03 00 00 02
				39 00 00 00 00 00 09 B0 00 80 00 10 00 00 00 00
				39 00 00 40 00 00 04 FF 5A A5 00
				15 00 00 00 00 00 02 60 01
			];

			qcom,mdss-dsi-adfr-min-fps-0-command-state = "dsi_hs_mode";
			qcom,mdss-dsi-adfr-min-fps-1-command-state = "dsi_hs_mode";
			qcom,mdss-dsi-adfr-min-fps-2-command-state = "dsi_hs_mode";
			qcom,mdss-dsi-adfr-min-fps-3-command-state = "dsi_hs_mode";
			qcom,mdss-dsi-adfr-min-fps-4-command-state = "dsi_hs_mode";
			qcom,mdss-dsi-adfr-min-fps-5-command-state = "dsi_hs_mode";
			qcom,mdss-dsi-hpwm-adfr-min-fps-0-command-state = "dsi_hs_mode";
			qcom,mdss-dsi-hpwm-adfr-min-fps-1-command-state = "dsi_hs_mode";
			qcom,mdss-dsi-hpwm-adfr-min-fps-2-command-state = "dsi_hs_mode";
			qcom,mdss-dsi-hpwm-adfr-min-fps-3-command-state = "dsi_hs_mode";
			qcom,mdss-dsi-hpwm-adfr-min-fps-4-command-state = "dsi_hs_mode";
			qcom,mdss-dsi-hpwm-adfr-min-fps-5-command-state = "dsi_hs_mode";
			qcom,mdss-dsi-bigdc-adfr-min-fps-0-command-state = "dsi_hs_mode";
			qcom,mdss-dsi-bigdc-adfr-min-fps-1-command-state = "dsi_hs_mode";
			qcom,mdss-dsi-bigdc-adfr-min-fps-2-command-state = "dsi_hs_mode";
			qcom,mdss-dsi-bigdc-adfr-min-fps-3-command-state = "dsi_hs_mode";
			qcom,mdss-dsi-bigdc-adfr-min-fps-4-command-state = "dsi_hs_mode";
			qcom,mdss-dsi-bigdc-adfr-min-fps-5-command-state = "dsi_hs_mode";
			qcom,mdss-dsi-adfr-high-precision-fps-0-command-state = "dsi_hs_mode";
			qcom,mdss-dsi-adfr-high-precision-fps-1-command-state = "dsi_hs_mode";
			qcom,mdss-dsi-adfr-high-precision-fps-2-command-state = "dsi_hs_mode";
			qcom,mdss-dsi-adfr-high-precision-fps-3-command-state = "dsi_hs_mode";
			qcom,mdss-dsi-hpwm-adfr-high-precision-fps-0-command-state = "dsi_hs_mode";
			qcom,mdss-dsi-hpwm-adfr-high-precision-fps-1-command-state = "dsi_hs_mode";
			qcom,mdss-dsi-hpwm-adfr-high-precision-fps-2-command-state = "dsi_hs_mode";
			qcom,mdss-dsi-hpwm-adfr-high-precision-fps-3-command-state = "dsi_hs_mode";
			qcom,mdss-dsi-bigdc-adfr-high-precision-fps-0-command-state = "dsi_hs_mode";
			qcom,mdss-dsi-bigdc-adfr-high-precision-fps-1-command-state = "dsi_hs_mode";
			qcom,mdss-dsi-bigdc-adfr-high-precision-fps-2-command-state = "dsi_hs_mode";
			qcom,mdss-dsi-bigdc-adfr-high-precision-fps-3-command-state = "dsi_hs_mode";
		};
		timing@sdc_fhd_90 { /* FHD+ 120hz 1094.4Mbps */
			/* standard adfr */
			qcom,mdss-dsi-h-sync-skew = <0>;
			oplus,adfr-min-fps-mapping-table = <90 45 30 15 10 1>;
			oplus,adfr-idle-off-min-fps = <15>;

			qcom,mdss-dsi-adfr-min-fps-0-command = [
				39 00 00 40 00 00 04 FF 5A A5 2D
				39 00 00 40 00 00 03 85 00 00
				39 00 00 00 00 00 04 FF 5A A5 00
			];
			qcom,mdss-dsi-adfr-min-fps-1-command = [
				39 00 00 40 00 00 04 FF 5A A5 2D
				39 00 00 40 00 00 03 85 01 00
				39 00 00 00 00 00 04 FF 5A A5 00
			];
			qcom,mdss-dsi-adfr-min-fps-2-command = [
				39 00 00 40 00 00 04 FF 5A A5 2D
				39 00 00 40 00 00 03 85 02 00
				39 00 00 00 00 00 04 FF 5A A5 00
			];
			qcom,mdss-dsi-adfr-min-fps-3-command = [
				39 00 00 40 00 00 04 FF 5A A5 2D
				39 00 00 40 00 00 03 85 05 00
				39 00 00 00 00 00 04 FF 5A A5 00
			];
			qcom,mdss-dsi-adfr-min-fps-4-command = [
				39 00 00 40 00 00 04 FF 5A A5 2D
				39 00 00 40 00 00 03 85 08 00
				39 00 00 00 00 00 04 FF 5A A5 00
			];
			qcom,mdss-dsi-adfr-min-fps-5-command = [
				39 00 00 40 00 00 04 FF 5A A5 2D
				39 00 00 40 00 00 03 85 59 00
				39 00 00 00 00 00 04 FF 5A A5 00
			];
			qcom,mdss-dsi-hpwm-adfr-min-fps-0-command = [
				39 00 00 40 00 00 04 FF 5A A5 2D
				39 00 00 40 00 00 03 85 00 00
				39 00 00 00 00 00 04 FF 5A A5 00
			];
			qcom,mdss-dsi-hpwm-adfr-min-fps-1-command = [
				39 00 00 40 00 00 04 FF 5A A5 2D
				39 00 00 40 00 00 03 85 01 00
				39 00 00 00 00 00 04 FF 5A A5 00
			];
			qcom,mdss-dsi-hpwm-adfr-min-fps-2-command = [
				39 00 00 40 00 00 04 FF 5A A5 2D
				39 00 00 40 00 00 03 85 02 00
				39 00 00 00 00 00 04 FF 5A A5 00
			];
			qcom,mdss-dsi-hpwm-adfr-min-fps-3-command = [
				39 00 00 40 00 00 04 FF 5A A5 2D
				39 00 00 40 00 00 03 85 05 00
				39 00 00 00 00 00 04 FF 5A A5 00
			];
			qcom,mdss-dsi-hpwm-adfr-min-fps-4-command = [
				39 00 00 40 00 00 04 FF 5A A5 2D
				39 00 00 40 00 00 03 85 08 00
				39 00 00 00 00 00 04 FF 5A A5 00
			];
			qcom,mdss-dsi-hpwm-adfr-min-fps-5-command = [
				39 00 00 40 00 00 04 FF 5A A5 2D
				39 00 00 40 00 00 03 85 59 00
				39 00 00 00 00 00 04 FF 5A A5 00
			];
			qcom,mdss-dsi-bigdc-adfr-min-fps-0-command = [
				39 00 00 40 00 00 04 FF 5A A5 2D
				39 00 00 40 00 00 03 86 00 00
				39 00 00 00 00 00 04 FF 5A A5 00
			];
			qcom,mdss-dsi-bigdc-adfr-min-fps-1-command = [
				39 00 00 40 00 00 04 FF 5A A5 2D
				39 00 00 40 00 00 03 86 01 00
				39 00 00 00 00 00 04 FF 5A A5 00
			];
			qcom,mdss-dsi-bigdc-adfr-min-fps-2-command = [
				39 00 00 40 00 00 04 FF 5A A5 2D
				39 00 00 40 00 00 03 86 02 00
				39 00 00 00 00 00 04 FF 5A A5 00
			];
			qcom,mdss-dsi-bigdc-adfr-min-fps-3-command = [
				39 00 00 40 00 00 04 FF 5A A5 2D
				39 00 00 40 00 00 03 86 05 00
				39 00 00 00 00 00 04 FF 5A A5 00
			];
			qcom,mdss-dsi-bigdc-adfr-min-fps-4-command = [
				39 00 00 40 00 00 04 FF 5A A5 2D
				39 00 00 40 00 00 03 86 08 00
				39 00 00 00 00 00 04 FF 5A A5 00
			];
			qcom,mdss-dsi-bigdc-adfr-min-fps-5-command = [
				39 00 00 40 00 00 04 FF 5A A5 2D
				39 00 00 40 00 00 03 86 59 00
				39 00 00 00 00 00 04 FF 5A A5 00
			];

			qcom,mdss-dsi-adfr-min-fps-0-command-state = "dsi_hs_mode";
			qcom,mdss-dsi-adfr-min-fps-1-command-state = "dsi_hs_mode";
			qcom,mdss-dsi-adfr-min-fps-2-command-state = "dsi_hs_mode";
			qcom,mdss-dsi-adfr-min-fps-3-command-state = "dsi_hs_mode";
			qcom,mdss-dsi-adfr-min-fps-4-command-state = "dsi_hs_mode";
			qcom,mdss-dsi-adfr-min-fps-5-command-state = "dsi_hs_mode";
			qcom,mdss-dsi-hpwm-adfr-min-fps-0-command-state = "dsi_hs_mode";
			qcom,mdss-dsi-hpwm-adfr-min-fps-1-command-state = "dsi_hs_mode";
			qcom,mdss-dsi-hpwm-adfr-min-fps-2-command-state = "dsi_hs_mode";
			qcom,mdss-dsi-hpwm-adfr-min-fps-3-command-state = "dsi_hs_mode";
			qcom,mdss-dsi-hpwm-adfr-min-fps-4-command-state = "dsi_hs_mode";
			qcom,mdss-dsi-hpwm-adfr-min-fps-5-command-state = "dsi_hs_mode";
			qcom,mdss-dsi-bigdc-adfr-min-fps-0-command-state = "dsi_hs_mode";
			qcom,mdss-dsi-bigdc-adfr-min-fps-1-command-state = "dsi_hs_mode";
			qcom,mdss-dsi-bigdc-adfr-min-fps-2-command-state = "dsi_hs_mode";
			qcom,mdss-dsi-bigdc-adfr-min-fps-3-command-state = "dsi_hs_mode";
			qcom,mdss-dsi-bigdc-adfr-min-fps-4-command-state = "dsi_hs_mode";
			qcom,mdss-dsi-bigdc-adfr-min-fps-5-command-state = "dsi_hs_mode";
		};
		timing@sdc_fhd_60 { /* FHD+ 120hz 1094.4Mbps */
			/* standard adfr */
			qcom,mdss-dsi-h-sync-skew = <1>;
			oplus,adfr-min-fps-mapping-table = <60 30 20 10 1>;
			oplus,adfr-idle-off-min-fps = <20>;

			qcom,mdss-dsi-adfr-min-fps-0-command = [
				39 00 00 40 00 00 04 FF 5A A5 2D
				39 00 00 40 00 00 03 83 01 00
				39 00 00 00 00 00 04 FF 5A A5 00
			];
			qcom,mdss-dsi-adfr-min-fps-1-command = [
				39 00 00 40 00 00 04 FF 5A A5 2D
				39 00 00 40 00 00 03 83 03 00
				39 00 00 00 00 00 04 FF 5A A5 00
			];
			qcom,mdss-dsi-adfr-min-fps-2-command = [
				39 00 00 40 00 00 04 FF 5A A5 2D
				39 00 00 40 00 00 03 83 05 00
				39 00 00 00 00 00 04 FF 5A A5 00
			];
			qcom,mdss-dsi-adfr-min-fps-3-command = [
				39 00 00 40 00 00 04 FF 5A A5 2D
				39 00 00 40 00 00 03 83 0B 00
				39 00 00 00 00 00 04 FF 5A A5 00
			];
			qcom,mdss-dsi-adfr-min-fps-4-command = [
				39 00 00 40 00 00 04 FF 5A A5 2D
				39 00 00 40 00 00 03 83 77 00
				39 00 00 00 00 00 04 FF 5A A5 00
			];
			qcom,mdss-dsi-hpwm-adfr-min-fps-0-command = [
				39 00 00 40 00 00 04 FF 5A A5 2D
				39 00 00 40 00 00 03 83 01 00
				39 00 00 00 00 00 04 FF 5A A5 00
			];
			qcom,mdss-dsi-hpwm-adfr-min-fps-1-command = [
				39 00 00 40 00 00 04 FF 5A A5 2D
				39 00 00 40 00 00 03 83 03 00
				39 00 00 00 00 00 04 FF 5A A5 00
			];
			qcom,mdss-dsi-hpwm-adfr-min-fps-2-command = [
				39 00 00 40 00 00 04 FF 5A A5 2D
				39 00 00 40 00 00 03 83 05 00
				39 00 00 00 00 00 04 FF 5A A5 00
			];
			qcom,mdss-dsi-hpwm-adfr-min-fps-3-command = [
				39 00 00 40 00 00 04 FF 5A A5 2D
				39 00 00 40 00 00 03 83 0B 00
				39 00 00 00 00 00 04 FF 5A A5 00
			];
			qcom,mdss-dsi-hpwm-adfr-min-fps-4-command = [
				39 00 00 40 00 00 04 FF 5A A5 2D
				39 00 00 40 00 00 03 83 77 00
				39 00 00 00 00 00 04 FF 5A A5 00
			];
			qcom,mdss-dsi-bigdc-adfr-min-fps-0-command = [
				39 00 00 40 00 00 04 FF 5A A5 2D
				39 00 00 40 00 00 03 84 01 00
				39 00 00 00 00 00 04 FF 5A A5 00
			];
			qcom,mdss-dsi-bigdc-adfr-min-fps-1-command = [
				39 00 00 40 00 00 04 FF 5A A5 2D
				39 00 00 40 00 00 03 84 03 00
				39 00 00 00 00 00 04 FF 5A A5 00
			];
			qcom,mdss-dsi-bigdc-adfr-min-fps-2-command = [
				39 00 00 40 00 00 04 FF 5A A5 2D
				39 00 00 40 00 00 03 84 05 00
				39 00 00 00 00 00 04 FF 5A A5 00
			];
			qcom,mdss-dsi-bigdc-adfr-min-fps-3-command = [
				39 00 00 40 00 00 04 FF 5A A5 2D
				39 00 00 40 00 00 03 84 0B 00
				39 00 00 00 00 00 04 FF 5A A5 00
			];
			qcom,mdss-dsi-bigdc-adfr-min-fps-4-command = [
				39 00 00 40 00 00 04 FF 5A A5 2D
				39 00 00 40 00 00 03 84 77 00
				39 00 00 00 00 00 04 FF 5A A5 00
			];

			qcom,mdss-dsi-adfr-min-fps-0-command-state = "dsi_hs_mode";
			qcom,mdss-dsi-adfr-min-fps-1-command-state = "dsi_hs_mode";
			qcom,mdss-dsi-adfr-min-fps-2-command-state = "dsi_hs_mode";
			qcom,mdss-dsi-adfr-min-fps-3-command-state = "dsi_hs_mode";
			qcom,mdss-dsi-adfr-min-fps-4-command-state = "dsi_hs_mode";
			qcom,mdss-dsi-hpwm-adfr-min-fps-0-command-state = "dsi_hs_mode";
			qcom,mdss-dsi-hpwm-adfr-min-fps-1-command-state = "dsi_hs_mode";
			qcom,mdss-dsi-hpwm-adfr-min-fps-2-command-state = "dsi_hs_mode";
			qcom,mdss-dsi-hpwm-adfr-min-fps-3-command-state = "dsi_hs_mode";
			qcom,mdss-dsi-hpwm-adfr-min-fps-4-command-state = "dsi_hs_mode";
			qcom,mdss-dsi-bigdc-adfr-min-fps-0-command-state = "dsi_hs_mode";
			qcom,mdss-dsi-bigdc-adfr-min-fps-1-command-state = "dsi_hs_mode";
			qcom,mdss-dsi-bigdc-adfr-min-fps-2-command-state = "dsi_hs_mode";
			qcom,mdss-dsi-bigdc-adfr-min-fps-3-command-state = "dsi_hs_mode";
			qcom,mdss-dsi-bigdc-adfr-min-fps-4-command-state = "dsi_hs_mode";
		};
		timing@oplus_fhd_120 { /* FHD+ 120hz 1094.4Mbps */
			/* oplus adfr */
			qcom,mdss-dsi-h-sync-skew = <2>;
			oplus,adfr-min-fps-mapping-table = <120 30>;
			oplus,adfr-high-precision-fps-mapping-table = <120 90 60>;
			oplus,adfr-osync-hw-stabilize-frame-config-table = <120 90 60>;

			qcom,mdss-dsi-qsync-on-commands = [
				39 00 00 40 00 00 04 FF 5A A5 2D
				39 00 00 40 00 00 03 83 00 00
				39 00 00 40 00 00 03 84 00 00
				39 00 00 40 00 00 04 FF 5A A5 02
				39 00 00 40 00 00 05 B0 00 88 00 10
				39 00 00 00 00 00 04 FF 5A A5 00
			];
			qcom,mdss-dsi-qsync-off-commands = [
				39 00 00 40 00 00 04 FF 5A A5 2D
				39 00 00 40 00 00 03 83 00 00
				39 00 00 40 00 00 03 84 00 00
				39 00 00 40 00 00 04 FF 5A A5 02
				39 00 00 40 00 00 05 B0 00 80 00 10
				39 00 00 40 00 00 04 FF 5A A5 2D
				39 00 00 40 00 00 04 EC 01 AF 00
				39 00 00 00 00 00 04 FF 5A A5 00
			];
			qcom,mdss-dsi-adfr-min-fps-0-command = [
				39 00 00 40 00 00 04 FF 5A A5 2D
				39 00 00 40 00 00 04 EC 01 AE 00
				39 00 00 40 00 00 11 EF 00 00 00 00 00 00 00 00 00 00 00 00 00 00 00 00
				39 00 00 00 00 00 04 FF 5A A5 00
			];
			qcom,mdss-dsi-adfr-min-fps-1-command = [
				39 00 00 40 00 00 04 FF 5A A5 2D
				39 00 00 40 00 00 04 EC 01 AE 00
				39 00 00 40 00 00 11 EF 00 00 00 00 00 00 00 00 00 00 00 00 00 00 00 09
				39 00 00 00 00 00 04 FF 5A A5 00
			];
			qcom,mdss-dsi-hpwm-adfr-min-fps-0-command = [
				39 00 00 40 00 00 04 FF 5A A5 2D
				39 00 00 40 00 00 04 EC 01 AF 00
				39 00 00 40 00 00 03 83 00 00
				39 00 00 00 00 00 04 FF 5A A5 00
			];
			qcom,mdss-dsi-hpwm-adfr-min-fps-1-command = [
				39 00 00 40 00 00 04 FF 5A A5 2D
				39 00 00 40 00 00 04 EC 01 AF 00
				39 00 00 40 00 00 03 83 03 00
				39 00 00 00 00 00 04 FF 5A A5 00
			];
			qcom,mdss-dsi-bigdc-adfr-min-fps-0-command = [
				39 00 00 40 00 00 04 FF 5A A5 2D
				39 00 00 40 00 00 04 EC 01 AF 00
				39 00 00 40 00 00 03 84 00 00
				39 00 00 00 00 00 04 FF 5A A5 00
			];
			qcom,mdss-dsi-bigdc-adfr-min-fps-1-command = [
				39 00 00 40 00 00 04 FF 5A A5 2D
				39 00 00 40 00 00 04 EC 01 AF 00
				39 00 00 40 00 00 03 84 03 00
				39 00 00 00 00 00 04 FF 5A A5 00
			];
			qcom,mdss-dsi-adfr-high-precision-fps-0-command = [
				39 00 00 40 00 00 04 FF 5A A5 2D
				39 00 00 40 00 00 18 EF 00 00 00 00 00 00 00 00 00 00 00 00 00 00 00 09 00 00 00 02 02 00 00
				39 00 00 00 00 00 04 FF 5A A5 00
			];
			qcom,mdss-dsi-adfr-high-precision-fps-1-command = [
				39 00 00 40 00 00 04 FF 5A A5 2D
				39 00 00 40 00 00 18 EF 00 00 00 00 00 00 00 00 00 00 00 00 00 00 00 09 00 10 06 02 02 00 00
				39 00 00 00 00 00 04 FF 5A A5 00
			];
			qcom,mdss-dsi-adfr-high-precision-fps-2-command = [
				39 00 00 40 00 00 04 FF 5A A5 2D
				39 00 00 40 00 00 18 EF 00 00 00 00 00 00 00 00 00 00 00 00 00 00 00 09 00 10 0E 02 02 00 00
				39 00 00 00 00 00 04 FF 5A A5 00
			];
			qcom,mdss-dsi-hpwm-adfr-high-precision-fps-0-command = [
				39 00 00 40 00 00 04 FF 5A A5 2D
				39 00 00 40 00 00 04 EC 01 AF 00
				39 00 00 40 00 00 18 EF 00 00 00 00 00 00 00 00 00 00 00 00 00 00 00 00 00 00 00 00 00 00 00
				39 00 00 00 00 00 04 FF 5A A5 00
			];
			qcom,mdss-dsi-hpwm-adfr-high-precision-fps-1-command = [
				39 00 00 40 00 00 04 FF 5A A5 2D
				39 00 00 40 00 00 04 EC 01 AF 00
				39 00 00 40 00 00 18 EF 00 00 00 00 00 00 00 00 00 00 00 00 00 00 00 00 00 00 00 00 00 00 00
				39 00 00 00 00 00 04 FF 5A A5 00
			];
			qcom,mdss-dsi-hpwm-adfr-high-precision-fps-2-command = [
				39 00 00 40 00 00 04 FF 5A A5 2D
				39 00 00 40 00 00 04 EC 01 AF 00
				39 00 00 40 00 00 18 EF 00 00 00 00 00 00 00 00 00 00 00 00 00 00 00 00 00 00 00 00 00 00 00
				39 00 00 00 00 00 04 FF 5A A5 00
			];
			qcom,mdss-dsi-bigdc-adfr-high-precision-fps-0-command = [
				39 00 00 40 00 00 04 FF 5A A5 2D
				39 00 00 40 00 00 04 EC 01 AF 00
				39 00 00 40 00 00 18 EF 00 00 00 00 00 00 00 00 00 00 00 00 00 00 00 00 00 00 00 00 00 00 00
				39 00 00 00 00 00 04 FF 5A A5 00
			];
			qcom,mdss-dsi-bigdc-adfr-high-precision-fps-1-command = [
				39 00 00 40 00 00 04 FF 5A A5 2D
				39 00 00 40 00 00 04 EC 01 AF 00
				39 00 00 40 00 00 18 EF 00 00 00 00 00 00 00 00 00 00 00 00 00 00 00 00 00 00 00 00 00 00 00
				39 00 00 00 00 00 04 FF 5A A5 00
			];
			qcom,mdss-dsi-bigdc-adfr-high-precision-fps-2-command = [
				39 00 00 40 00 00 04 FF 5A A5 2D
				39 00 00 40 00 00 04 EC 01 AF 00
				39 00 00 40 00 00 18 EF 00 00 00 00 00 00 00 00 00 00 00 00 00 00 00 00 00 00 00 00 00 00 00
				39 00 00 00 00 00 04 FF 5A A5 00
			];

			qcom,mdss-dsi-qsync-on-commands-state ="dsi_hs_mode";
			qcom,mdss-dsi-qsync-off-commands-state ="dsi_hs_mode";
			qcom,mdss-dsi-adfr-min-fps-0-command-state = "dsi_hs_mode";
			qcom,mdss-dsi-adfr-min-fps-1-command-state = "dsi_hs_mode";
			qcom,mdss-dsi-hpwm-adfr-min-fps-0-command-state = "dsi_hs_mode";
			qcom,mdss-dsi-hpwm-adfr-min-fps-1-command-state = "dsi_hs_mode";
			qcom,mdss-dsi-bigdc-adfr-min-fps-0-command-state = "dsi_hs_mode";
			qcom,mdss-dsi-bigdc-adfr-min-fps-1-command-state = "dsi_hs_mode";
			qcom,mdss-dsi-adfr-high-precision-fps-0-command-state = "dsi_hs_mode";
			qcom,mdss-dsi-adfr-high-precision-fps-1-command-state = "dsi_hs_mode";
			qcom,mdss-dsi-adfr-high-precision-fps-2-command-state = "dsi_hs_mode";
			qcom,mdss-dsi-hpwm-adfr-high-precision-fps-0-command-state = "dsi_hs_mode";
			qcom,mdss-dsi-hpwm-adfr-high-precision-fps-1-command-state = "dsi_hs_mode";
			qcom,mdss-dsi-hpwm-adfr-high-precision-fps-2-command-state = "dsi_hs_mode";
			qcom,mdss-dsi-bigdc-adfr-high-precision-fps-0-command-state = "dsi_hs_mode";
			qcom,mdss-dsi-bigdc-adfr-high-precision-fps-1-command-state = "dsi_hs_mode";
			qcom,mdss-dsi-bigdc-adfr-high-precision-fps-2-command-state = "dsi_hs_mode";
		};
	};
};

&dsi_panel_AA577_P_3_A0020_dsc_cmd {
	qcom,panel_voltage_vddi_name = "vddio";
	qcom,panel_voltage_vddi = <0 1800000 1850000 1950000>;
	qcom,panel_voltage_vddr_name = "vddio";
	qcom,panel_voltage_vddr = <1 1800000 1850000 1950000>;
};

&dsi_panel_AA577_P_3_A0020_dsc_cmd{
	oplus,color_vivid_status;
	oplus,color_srgb_status;
	oplus,color_softiris_status;
	oplus,color_dual_brightness_status;
	oplus,color_2nit_status;
	oplus,color_oplus_calibrate_status;
	oplus,color_samsung_status;
	oplus,color_loading_status;
	oplus,color_nature_profession_status;
	oplus,mdss-dsi-panel-type = <0>;

	/* serial num config */
	oplus,dsi-serial-number-enabled;
	oplus,dsi-serial-number-switch-page;
	oplus,dsi-serial-number-index= <0>;
	oplus,dsi-serial-number-reg= <0x82>;
	oplus,dsi-serial-number-read-count= <7>;

	/* demura dbv config */
	oplus,bl_denura-dbv-switch-support;

	/*Feature config*/
	oplus,pwm-switch-support;
	oplus,pwm-switch-wait-te-tx;
	oplus,pwm-switch-restore-support;
	oplus,pwm-switch-backlight-threshold = <1162>;
	oplus,pwm-create-thread-disable-duty;
	// oplus,cmdq-pack-support;
	oplus,pwm-onepulse-support;
	// oplus,directional-onepulse-switch;
	oplus,pwm-switch-support-dc;
	//oplus,dp-enabled;
};
